VERSION ""

NS_ :

BS_:

BU_: ACCL BGW DBPC DCFL DCFR DCRL DCRR DSM ECPM FBCM FFL FLDC FRDC HLL HLR HUD IHUB LGL PBPC PSM RCLL RCLR RLDC RLSM RRDC RRSM TOOL RCCL RCCR SCAM DEMFL DEMFR DEMRL DEMRR DOSFL DOSFR DOSRL DOSRR

BO_ 1160 DCFR_DemEvent3: 8 DCFR
 SG_ demIRSensor2MIA_DCFR : 57|2@0+ (1,0) [0|0] ""  TOOL
 SG_ demIRSensor1MIA_DCFR : 59|2@0+ (1,0) [0|0] ""  TOOL
 SG_ demWinSwErr_DCFR : 61|2@0+ (1,0) [0|0] ""  TOOL
 SG_ demWinSwMIA_DCFR : 63|2@0+ (1,0) [0|0] ""  TOOL
 SG_ demLINNetworkFail_DCFR : 49|2@0+ (1,0) [0|0] ""  TOOL
 SG_ demBodyCANAmbTempMsgErr_DCFR : 51|2@0+ (1,0) [0|0] ""  TOOL
 SG_ demBodyCANAmbTempMsgMiss_DCFR : 53|2@0+ (1,0) [0|0] ""  TOOL
 SG_ demBodyCANCrashMsgErr_DCFR : 55|2@0+ (1,0) [0|0] ""  TOOL
 SG_ demBodyCANCrashMsgMiss_DCFR : 41|2@0+ (1,0) [0|0] ""  TOOL
 SG_ demBodyCANChildLkMsgErr_DCFR : 43|2@0+ (1,0) [0|0] ""  TOOL
 SG_ demBodyCANChildLkMsgMiss_DCFR : 45|2@0+ (1,0) [0|0] ""  TOOL
 SG_ demBodyCANLockMessageError_DCFR : 47|2@0+ (1,0) [0|0] ""  TOOL
 SG_ demBodyCANLkUnlkMsgMiss_DCFR : 33|2@0+ (1,0) [0|0] ""  TOOL
 SG_ demBodyCANOpClMsgErr_DCFR : 35|2@0+ (1,0) [0|0] ""  TOOL
 SG_ demBodyCANOpClMsgMiss_DCFR : 37|2@0+ (1,0) [0|0] ""  TOOL
 SG_ demBodyCANIMUMessageError_DCFR : 39|2@0+ (1,0) [0|0] ""  TOOL
 SG_ demBodyCANIMUMsgMiss_DCFR : 25|2@0+ (1,0) [0|0] ""  TOOL
 SG_ demBodyCANVehSpdMsgErr_DCFR : 27|2@0+ (1,0) [0|0] ""  TOOL
 SG_ demBodyCANVehSpdMsgMiss_DCFR : 29|2@0+ (1,0) [0|0] ""  TOOL
 SG_ demBodyCANNetworkFailure_DCFR : 31|2@0+ (1,0) [0|0] ""  TOOL
 SG_ demMirrorGlassPosSnsShCir_DCFR : 17|2@0+ (1,0) [0|0] ""  TOOL
 SG_ demMirrorGlassPosSnsOpenCir_DCFR : 19|2@0+ (1,0) [0|0] ""  TOOL
 SG_ demMirrorGlassPosSnsSnEr_DCFR : 21|2@0+ (1,0) [0|0] ""  TOOL
 SG_ demMirrorGlassPosSnsSnLoss_DCFR : 23|2@0+ (1,0) [0|0] ""  TOOL
 SG_ demMirrorGlassPosNotReached_DCFR : 9|2@0+ (1,0) [0|0] ""  TOOL
 SG_ demMirrorGlassMvtUcmd_DCFR : 11|2@0+ (1,0) [0|0] ""  TOOL
 SG_ demMirrorGlassMvFail_DCFR : 13|2@0+ (1,0) [0|0] ""  TOOL
 SG_ demIntOpenSwSnEr_DCFR : 15|2@0+ (1,0) [0|0] ""  TOOL
 SG_ demIntOpenSwSnLoss_DCFR : 1|2@0+ (1,0) [0|0] ""  TOOL
 SG_ demIntRelSwSnEr_DCFR : 3|2@0+ (1,0) [0|0] ""  TOOL
 SG_ demInteriorReleaseSwSnLoss_DCFR : 5|2@0+ (1,0) [0|0] ""  TOOL
 SG_ demDoorUnlockSwSnError_DCFR : 7|2@0+ (1,0) [0|0] ""  TOOL

BO_ 655 DCFR_DemEvent2: 8 DCFR
 SG_ demDoorLockSwitchSignalLoss_DCFR : 57|2@0+ (1,0) [0|0] ""  TOOL
 SG_ demDoorExtCapSwSnEr_DCFR : 59|2@0+ (1,0) [0|0] ""  TOOL
 SG_ demDoorExtCapSwSnLoss_DCFR : 61|2@0+ (1,0) [0|0] ""  TOOL
 SG_ demDoorExtCapSwPower_DCFR : 63|2@0+ (1,0) [0|0] ""  TOOL
 SG_ demDoorExtCapSwNoPower_DCFR : 49|2@0+ (1,0) [0|0] ""  TOOL
 SG_ demDoorExtMechSwSnEr_DCFR : 51|2@0+ (1,0) [0|0] ""  TOOL
 SG_ demDoorExtMechSwSnLoss_DCFR : 53|2@0+ (1,0) [0|0] ""  TOOL
 SG_ demDoorExtMechSwPower_DCFR : 55|2@0+ (1,0) [0|0] ""  TOOL
 SG_ demDoorExtMechSwPowerLoss_DCFR : 41|2@0+ (1,0) [0|0] ""  TOOL
 SG_ demWindowHallSignalError_DCFR : 43|2@0+ (1,0) [0|0] ""  TOOL
 SG_ demWindowHallSnsPowerLoss_DCFR : 45|2@0+ (1,0) [0|0] ""  TOOL
 SG_ demWindowHallSignalLoss_DCFR : 47|2@0+ (1,0) [0|0] ""  TOOL
 SG_ demWindowVelocityTimeout_DCFR : 33|2@0+ (1,0) [0|0] ""  TOOL
 SG_ demCinchCloseSignalError_DCFR : 35|2@0+ (1,0) [0|0] ""  TOOL
 SG_ demReverseCinchTimeout_DCFR : 37|2@0+ (1,0) [0|0] ""  TOOL
 SG_ demCinchOpenSignalError_DCFR : 39|2@0+ (1,0) [0|0] ""  TOOL
 SG_ demDoorCinchTimeout_DCFR : 25|2@0+ (1,0) [0|0] ""  TOOL
 SG_ demDoorLatchOpenAlwaysOn_DCFR : 27|2@0+ (1,0) [0|0] ""  TOOL
 SG_ demDoorLatchOpenPowerLoss_DCFR : 29|2@0+ (1,0) [0|0] ""  TOOL
 SG_ demDoorLatchOpenSignalError_DCFR : 31|2@0+ (1,0) [0|0] ""  TOOL
 SG_ demDoorLatchOpenSignalLoss_DCFR : 17|2@0+ (1,0) [0|0] ""  TOOL
 SG_ demDoorLatchPawlSignalError_DCFR : 19|2@0+ (1,0) [0|0] ""  TOOL
 SG_ demDoorLatchPawlSignalLoss_DCFR : 21|2@0+ (1,0) [0|0] ""  TOOL
 SG_ demDoorLatchSensorSnError_DCFR : 23|2@0+ (1,0) [0|0] ""  TOOL
 SG_ demDoorLatchAjarSigLoss_DCFR : 9|2@0+ (1,0) [0|0] ""  TOOL
 SG_ demDoorBrakeHallSnLoss_DCFR : 11|2@0+ (1,0) [0|0] ""  TOOL
 SG_ demDoorHallSensorSnErr_DCFR : 13|2@0+ (1,0) [0|0] ""  TOOL
 SG_ doorHallSensorSlow_DCFR : 15|2@0+ (1,0) [0|0] ""  TOOL
 SG_ demDoorHallSensorFast_DCFR : 1|2@0+ (1,0) [0|0] ""  TOOL
 SG_ demDoorHallSensorSignalLoss_DCFR : 3|2@0+ (1,0) [0|0] ""  TOOL
 SG_ demMirrorMovetUncmd_DCFR : 5|2@0+ (1,0) [0|0] ""  TOOL
 SG_ demMirrorMovementFailure_DCFR : 7|2@0+ (1,0) [0|0] ""  TOOL

BO_ 654 DCFR_DemEvent1: 8 DCFR
 SG_ demDEMNotification_DCFR : 31|2@0+ (1,0) [0|0] ""  TOOL
 SG_ demDEMAssert_DCFR : 1|2@0+ (1,0) [0|0] ""  TOOL
 SG_ demWindowDownFailure_DCFR : 57|2@0+ (1,0) [0|0] ""  TOOL
 SG_ demWindowDownUncommanded_DCFR : 59|2@0+ (1,0) [0|0] ""  TOOL
 SG_ demWindowUpUncommanded_DCFR : 61|2@0+ (1,0) [0|0] ""  TOOL
 SG_ demWindowUpFailure_DCFR : 63|2@0+ (1,0) [0|0] ""  TOOL
 SG_ demDoorCinchUncommanded_DCFR : 49|2@0+ (1,0) [0|0] ""  TOOL
 SG_ demDoorCinchReleaseFailure_DCFR : 51|2@0+ (1,0) [0|0] ""  TOOL
 SG_ demDoorMovementFault_DCFR : 53|2@0+ (1,0) [0|0] ""  TOOL
 SG_ demDoorCloseUncommanded_DCFR : 55|2@0+ (1,0) [0|0] ""  TOOL
 SG_ demDoorCloseFailure_DCFR : 41|2@0+ (1,0) [0|0] ""  TOOL
 SG_ demLatchTimeout_DCFR : 43|2@0+ (1,0) [0|0] ""  TOOL
 SG_ demDoorDirectionFault_DCFR : 45|2@0+ (1,0) [0|0] ""  TOOL
 SG_ demDoorOpenUncommanded_DCFR : 47|2@0+ (1,0) [0|0] ""  TOOL
 SG_ demDoorOpenFailure_DCFR : 33|2@0+ (1,0) [0|0] ""  TOOL
 SG_ demMirrorMotorSignalLoss_DCFR : 35|2@0+ (1,0) [0|0] ""  TOOL
 SG_ demMirrorMotorOvercurrent_DCFR : 37|2@0+ (1,0) [0|0] ""  TOOL
 SG_ demWindowMotorSignalLoss_DCFR : 39|2@0+ (1,0) [0|0] ""  TOOL
 SG_ demWindowCurrentFailure_DCFR : 25|2@0+ (1,0) [0|0] ""  TOOL
 SG_ demWindowMotorUndercurrent_DCFR : 27|2@0+ (1,0) [0|0] ""  TOOL
 SG_ demWindowMotorOvercurrent_DCFR : 29|2@0+ (1,0) [0|0] ""  TOOL
 SG_ demCinchMotorPowerLoss_DCFR : 17|2@0+ (1,0) [0|0] ""  TOOL
 SG_ demCinchMotorOvercurrent_DCFR : 19|2@0+ (1,0) [0|0] ""  TOOL
 SG_ demLatchUncommandedOpen_DCFR : 21|2@0+ (1,0) [0|0] ""  TOOL
 SG_ demDoorLatchStateError_DCFR : 23|2@0+ (1,0) [0|0] ""  TOOL
 SG_ demDoorLatchPowerLoss_DCFR : 9|2@0+ (1,0) [0|0] ""  TOOL
 SG_ demLatchMotorOvercurrent_DCFR : 11|2@0+ (1,0) [0|0] ""  TOOL
 SG_ demDoorBrakeMotorSignalLoss_DCFR : 13|2@0+ (1,0) [0|0] ""  TOOL
 SG_ demDoorBrakeOvercurrent_DCFR : 15|2@0+ (1,0) [0|0] ""  TOOL
 SG_ demDoorCurrentSignalLoss_DCFR : 3|2@0+ (1,0) [0|0] ""  TOOL
 SG_ demDoorMotorCurrentFailure_DCFR : 5|2@0+ (1,0) [0|0] ""  TOOL
 SG_ demDoorMotorOvercurrent_DCFR : 7|2@0+ (1,0) [0|0] ""  TOOL

BO_ 896 TOOL_OptionSelection: 1 TOOL
 SG_ changeBaudRate_TOOL : 7|3@0+ (1,0) [0|6] ""  ACCL,BGW,DBPC,DCFL,DCFR,DCRL,DCRR,DSM,ECPM,FBCM,FFL,FLDC,FRDC,HLL,HLR,HUD,IHUB,LGL,PBPC,PSM,RCCL,RCCR,RCLL,RCLR,RLDC,RLSM,RRDC,RRSM

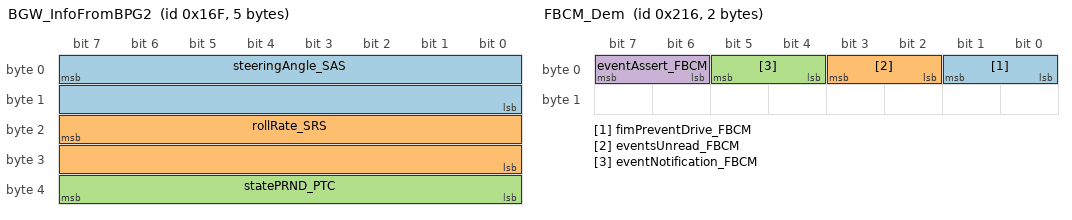
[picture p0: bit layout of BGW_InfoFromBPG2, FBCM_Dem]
BO_ 367 BGW_InfoFromBPG2: 5 BGW
 SG_ steeringAngle_SAS : 7|16@0- (0.1,0) [-780|779.9] "deg"  FBCM
 SG_ rollRate_SRS : 23|16@0+ (0.005,-163.85) [-163.85|163.82] "Grad/s"  DCFL,DCFR,DCRL,DCRR
 SG_ statePRND_PTC : 39|8@0+ (1,0) [0|3] ""  DBPC,DCRL,DCRR,DCFR,DCFL

BO_ 534 FBCM_Dem: 2 FBCM
 SG_ fimPreventDrive_FBCM : 1|2@0+ (1,0) [0|2] ""  TOOL
 SG_ eventsUnread_FBCM : 3|2@0+ (1,0) [0|2] ""  BGW,TOOL
 SG_ eventNotification_FBCM : 5|2@0+ (1,0) [0|2] ""  TOOL
 SG_ eventAssert_FBCM : 7|2@0+ (1,0) [0|2] ""  TOOL

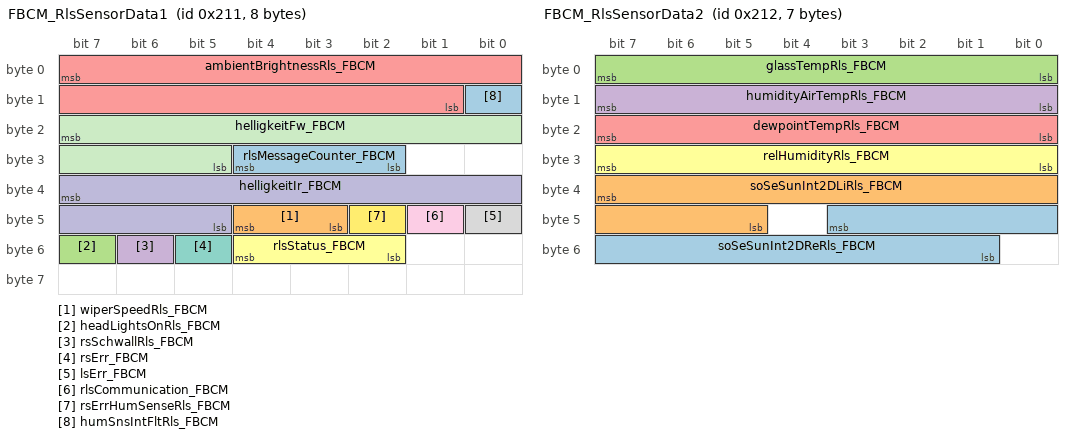
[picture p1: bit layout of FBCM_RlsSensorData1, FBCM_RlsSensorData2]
BO_ 529 FBCM_RlsSensorData1: 8 FBCM
 SG_ rlsMessageCounter_FBCM : 28|3@0+ (1,0) [0|7] ""  BGW
 SG_ wiperSpeedRls_FBCM : 44|2@0+ (1,0) [0|3] ""  BGW
 SG_ headLightsOnRls_FBCM : 55|1@0+ (1,0) [0|1] ""  BGW
 SG_ rsSchwallRls_FBCM : 54|1@0+ (1,0) [0|1] ""  BGW
 SG_ ambientBrightnessRls_FBCM : 7|15@0+ (1,0) [0|2047] ""  BGW
 SG_ rlsStatus_FBCM : 52|3@0+ (1,0) [0|7] ""  BGW
 SG_ rsErr_FBCM : 53|1@0+ (1,0) [0|1] ""  BGW
 SG_ lsErr_FBCM : 40|1@0+ (1,0) [0|1] ""  BGW
 SG_ rlsCommunication_FBCM : 41|1@0+ (1,0) [0|1] ""  BGW
 SG_ helligkeitIr_FBCM : 39|11@0+ (1,0) [0|2047] ""  BGW
 SG_ helligkeitFw_FBCM : 23|11@0+ (1,0) [0|2047] ""  BGW
 SG_ rsErrHumSenseRls_FBCM : 42|1@0+ (1,0) [0|1] ""  BGW
 SG_ humSnsIntFltRls_FBCM : 8|1@0+ (1,0) [0|1] ""  BGW

BO_ 530 FBCM_RlsSensorData2: 7 FBCM
 SG_ soSeSunInt2DReRls_FBCM : 43|11@0+ (1,0) [0|255] ""  BGW
 SG_ soSeSunInt2DLiRls_FBCM : 39|11@0+ (1,0) [0|255] ""  BGW
 SG_ glassTempRls_FBCM : 7|8@0+ (1,0) [0|255] ""  BGW
 SG_ humidityAirTempRls_FBCM : 15|8@0+ (1,0) [0|255] ""  BGW
 SG_ dewpointTempRls_FBCM : 23|8@0+ (1,0) [0|255] ""  BGW
 SG_ relHumidityRls_FBCM : 31|8@0+ (1,0) [0|255] ""  BGW

BO_ 716 DCRR_IMU: 4 DCRR
 SG_ imuRollAngle_DCRR : 23|14@0- (0.022,0) [-180|180] ""  BGW
 SG_ imuPitchAngle_DCRR : 7|14@0- (0.022,0) [-180|180] ""  BGW

BO_ 684 DCRL_IMU: 4 DCRL
 SG_ imuRollAngle_DCRL : 23|14@0- (0.022,0) [-180|180] ""  BGW
 SG_ imuPitchAngle_DCRL : 7|14@0- (0.022,0) [-180|180] ""  BGW

BO_ 652 DCFR_IMU: 4 DCFR
 SG_ imuRollAngle_DCFR : 23|14@0- (0.022,0) [-180|180] ""  BGW
 SG_ imuPitchAngle_DCFR : 7|14@0- (0.022,0) [-180|180] ""  BGW

BO_ 612 DCFL_IMU: 4 DCFL
 SG_ imuRollAngle_DCFL : 23|14@0- (0.022,0) [-180|180] ""  BGW
 SG_ imuPitchAngle_DCFL : 7|14@0- (0.022,0) [-180|180] ""  BGW

BO_ 14 BGW_VehicleIdNumber: 8 BGW
 SG_ vehicleIdNumberLo_BGW m0 : 7|56@0+ (1,0) [0|7.20575940379278E+016] ""  TOOL
 SG_ vehicleIdNumberHi_BGW m2 : 7|24@0+ (1,0) [0|16777214] ""  TOOL
 SG_ vehicleIdNumberIndex_BGW M : 63|2@0+ (1,0) [0|3] ""  TOOL
 SG_ vehicleIdNumberMid_BGW m1 : 7|56@0+ (1,0) [0|7.20575940379278E+016] ""  TOOL

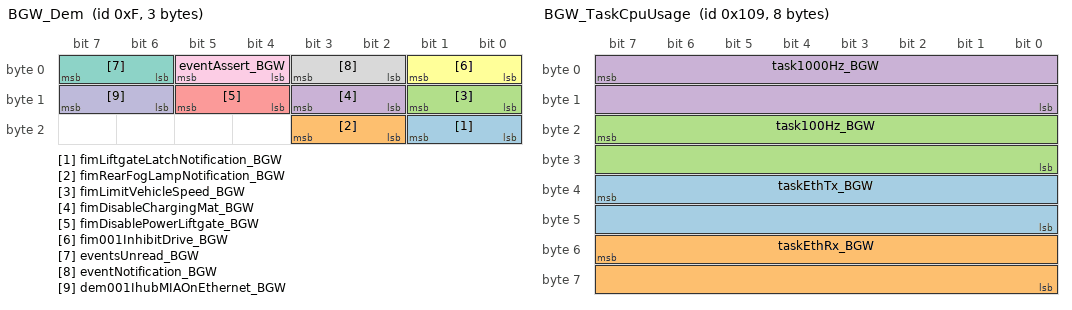
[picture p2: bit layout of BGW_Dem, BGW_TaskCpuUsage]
BO_ 15 BGW_Dem: 3 BGW
 SG_ fimLiftgateLatchNotification_BGW : 17|2@0+ (1,0) [0|2] ""  TOOL
 SG_ fimRearFogLampNotification_BGW : 19|2@0+ (1,0) [0|2] ""  TOOL
 SG_ fimLimitVehicleSpeed_BGW : 9|2@0+ (1,0) [0|2] ""  TOOL
 SG_ fimDisableChargingMat_BGW : 11|2@0+ (1,0) [0|2] ""  TOOL
 SG_ fimDisablePowerLiftgate_BGW : 13|2@0+ (1,0) [0|2] ""  TOOL
 SG_ fim001InhibitDrive_BGW : 1|2@0+ (1,0) [0|2] ""  TOOL
 SG_ eventsUnread_BGW : 7|2@0+ (1,0) [0|2] ""  TOOL
 SG_ eventNotification_BGW : 3|2@0+ (1,0) [0|2] ""  TOOL
 SG_ eventAssert_BGW : 5|2@0+ (1,0) [0|2] ""  TOOL
 SG_ dem001IhubMIAOnEthernet_BGW : 15|2@0+ (1,0) [0|2] ""  TOOL

BO_ 265 BGW_TaskCpuUsage: 8 BGW
 SG_ taskEthTx_BGW : 39|16@0+ (0.01,0) [0|100] "%"  TOOL
 SG_ taskEthRx_BGW : 55|16@0+ (0.01,0) [0|100] "%"  TOOL
 SG_ task100Hz_BGW : 23|16@0+ (0.01,0) [0|100] "%"  TOOL
 SG_ task1000Hz_BGW : 7|16@0+ (0.01,0) [0|100] "%"  TOOL

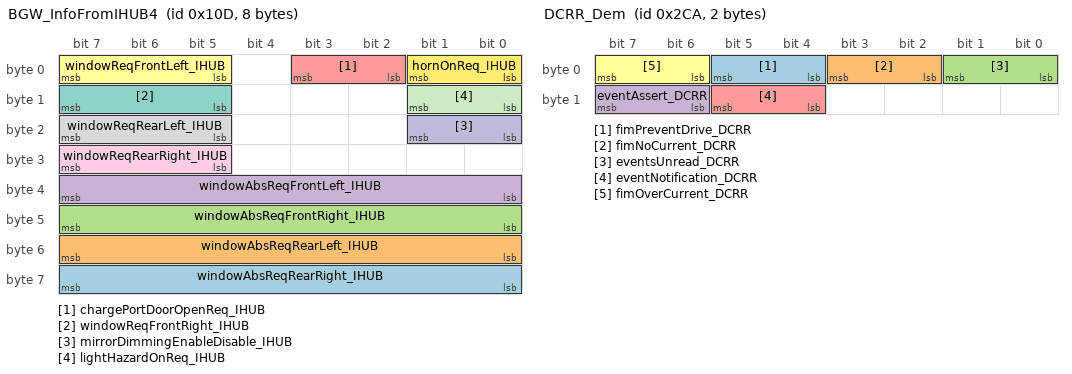
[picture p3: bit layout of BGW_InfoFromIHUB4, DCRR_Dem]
BO_ 269 BGW_InfoFromIHUB4: 8 BGW
 SG_ windowAbsReqRearRight_IHUB : 63|8@0+ (1,0) [0|100] ""  DCRR
 SG_ windowAbsReqRearLeft_IHUB : 55|8@0+ (1,0) [0|100] ""  DCRL
 SG_ windowAbsReqFrontRight_IHUB : 47|8@0+ (1,0) [0|100] ""  DCFR
 SG_ windowAbsReqFrontLeft_IHUB : 39|8@0+ (1,0) [0|100] ""  DCFL
 SG_ chargePortDoorOpenReq_IHUB : 3|2@0+ (1,0) [0|2] ""  FBCM
 SG_ windowReqFrontLeft_IHUB : 7|3@0+ (1,0) [0|4] ""  DCFL
 SG_ windowReqFrontRight_IHUB : 15|3@0+ (1,0) [0|4] ""  DCFR
 SG_ windowReqRearLeft_IHUB : 23|3@0+ (1,0) [0|4] ""  DCRL
 SG_ windowReqRearRight_IHUB : 31|3@0+ (1,0) [0|4] ""  DCRR
 SG_ mirrorDimmingEnableDisable_IHUB : 17|2@0+ (1,0) [0|2] ""  DCFL,DCFR
 SG_ lightHazardOnReq_IHUB : 9|2@0+ (1,0) [0|2] ""  FBCM
 SG_ hornOnReq_IHUB : 1|2@0+ (1,0) [0|2] ""  FBCM

BO_ 714 DCRR_Dem: 2 DCRR
 SG_ fimPreventDrive_DCRR : 5|2@0+ (1,0) [0|2] ""  TOOL
 SG_ fimNoCurrent_DCRR : 3|2@0+ (1,0) [0|2] ""  TOOL
 SG_ eventsUnread_DCRR : 1|2@0+ (1,0) [0|2] ""  BGW,TOOL
 SG_ eventAssert_DCRR : 15|2@0+ (1,0) [0|2] ""  TOOL
 SG_ eventNotification_DCRR : 13|2@0+ (1,0) [0|2] ""  TOOL
 SG_ fimOverCurrent_DCRR : 7|2@0+ (1,0) [0|2] ""  TOOL

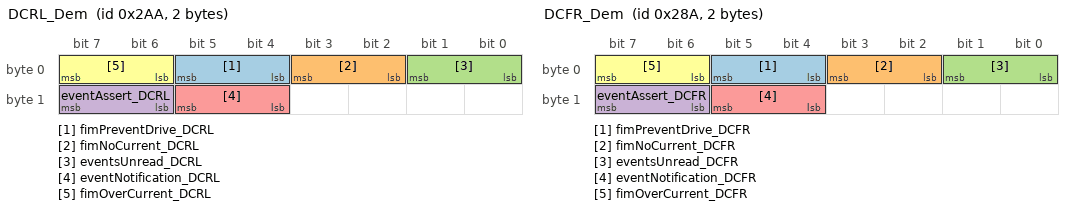
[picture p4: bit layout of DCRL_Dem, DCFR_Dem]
BO_ 682 DCRL_Dem: 2 DCRL
 SG_ fimPreventDrive_DCRL : 5|2@0+ (1,0) [0|2] ""  TOOL
 SG_ fimNoCurrent_DCRL : 3|2@0+ (1,0) [0|2] ""  TOOL
 SG_ eventsUnread_DCRL : 1|2@0+ (1,0) [0|2] ""  BGW,TOOL
 SG_ eventAssert_DCRL : 15|2@0+ (1,0) [0|2] ""  TOOL
 SG_ eventNotification_DCRL : 13|2@0+ (1,0) [0|2] ""  TOOL
 SG_ fimOverCurrent_DCRL : 7|2@0+ (1,0) [0|2] ""  TOOL

BO_ 650 DCFR_Dem: 2 DCFR
 SG_ fimPreventDrive_DCFR : 5|2@0+ (1,0) [0|2] ""  TOOL
 SG_ fimNoCurrent_DCFR : 3|2@0+ (1,0) [0|2] ""  TOOL
 SG_ eventsUnread_DCFR : 1|2@0+ (1,0) [0|2] ""  BGW,TOOL
 SG_ eventAssert_DCFR : 15|2@0+ (1,0) [0|2] ""  TOOL
 SG_ eventNotification_DCFR : 13|2@0+ (1,0) [0|2] ""  TOOL
 SG_ fimOverCurrent_DCFR : 7|2@0+ (1,0) [0|2] ""  TOOL

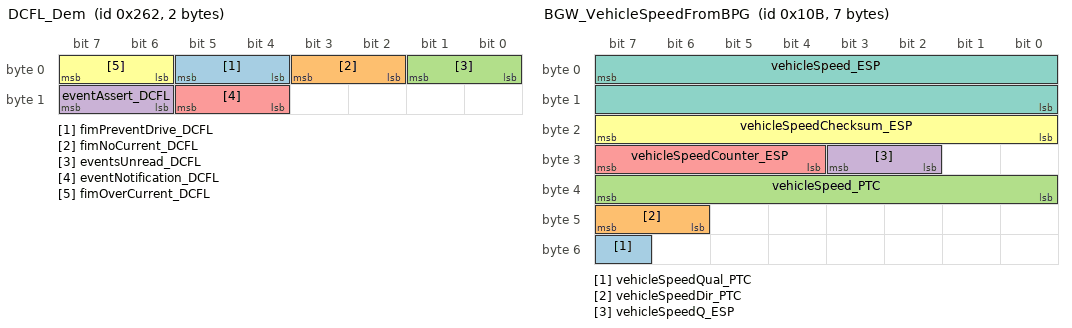
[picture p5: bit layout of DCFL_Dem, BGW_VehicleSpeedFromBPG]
BO_ 610 DCFL_Dem: 2 DCFL
 SG_ fimPreventDrive_DCFL : 5|2@0+ (1,0) [0|2] ""  TOOL
 SG_ fimNoCurrent_DCFL : 3|2@0+ (1,0) [0|2] ""  TOOL
 SG_ eventsUnread_DCFL : 1|2@0+ (1,0) [0|2] ""  BGW,TOOL
 SG_ eventAssert_DCFL : 15|2@0+ (1,0) [0|2] ""  TOOL
 SG_ eventNotification_DCFL : 13|2@0+ (1,0) [0|2] ""  TOOL
 SG_ fimOverCurrent_DCFL : 7|2@0+ (1,0) [0|2] ""  TOOL

BO_ 267 BGW_VehicleSpeedFromBPG: 7 BGW
 SG_ vehicleSpeedQual_PTC : 55|1@0+ (1,0) [0|1] ""  DCFL,DCFR,DCRL,DCRR
 SG_ vehicleSpeedDir_PTC : 47|2@0+ (1,0) [0|1] ""  DCFL,DCFR,DCRL,DCRR
 SG_ vehicleSpeed_PTC : 39|8@0+ (1,0) [0|254] ""  DCFL,DCFR,DCRL,DCRR
 SG_ vehicleSpeedQ_ESP : 27|2@0+ (1,0) [0|3] ""  DCFL,DCFR,DCRL,DCRR
 SG_ vehicleSpeedCounter_ESP : 31|4@0+ (1,0) [0|15] ""  DCFL,DCFR,DCRL,DCRR
 SG_ vehicleSpeedChecksum_ESP : 23|8@0+ (1,0) [0|255] ""  DCFL,DCFR,DCRL,DCRR
 SG_ vehicleSpeed_ESP : 7|16@0+ (0.01,0) [0|655.34] "km/h"  ECPM,FBCM,DCFL,DCFR,DCRL,DCRR

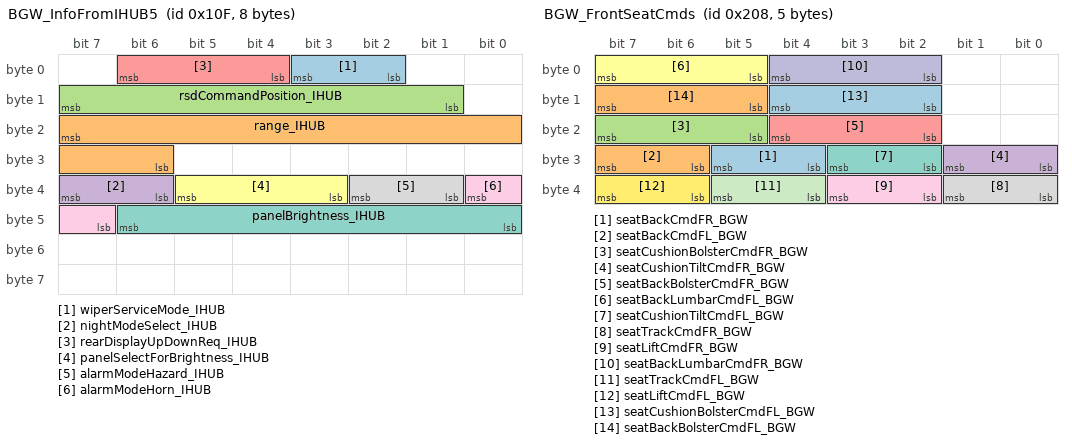
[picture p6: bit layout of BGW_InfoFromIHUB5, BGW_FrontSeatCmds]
BO_ 271 BGW_InfoFromIHUB5: 8 BGW
 SG_ wiperServiceMode_IHUB : 3|2@0+ (1,0) [0|0] ""  FBCM
 SG_ range_IHUB : 23|10@0+ (1,0) [0|800] "miles"  DBPC
 SG_ rsdCommandPosition_IHUB : 15|7@0+ (1,0) [0|105] ""  FBCM
 SG_ nightModeSelect_IHUB : 39|2@0+ (1,0) [0|1] ""  DBPC,ECPM
 SG_ rearDisplayUpDownReq_IHUB : 6|3@0+ (1,0) [0|7] ""  FBCM
 SG_ panelSelectForBrightness_IHUB : 37|3@0+ (1,0) [0|6] ""  DBPC
 SG_ panelBrightness_IHUB : 46|7@0+ (1,0) [0|100] ""  ECPM,DBPC
 SG_ alarmModeHazard_IHUB : 34|2@0+ (1,0) [0|2] ""  FBCM
 SG_ alarmModeHorn_IHUB : 32|2@0+ (1,0) [0|2] ""  FBCM

BO_ 520 BGW_FrontSeatCmds: 5 BGW
 SG_ seatBackCmdFR_BGW : 29|2@0+ (1,0) [0|0] ""  PSM
 SG_ seatBackCmdFL_BGW : 31|2@0+ (1,0) [0|0] ""  DSM
 SG_ seatCushionBolsterCmdFR_BGW : 23|3@0+ (1,0) [0|0] ""  PSM
 SG_ seatCushionTiltCmdFR_BGW : 25|2@0+ (1,0) [0|0] ""  PSM
 SG_ seatBackBolsterCmdFR_BGW : 20|3@0+ (1,0) [0|0] ""  PSM
 SG_ seatBackLumbarCmdFL_BGW : 7|3@0+ (1,0) [0|0] ""  DSM
 SG_ seatCushionTiltCmdFL_BGW : 27|2@0+ (1,0) [0|0] ""  DSM
 SG_ seatTrackCmdFR_BGW : 33|2@0+ (1,0) [0|2] ""  PSM
 SG_ seatLiftCmdFR_BGW : 35|2@0+ (1,0) [0|2] ""  PSM
 SG_ seatBackLumbarCmdFR_BGW : 4|3@0+ (1,0) [0|2] ""  PSM
 SG_ seatTrackCmdFL_BGW : 37|2@0+ (1,0) [0|2] ""  DSM
 SG_ seatLiftCmdFL_BGW : 39|2@0+ (1,0) [0|2] ""  DSM
 SG_ seatCushionBolsterCmdFL_BGW : 12|3@0+ (1,0) [0|4] ""  DSM
 SG_ seatBackBolsterCmdFL_BGW : 15|3@0+ (1,0) [0|4] ""  DSM

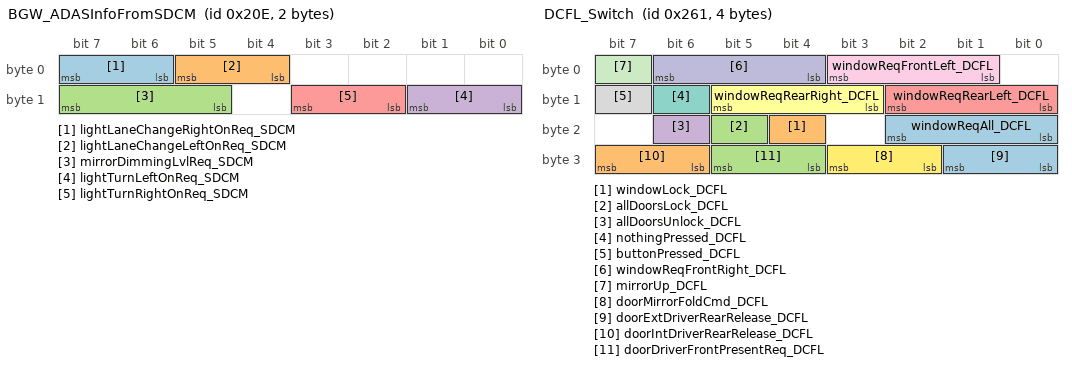
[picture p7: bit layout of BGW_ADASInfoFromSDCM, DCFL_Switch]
BO_ 526 BGW_ADASInfoFromSDCM: 2 BGW
 SG_ lightLaneChangeRightOnReq_SDCM : 7|2@0+ (1,0) [0|2] ""  FBCM
 SG_ lightLaneChangeLeftOnReq_SDCM : 5|2@0+ (1,0) [0|2] ""  FBCM
 SG_ mirrorDimmingLvlReq_SDCM : 15|3@0+ (1,0) [0|6] ""  DCFL,DCFR
 SG_ lightTurnLeftOnReq_SDCM : 9|2@0+ (1,0) [0|6] ""  FBCM
 SG_ lightTurnRightOnReq_SDCM : 11|2@0+ (1,0) [0|6] ""  FBCM

BO_ 608 DCFL_Status: 8 DCFL
 SG_ doorLockReq_DCFL : 55|2@0+ (1,0) [0|2] ""  BGW
 SG_ lockUnlockReq_FLLUS : 41|2@0+ (1,0) [0|2] ""  BGW
 SG_ doorSafeMode_DCFL : 53|2@0+ (1,0) [0|0] ""  FBCM,BGW
 SG_ doorLatchPawlOpen_DCFL : 48|2@0+ (1,0) [0|0] ""  TOOL
 SG_ doorLatchFault_DCFL : 23|2@0+ (1,0) [0|2] ""  BGW
 SG_ childLockButtonState_DCFL : 21|2@0+ (1,0) [0|2] ""  BGW,DCFL,DCFR,DCRL,DCRR
 SG_ doorIsUnlatched_DCFL : 31|2@0+ (1,0) [0|2] ""  HUD,FBCM,BGW,DCFR,DCRR,DCRL,IHUB
 SG_ doorExtSwitch_DCFL : 9|2@0+ (1,0) [0|2] ""  BGW
 SG_ doorMirrorState_DCFL : 7|3@0+ (1,0) [0|6] ""  ECPM,BGW
 SG_ doorState_DCFL : 13|4@0+ (1,0) [0|9] ""  ECPM,FBCM,BGW,DBPC
 SG_ mirrorHeaterState_DCFL : 15|2@0+ (1,0) [0|2] ""  ECPM,BGW
 SG_ sideRepeaterState_DCFL : 2|2@0+ (1,0) [0|2] ""  BGW
 SG_ doorDTCPresent_DCFL : 4|2@0+ (1,0) [0|2] ""  BGW
 SG_ windowStatusFl_DCFL : 19|3@0+ (1,0) [0|6] ""  BGW
 SG_ mirrorFoldFeedbackLeft_DCFL : 29|2@0+ (1,0) [0|2] ""  BGW
 SG_ mirrorDefrostGlassStatusLh_DCFL : 27|2@0+ (1,0) [0|2] ""  BGW
 SG_ mirrorStatusMovUpDownLeft_DCFL : 39|2@0+ (1,0) [0|2] ""  BGW
 SG_ mirrorStatusMovInOutLeft_DCFL : 37|2@0+ (1,0) [0|2] ""  BGW
 SG_ mirrorDefrostCamStatusLeft_DCFL : 35|2@0+ (1,0) [0|2] ""  BGW
 SG_ mirrorFoldAutoStatusLeft_DCFL : 25|2@0+ (1,0) [0|2] ""  BGW
 SG_ mirrorDimEnabDisableStatus_DCFL : 33|2@0+ (1,0) [0|2] ""  BGW
 SG_ errorAMPFL_DCFL : 16|1@0+ (1,0) [0|1] ""  BGW
 SG_ errorALDFL_DCFL : 0|1@0+ (1,0) [0|1] ""  BGW
 SG_ doorAngle_DCFL : 47|6@0- (2,40) [-24|100] "degrees"  BGW
 SG_ doorAngleMax_DCFL : 62|7@0+ (1,0) [0|126] "degrees"  BGW
 SG_ wakeUpCause_DCFL : 51|3@0+ (1,0) [0|7] ""  TOOL

BO_ 609 DCFL_Switch: 4 DCFL
 SG_ windowReqAll_DCFL : 18|3@0+ (1,0) [0|6] ""  DCRR,DCRL,DCFR,DCFL,TOOL
 SG_ windowLock_DCFL : 20|1@0+ (1,0) [0|1] ""  DCRR,DCRL,DCFR,DCFL,TOOL
 SG_ allDoorsLock_DCFL : 21|1@0+ (1,0) [0|1] ""  DCRR,DCRL,DCFR,DCFL,TOOL
 SG_ allDoorsUnlock_DCFL : 22|1@0+ (1,0) [0|1] ""  DCRR,DCRL,DCFR,DCFL,TOOL
 SG_ windowReqRearLeft_DCFL : 10|3@0+ (1,0) [0|6] ""  DCRR,DCFR,DCFL,DCRL
 SG_ windowReqRearRight_DCFL : 13|3@0+ (1,0) [0|6] ""  DCRL,DCFR,DCFL,DCRR
 SG_ nothingPressed_DCFL : 14|1@0+ (1,0) [0|1] ""  DCRR,DCRL,DCFR,DCFL,TOOL
 SG_ buttonPressed_DCFL : 15|1@0+ (1,0) [0|1] ""  DCRR,DCRL,DCFR,DCFL,TOOL
 SG_ windowReqFrontLeft_DCFL : 3|3@0+ (1,0) [0|6] ""  DCRR,DCRL,DCFR,DCFL,BGW
 SG_ windowReqFrontRight_DCFL : 6|3@0+ (1,0) [0|6] ""  DCRR,DCRL,DCFR,DCFL,BGW
 SG_ mirrorUp_DCFL : 7|1@0+ (1,0) [0|1] ""  DCRR,DCRL,DCFR,DCFL,TOOL
 SG_ doorMirrorFoldCmd_DCFL : 27|2@0+ (1,0) [0|2] ""  DCRR,DCRL,DCFL,BGW,DCFR
 SG_ doorExtDriverRearRelease_DCFL : 25|2@0+ (1,0) [0|2] ""  DCRR,DCRL,DCFR,DCFL,BGW,FBCM
 SG_ doorIntDriverRearRelease_DCFL : 31|2@0+ (1,0) [0|2] ""  DCRR,DCRL,DCFR,DCFL,BGW,FBCM
 SG_ doorDriverFrontPresentReq_DCFL : 29|2@0+ (1,0) [0|2] ""  DCRR,DCRL,DCFR,DCFL,BGW,FBCM

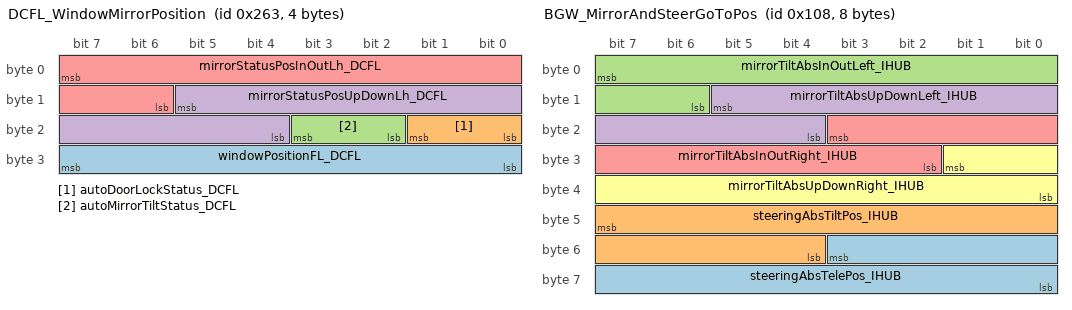
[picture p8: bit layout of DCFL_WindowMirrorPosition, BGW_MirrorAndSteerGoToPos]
BO_ 611 DCFL_WindowMirrorPosition: 4 DCFL
 SG_ windowPositionFL_DCFL : 31|8@0+ (1,0) [0|100] ""  BGW
 SG_ autoDoorLockStatus_DCFL : 17|2@0+ (1,0) [0|0] ""  BGW
 SG_ autoMirrorTiltStatus_DCFL : 19|2@0+ (1,0) [0|0] ""  BGW
 SG_ mirrorStatusPosUpDownLh_DCFL : 13|10@0+ (0.1,-38) [-38|38] "degrees"  BGW
 SG_ mirrorStatusPosInOutLh_DCFL : 7|10@0+ (0.1,-38) [-38|38] "degrees"  BGW

BO_ 264 BGW_MirrorAndSteerGoToPos: 8 BGW
 SG_ steeringAbsTelePos_IHUB : 51|12@0+ (1,0) [0|4095] "HallCounts"  FBCM
 SG_ steeringAbsTiltPos_IHUB : 47|12@0+ (1,0) [0|4095] "HallCounts"  FBCM
 SG_ mirrorTiltAbsInOutLeft_IHUB : 7|10@0+ (0.1,-38) [-38|38] "degrees"  DCFR,DCFL
 SG_ mirrorTiltAbsUpDownLeft_IHUB : 13|10@0+ (0.1,-38) [-38|38] "degrees"  DCFR,DCFL
 SG_ mirrorTiltAbsInOutRight_IHUB : 19|10@0+ (0.1,-38) [-38|38] "degrees"  DCFL,DCFR
 SG_ mirrorTiltAbsUpDownRight_IHUB : 25|10@0+ (0.1,-38) [-38|38] "degrees"  DCFR,DCFL

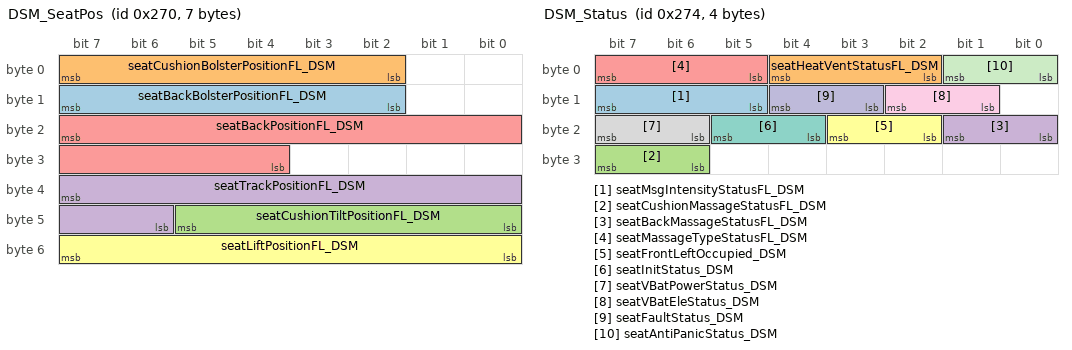
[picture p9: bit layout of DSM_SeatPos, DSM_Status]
BO_ 624 DSM_SeatPos: 7 DSM
 SG_ seatBackBolsterPositionFL_DSM : 15|6@0+ (0.1,0.4) [0.4|2.4] "V"  BGW
 SG_ seatCushionBolsterPositionFL_DSM : 7|6@0+ (0.1,0.4) [0.4|2.4] "V"  BGW
 SG_ seatCushionTiltPositionFL_DSM : 45|6@0+ (0.1,0) [0|6] "degrees"  BGW
 SG_ seatTrackPositionFL_DSM : 39|10@0- (1,0) [-75|185] "mm"  BGW
 SG_ seatBackPositionFL_DSM : 23|12@0- (0.1,0) [-22|43] "degrees"  BGW
 SG_ seatLiftPositionFL_DSM : 55|8@0- (1,0) [-20|54] "mm"  BGW

BO_ 628 DSM_Status: 4 DSM
 SG_ seatMsgIntensityStatusFL_DSM : 15|3@0+ (1,0) [0|0] ""  BGW
 SG_ seatHeatVentStatusFL_DSM : 4|3@0+ (1,0) [0|0] ""  BGW
 SG_ seatCushionMassageStatusFL_DSM : 31|2@0+ (1,0) [0|0] ""  BGW
 SG_ seatBackMassageStatusFL_DSM : 17|2@0+ (1,0) [0|0] ""  BGW
 SG_ seatMassageTypeStatusFL_DSM : 7|3@0+ (1,0) [0|0] ""  BGW
 SG_ seatFrontLeftOccupied_DSM : 19|2@0+ (1,0) [0|1] ""  HUD,FBCM,DCFL,BGW,IHUB
 SG_ seatInitStatus_DSM : 21|2@0+ (1,0) [0|2] ""  BGW
 SG_ seatVBatPowerStatus_DSM : 23|2@0+ (1,0) [0|1] ""  BGW
 SG_ seatVBatEleStatus_DSM : 10|2@0+ (1,0) [0|1] ""  BGW
 SG_ seatFaultStatus_DSM : 12|2@0+ (1,0) [0|2] ""  BGW
 SG_ seatAntiPanicStatus_DSM : 1|2@0+ (1,0) [0|2] ""  BGW

BO_ 648 DCFR_Status: 8 DCFR
 SG_ doorLockReq_DCFR : 55|2@0+ (1,0) [0|2] ""  BGW
 SG_ lockUnlockReq_FRLUS : 41|2@0+ (1,0) [0|2] ""  BGW
 SG_ doorSafeMode_DCFR : 53|2@0+ (1,0) [0|0] ""  FBCM,BGW
 SG_ doorLatchPawlOpen_DCFR : 48|2@0+ (1,0) [0|3] ""  TOOL
 SG_ doorLatchFault_DCFR : 23|2@0+ (1,0) [0|2] ""  BGW
 SG_ childLockButtonState_DCFR : 21|2@0+ (1,0) [0|2] ""  DCFL,DCFR,DCRL,DCRR,BGW
 SG_ doorIsUnlatched_DCFR : 31|2@0+ (1,0) [0|2] ""  HUD,FBCM,BGW,DCFL,DCRR,DCRL,IHUB
 SG_ doorExtSwitch_DCFR : 9|2@0+ (1,0) [0|2] ""  BGW
 SG_ doorMirrorState_DCFR : 7|3@0+ (1,0) [0|6] ""  ECPM,BGW
 SG_ doorState_DCFR : 13|4@0+ (1,0) [0|9] ""  ECPM,FBCM,BGW,DBPC
 SG_ mirrorHeaterState_DCFR : 15|2@0+ (1,0) [0|2] ""  ECPM,BGW
 SG_ sideRepeaterState_DCFR : 2|2@0+ (1,0) [0|2] ""  BGW
 SG_ doorDTCPresent_DCFR : 4|2@0+ (1,0) [0|2] ""  BGW
 SG_ windowStatusFr_DCFR : 19|3@0+ (1,0) [0|6] ""  BGW
 SG_ mirrorFoldFeedbackRight_DCFR : 29|2@0+ (1,0) [0|2] ""  BGW
 SG_ mirrorDefrostGlassStatusRh_DCFR : 27|2@0+ (1,0) [0|2] ""  BGW
 SG_ mirrorStatusMovUpDownRight_DCFR : 39|2@0+ (1,0) [0|2] ""  BGW
 SG_ mirrorStatusMovInOutRight_DCFR : 37|2@0+ (1,0) [0|2] ""  BGW
 SG_ mirrorDefrostCamStatusRight_DCFR : 35|2@0+ (1,0) [0|2] ""  BGW
 SG_ mirrorFoldAutoStatusRight_DCFR : 25|2@0+ (1,0) [0|2] ""  BGW
 SG_ mirrorDimEnabDisableStatus_DCFR : 33|2@0+ (1,0) [0|2] ""  BGW
 SG_ errorAMPFR_DCFR : 16|1@0+ (1,0) [0|1] ""  BGW
 SG_ errorALDFR_DCFR : 0|1@0+ (1,0) [0|1] ""  BGW
 SG_ doorAngle_DCFR : 47|6@0- (2,40) [-24|100] "degrees"  BGW
 SG_ doorAngleMax_DCFR : 62|7@0+ (1,0) [0|126] "degrees"  BGW
 SG_ wakeUpCause_DCFR : 51|3@0+ (1,0) [0|7] ""  TOOL

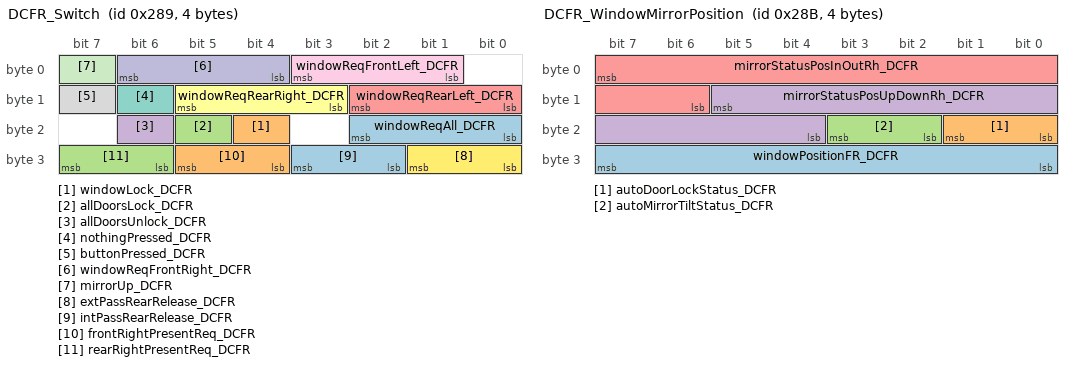
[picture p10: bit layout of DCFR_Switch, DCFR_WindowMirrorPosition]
BO_ 649 DCFR_Switch: 4 DCFR
 SG_ windowReqAll_DCFR : 18|3@0+ (1,0) [0|6] ""  DCRR,DCRL,DCFR,DCFL,TOOL
 SG_ windowLock_DCFR : 20|1@0+ (1,0) [0|1] ""  DCRR,DCRL,DCFR,DCFL,TOOL
 SG_ allDoorsLock_DCFR : 21|1@0+ (1,0) [0|1] ""  DCRR,DCRL,DCFR,DCFL,TOOL
 SG_ allDoorsUnlock_DCFR : 22|1@0+ (1,0) [0|1] ""  DCRR,DCRL,DCFR,DCFL,TOOL
 SG_ windowReqRearLeft_DCFR : 10|3@0+ (1,0) [0|6] ""  DCRR,DCFR,DCFL,DCRL
 SG_ windowReqRearRight_DCFR : 13|3@0+ (1,0) [0|6] ""  DCRL,DCFR,DCFL,DCRR
 SG_ nothingPressed_DCFR : 14|1@0+ (1,0) [0|1] ""  DCRR,DCRL,DCFR,DCFL,TOOL
 SG_ buttonPressed_DCFR : 15|1@0+ (1,0) [0|1] ""  DCRR,DCRL,DCFR,DCFL,TOOL
 SG_ windowReqFrontLeft_DCFR : 3|3@0+ (1,0) [0|6] ""  DCRR,DCRL,DCFR,DCFL,BGW
 SG_ windowReqFrontRight_DCFR : 6|3@0+ (1,0) [0|6] ""  DCRR,DCRL,DCFR,DCFL,BGW,TOOL
 SG_ mirrorUp_DCFR : 7|1@0+ (1,0) [0|1] ""  DCRR,DCRL,DCFR,DCFL,TOOL
 SG_ extPassRearRelease_DCFR : 25|2@0+ (1,0) [0|2] ""  DCRR,DCRL,DCFR,DCFL,FBCM
 SG_ intPassRearRelease_DCFR : 27|2@0+ (1,0) [0|2] ""  DCRR,DCRL,DCFR,DCFL,FBCM
 SG_ frontRightPresentReq_DCFR : 29|2@0+ (1,0) [0|2] ""  DCRR,DCRL,DCFR,DCFL,FBCM
 SG_ rearRightPresentReq_DCFR : 31|2@0+ (1,0) [0|2] ""  DCRR,DCRL,DCFR,DCFL,FBCM

BO_ 651 DCFR_WindowMirrorPosition: 4 DCFR
 SG_ windowPositionFR_DCFR : 31|8@0+ (1,0) [0|100] ""  BGW
 SG_ autoDoorLockStatus_DCFR : 17|2@0+ (1,0) [0|0] ""  BGW
 SG_ autoMirrorTiltStatus_DCFR : 19|2@0+ (1,0) [0|0] ""  BGW
 SG_ mirrorStatusPosUpDownRh_DCFR : 13|10@0+ (0.1,-38) [-38|38] "degrees"  BGW
 SG_ mirrorStatusPosInOutRh_DCFR : 7|10@0+ (0.1,-38) [-38|38] "degrees"  BGW

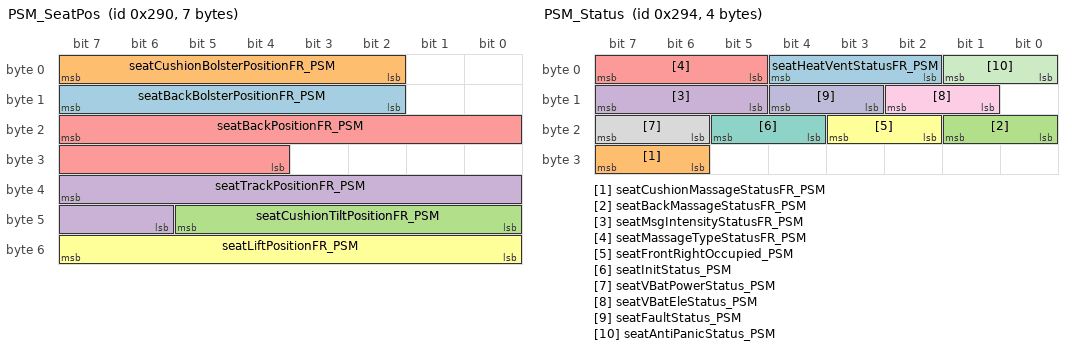
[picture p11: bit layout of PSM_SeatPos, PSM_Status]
BO_ 656 PSM_SeatPos: 7 PSM
 SG_ seatBackBolsterPositionFR_PSM : 15|6@0+ (0.1,0.4) [0.4|2.4] "V"  BGW
 SG_ seatCushionBolsterPositionFR_PSM : 7|6@0+ (0.1,0.4) [0.4|2.4] "V"  BGW
 SG_ seatCushionTiltPositionFR_PSM : 45|6@0+ (0.1,0) [0|6] "degrees"  BGW
 SG_ seatTrackPositionFR_PSM : 39|10@0- (1,0) [-75|185] "mm"  BGW
 SG_ seatBackPositionFR_PSM : 23|12@0- (0.1,0) [-20|54] "degrees"  BGW
 SG_ seatLiftPositionFR_PSM : 55|8@0- (1,0) [-22|43] "mm"  BGW

BO_ 660 PSM_Status: 4 PSM
 SG_ seatHeatVentStatusFR_PSM : 4|3@0+ (1,0) [0|0] ""  BGW
 SG_ seatCushionMassageStatusFR_PSM : 31|2@0+ (1,0) [0|0] ""  BGW
 SG_ seatBackMassageStatusFR_PSM : 17|2@0+ (1,0) [0|0] ""  BGW
 SG_ seatMsgIntensityStatusFR_PSM : 15|3@0+ (1,0) [0|0] ""  BGW
 SG_ seatMassageTypeStatusFR_PSM : 7|3@0+ (1,0) [0|0] ""  BGW
 SG_ seatFrontRightOccupied_PSM : 19|2@0+ (1,0) [0|1] ""  HUD,BGW,IHUB
 SG_ seatInitStatus_PSM : 21|2@0+ (1,0) [0|2] ""  BGW
 SG_ seatVBatPowerStatus_PSM : 23|2@0+ (1,0) [0|1] ""  BGW
 SG_ seatVBatEleStatus_PSM : 10|2@0+ (1,0) [0|1] ""  BGW
 SG_ seatFaultStatus_PSM : 12|2@0+ (1,0) [0|2] ""  BGW
 SG_ seatAntiPanicStatus_PSM : 1|2@0+ (1,0) [0|2] ""  BGW

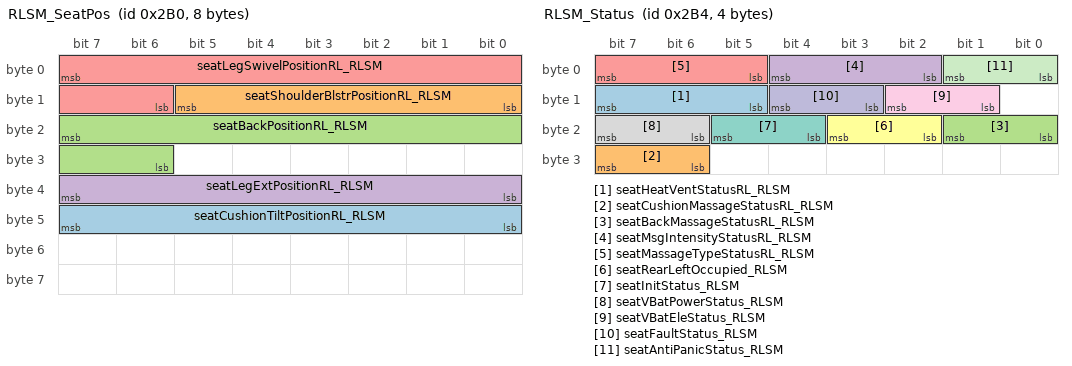
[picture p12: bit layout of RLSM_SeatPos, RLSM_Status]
BO_ 688 RLSM_SeatPos: 8 RLSM
 SG_ seatCushionTiltPositionRL_RLSM : 47|8@0+ (1,0) [0|20] "degrees"  BGW
 SG_ seatShoulderBlstrPositionRL_RLSM : 13|6@0+ (0.1,0.4) [0.4|2.4] "V"  BGW
 SG_ seatBackPositionRL_RLSM : 23|10@0- (0.1,0) [-8|32] "degrees"  BGW
 SG_ seatLegExtPositionRL_RLSM : 39|8@0+ (1,0) [0|130] "mm"  BGW
 SG_ seatLegSwivelPositionRL_RLSM : 7|10@0+ (0.1,0) [0|72.5] "degrees"  BGW

BO_ 692 RLSM_Status: 4 RLSM
 SG_ seatHeatVentStatusRL_RLSM : 15|3@0+ (1,0) [0|0] ""  BGW
 SG_ seatCushionMassageStatusRL_RLSM : 31|2@0+ (1,0) [0|0] ""  BGW
 SG_ seatBackMassageStatusRL_RLSM : 17|2@0+ (1,0) [0|0] ""  BGW
 SG_ seatMsgIntensityStatusRL_RLSM : 4|3@0+ (1,0) [0|0] ""  BGW
 SG_ seatMassageTypeStatusRL_RLSM : 7|3@0+ (1,0) [0|0] ""  BGW
 SG_ seatRearLeftOccupied_RLSM : 19|2@0+ (1,0) [0|1] ""  IHUB,HUD,BGW
 SG_ seatInitStatus_RLSM : 21|2@0+ (1,0) [0|2] ""  BGW
 SG_ seatVBatPowerStatus_RLSM : 23|2@0+ (1,0) [0|1] ""  BGW
 SG_ seatVBatEleStatus_RLSM : 10|2@0+ (1,0) [0|1] ""  BGW
 SG_ seatFaultStatus_RLSM : 12|2@0+ (1,0) [0|2] ""  BGW
 SG_ seatAntiPanicStatus_RLSM : 1|2@0+ (1,0) [0|2] ""  BGW

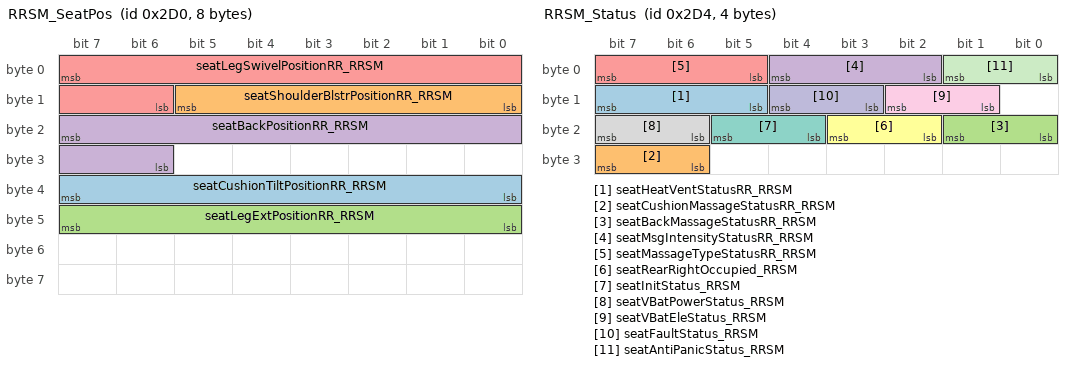
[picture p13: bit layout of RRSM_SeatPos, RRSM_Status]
BO_ 720 RRSM_SeatPos: 8 RRSM
 SG_ seatCushionTiltPositionRR_RRSM : 39|8@0+ (1,0) [0|20] "degrees"  BGW
 SG_ seatShoulderBlstrPositionRR_RRSM : 13|6@0+ (0.1,0.4) [0.4|2.4] "V"  BGW
 SG_ seatLegExtPositionRR_RRSM : 47|8@0+ (1,0) [0|130] "mm"  BGW
 SG_ seatBackPositionRR_RRSM : 23|10@0- (0.1,0) [-8|32] "degrees"  BGW
 SG_ seatLegSwivelPositionRR_RRSM : 7|10@0+ (0.1,0) [0|72.5] "degrees"  BGW

BO_ 724 RRSM_Status: 4 RRSM
 SG_ seatHeatVentStatusRR_RRSM : 15|3@0+ (1,0) [0|0] ""  BGW
 SG_ seatCushionMassageStatusRR_RRSM : 31|2@0+ (1,0) [0|0] ""  BGW
 SG_ seatBackMassageStatusRR_RRSM : 17|2@0+ (1,0) [0|0] ""  BGW
 SG_ seatMsgIntensityStatusRR_RRSM : 4|3@0+ (1,0) [0|0] ""  BGW
 SG_ seatMassageTypeStatusRR_RRSM : 7|3@0+ (1,0) [0|0] ""  BGW
 SG_ seatRearRightOccupied_RRSM : 19|2@0+ (1,0) [0|1] ""  IHUB,HUD,BGW
 SG_ seatInitStatus_RRSM : 21|2@0+ (1,0) [0|2] ""  BGW
 SG_ seatVBatPowerStatus_RRSM : 23|2@0+ (1,0) [0|1] ""  BGW
 SG_ seatVBatEleStatus_RRSM : 10|2@0+ (1,0) [0|1] ""  BGW
 SG_ seatFaultStatus_RRSM : 12|2@0+ (1,0) [0|2] ""  BGW
 SG_ seatAntiPanicStatus_RRSM : 1|2@0+ (1,0) [0|2] ""  BGW

BO_ 779 BGW_AestheticLightingCmd: 3 BGW
 SG_ sequenceId_BGW : 15|8@0+ (1,0) [0|254] ""  RRDC,RLDC,FRDC,FLDC,FFL,HLL,HLR,ACCL,LGL,RCLR,RCLL

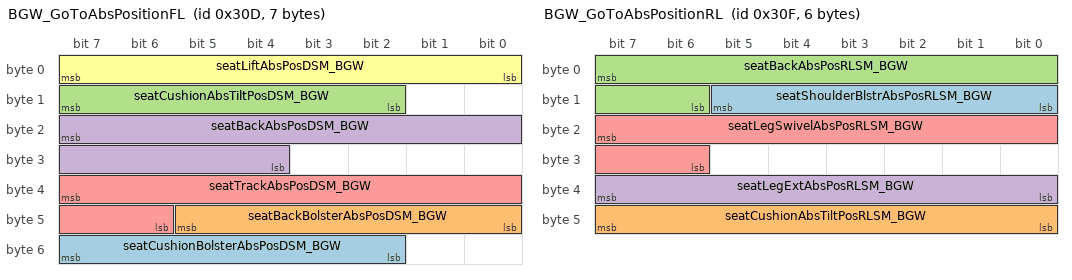
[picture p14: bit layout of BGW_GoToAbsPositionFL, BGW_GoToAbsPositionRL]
BO_ 781 BGW_GoToAbsPositionFL: 7 BGW
 SG_ seatCushionBolsterAbsPosDSM_BGW : 55|6@0+ (0.1,0.4) [0.4|2.4] "V"  DSM
 SG_ seatBackBolsterAbsPosDSM_BGW : 45|6@0+ (0.1,0.4) [0.4|2.4] "V"  DSM
 SG_ seatCushionAbsTiltPosDSM_BGW : 15|6@0+ (0.1,0) [0|6] "degrees"  DSM
 SG_ seatBackAbsPosDSM_BGW : 23|12@0- (0.1,0) [-20|54] "degrees"  DSM
 SG_ seatTrackAbsPosDSM_BGW : 39|10@0- (1,0) [-75|185] "mm"  DSM
 SG_ seatLiftAbsPosDSM_BGW : 7|8@0- (1,0) [-22|43] "mm"  DSM

BO_ 783 BGW_GoToAbsPositionRL: 6 BGW
 SG_ seatShoulderBlstrAbsPosRLSM_BGW : 13|6@0+ (0.1,0.4) [0.4|2.4] "V"  RLSM
 SG_ seatCushionAbsTiltPosRLSM_BGW : 47|8@0+ (0.1,0) [0|20] "degrees"  RLSM
 SG_ seatBackAbsPosRLSM_BGW : 7|10@0- (0.1,0) [-32|8] "degrees"  RLSM
 SG_ seatLegExtAbsPosRLSM_BGW : 39|8@0+ (1,0) [0|130] "mm"  RLSM
 SG_ seatLegSwivelAbsPosRLSM_BGW : 23|10@0+ (0.1,0) [0|72.5] "degrees"  RLSM

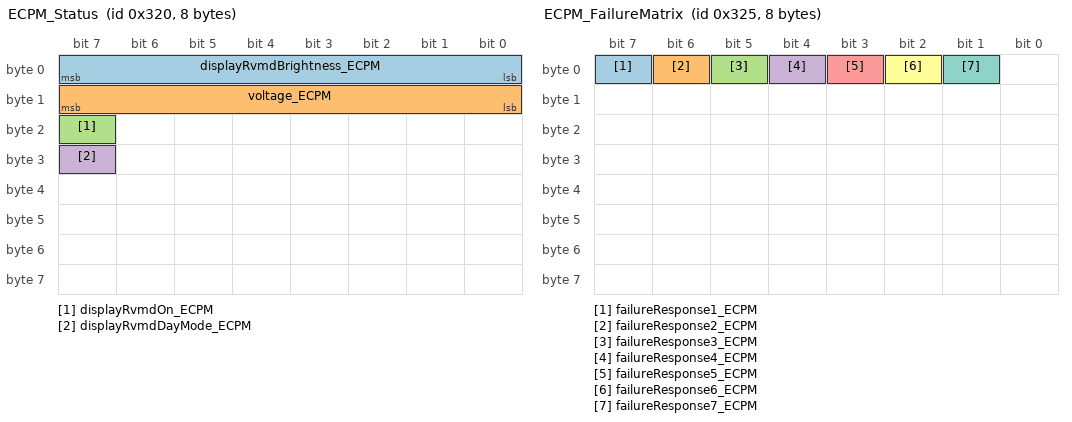
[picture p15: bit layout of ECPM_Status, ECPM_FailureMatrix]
BO_ 800 ECPM_Status: 8 ECPM
 SG_ displayRvmdBrightness_ECPM : 7|8@0+ (1,0) [0|100] ""  TOOL
 SG_ voltage_ECPM : 15|8@0+ (0.1,0) [0|25.4] ""  TOOL
 SG_ displayRvmdOn_ECPM : 23|1@0+ (1,0) [0|1] ""  TOOL
 SG_ displayRvmdDayMode_ECPM : 31|1@0+ (1,0) [0|1] ""  TOOL

BO_ 801 ECPM_DtcMatrix: 8 ECPM

BO_ 805 ECPM_FailureMatrix: 8 ECPM
 SG_ failureResponse1_ECPM : 7|1@0+ (1,0) [0|1] ""  TOOL
 SG_ failureResponse2_ECPM : 6|1@0+ (1,0) [0|1] ""  TOOL
 SG_ failureResponse3_ECPM : 5|1@0+ (1,0) [0|1] ""  TOOL
 SG_ failureResponse4_ECPM : 4|1@0+ (1,0) [0|1] ""  TOOL
 SG_ failureResponse5_ECPM : 3|1@0+ (1,0) [0|1] ""  TOOL
 SG_ failureResponse6_ECPM : 2|1@0+ (1,0) [0|1] ""  TOOL
 SG_ failureResponse7_ECPM : 1|1@0+ (1,0) [0|1] ""  TOOL

BO_ 807 ECPM_Debug: 8 ECPM

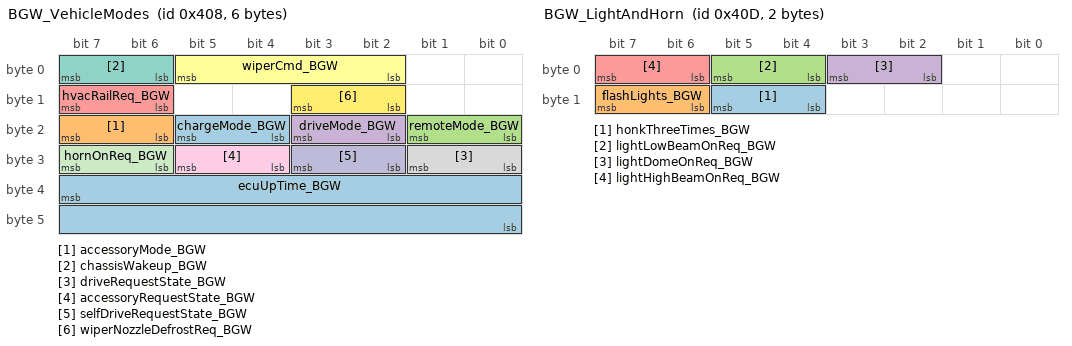
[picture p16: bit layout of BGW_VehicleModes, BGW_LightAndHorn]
BO_ 1032 BGW_VehicleModes: 6 BGW
 SG_ chargeMode_BGW : 21|2@0+ (1,0) [0|2] ""  DCFL,DCFR,DCRL,DCRR,FBCM
 SG_ accessoryMode_BGW : 23|2@0+ (1,0) [0|2] ""  DCFL,DCFR,DCRL,DCRR,FBCM
 SG_ remoteMode_BGW : 17|2@0+ (1,0) [0|2] ""  DCFL,DCFR,DCRL,DCRR,FBCM
 SG_ driveMode_BGW : 19|2@0+ (1,0) [0|2] ""  IHUB,DCFL,DCFR,DCRL,DCRR,FBCM
 SG_ hvacRailReq_BGW : 15|2@0+ (1,0) [0|2] ""  FBCM
 SG_ wiperCmd_BGW : 5|4@0+ (1,0) [0|14] ""  FBCM
 SG_ chassisWakeup_BGW : 7|2@0+ (1,0) [0|2] ""  FBCM
 SG_ driveRequestState_BGW : 25|2@0+ (1,0) [0|2] ""  DCFL,DCFR,DCRL,DCRR,FBCM
 SG_ accessoryRequestState_BGW : 29|2@0+ (1,0) [0|2] ""  FBCM
 SG_ selfDriveRequestState_BGW : 27|2@0+ (1,0) [0|2] ""  FBCM
 SG_ hornOnReq_BGW : 31|2@0+ (1,0) [0|2] ""  FBCM
 SG_ wiperNozzleDefrostReq_BGW : 11|2@0+ (1,0) [0|2] ""  ECPM,FBCM
 SG_ ecuUpTime_BGW : 39|16@0+ (1,0) [0|65534] "Seconds"  TOOL

BO_ 1033 BGW_InfoFromIHUB: 7 BGW
 SG_ mirrorDefrostCameraOnReq_IHUB : 47|2@0+ (1,0) [0|2] ""  DCFL,DCFR
 SG_ mirrorDimReq_IHUB : 51|2@0+ (1,0) [0|2] ""  DCFL,DCFR
 SG_ mirrorFoldInOutReq_IHUB : 45|2@0+ (1,0) [0|2] ""  DCFL,DCFR
 SG_ defrostMirrorGlassReq_IHUB : 19|2@0+ (1,0) [0|2] ""  DCFL,DCFR
 SG_ exteriorLightReq_IHUB : 11|3@0+ (1,0) [0|7] ""  FBCM
 SG_ frunkLockReq_IHUB : 55|2@0+ (1,0) [0|2] ""  FBCM
 SG_ liftgateLockReq_IHUB : 53|2@0+ (1,0) [0|2] ""  FBCM
 SG_ doorRRLockReq_IHUB : 25|2@0+ (1,0) [0|2] ""  FBCM
 SG_ doorRLLockReq_IHUB : 27|2@0+ (1,0) [0|2] ""  FBCM
 SG_ doorFRLockReq_IHUB : 29|2@0+ (1,0) [0|2] ""  FBCM
 SG_ doorFLLockReq_IHUB : 31|2@0+ (1,0) [0|2] ""  FBCM
 SG_ doorRearRightOperation_IHUB : 15|4@0+ (1,0) [0|14] ""  DCFL,DCFR,DCRR,DCRL,FBCM
 SG_ doorRearLeftOperation_IHUB : 3|4@0+ (1,0) [0|14] ""  DCFL,DCFR,DCRR,DCRL,FBCM
 SG_ doorFrontRightOperation_IHUB : 7|4@0+ (1,0) [0|14] ""  DCFL,DCFR,DCRR,DCRL,FBCM
 SG_ doorFrontLeftOperation_IHUB : 43|4@0+ (1,0) [0|14] ""  DCFL,DCFR,DCRR,DCRL,FBCM
 SG_ lightLowBeamOnReq_IHUB : 17|2@0+ (1,0) [0|2] ""  FBCM
 SG_ frontHoodOpen_IHUB : 39|3@0+ (1,0) [0|2] ""  FBCM
 SG_ fogSwitchRear_IHUB : 21|2@0+ (1,0) [0|2] ""  FBCM
 SG_ fogSwitchFront_IHUB : 23|2@0+ (1,0) [0|2] ""  FBCM
 SG_ steeringHeatEnabled_IHUB : 49|2@0+ (1,0) [0|2] ""  FBCM

BO_ 1035 BGW_Status: 8 BGW
 SG_ autoHighBeamStatus_BGW : 46|2@0+ (1,0) [0|3] ""  HUD,IHUB
 SG_ liftgateAngle_BGW : 7|8@0+ (0.5,0) [0|73.5] ""  HUD,IHUB,DBPC,TOOL
 SG_ liftgateStatus_BGW : 15|4@0+ (1,0) [0|0] ""  HUD,IHUB,DBPC,TOOL
 SG_ doorErrorRR_BGW : 57|2@0+ (1,0) [0|1] ""  DCFL,DCFR,DCRL,DCRR,FBCM
 SG_ doorErrorRL_BGW : 59|2@0+ (1,0) [0|1] ""  DCFL,DCFR,DCRL,DCRR,FBCM
 SG_ doorErrorFR_BGW : 9|2@0+ (1,0) [0|1] ""  DCFL,DCFR,DCRL,DCRR,FBCM
 SG_ doorErrorFL_BGW : 11|2@0+ (1,0) [0|1] ""  DCFL,DCFR,DCRL,DCRR,FBCM
 SG_ latchTarget_BGW : 51|2@0+ (1,0) [0|2] ""  DCFL,DCFR,DCRL,DCRR,FBCM
 SG_ doorState_BGW : 53|2@0+ (1,0) [0|3] ""  DCFL,DCFR,DCRL,DCRR,FBCM
 SG_ childLockStatus_BGW : 33|2@0+ (1,0) [0|2] ""  DCFL,DCFR,DCRL,DCRR,IHUB
 SG_ wakeUpCause_BGW : 44|5@0+ (1,0) [0|8] ""  TOOL
 SG_ lightFogRearStatus_BGW : 20|2@0+ (1,0) [0|2] ""  HUD,IHUB
 SG_ state_BGW : 23|3@0+ (1,0) [0|6] ""  TOOL
 SG_ doorRLLockStatus_BGW : 27|2@0+ (1,0) [0|2] ""  DBPC,FBCM,DCFL,DCFR,DCRL,DCRR
 SG_ liftgateLockStatus_BGW : 17|2@0+ (1,0) [0|2] ""  DBPC,FBCM,DCFL,DCFR,DCRL,DCRR
 SG_ doorRRLockStatus_BGW : 25|2@0+ (1,0) [0|2] ""  DBPC,FBCM,DCFL,DCFR,DCRL,DCRR
 SG_ doorFRLockStatus_BGW : 29|2@0+ (1,0) [0|2] ""  DBPC,FBCM,DCFL,DCFR,DCRL,DCRR
 SG_ doorFLLockStatus_BGW : 31|2@0+ (1,0) [0|2] ""  DBPC,FBCM,DCFL,DCFR,DCRL,DCRR
 SG_ doorSwitchCpillarLeft_BGW : 39|3@0+ (1,0) [0|6] ""  DCFL,DCRL
 SG_ doorSwitchCpillarRight_BGW : 36|3@0+ (1,0) [0|6] ""  DCFL,DCFR,DCRR
 SG_ driveLikelyCountdown_BGW : 49|4@0+ (1,0) [0|14] ""  TOOL
 SG_ bodyBusStateNM_BGW : 54|1@0+ (1,0) [0|2] ""  TOOL
 SG_ tboxBusStateNM_BGW : 47|1@0+ (1,0) [0|2] ""  TOOL
 SG_ ethernetStateNM_BGW : 55|1@0+ (1,0) [0|2] ""  TOOL
 SG_ appSleepState_BGW : 18|1@0+ (1,0) [0|2] ""  TOOL

BO_ 1037 BGW_LightAndHorn: 2 BGW
 SG_ honkThreeTimes_BGW : 13|2@0+ (1,0) [0|0] ""  FBCM
 SG_ flashLights_BGW : 15|2@0+ (1,0) [0|0] ""  FBCM
 SG_ lightLowBeamOnReq_BGW : 5|2@0+ (1,0) [0|2] ""  FBCM,HLL,HLR
 SG_ lightDomeOnReq_BGW : 3|2@0+ (1,0) [0|2] ""  FBCM
 SG_ lightHighBeamOnReq_BGW : 7|2@0+ (1,0) [0|2] ""  FBCM,HLL,HLR

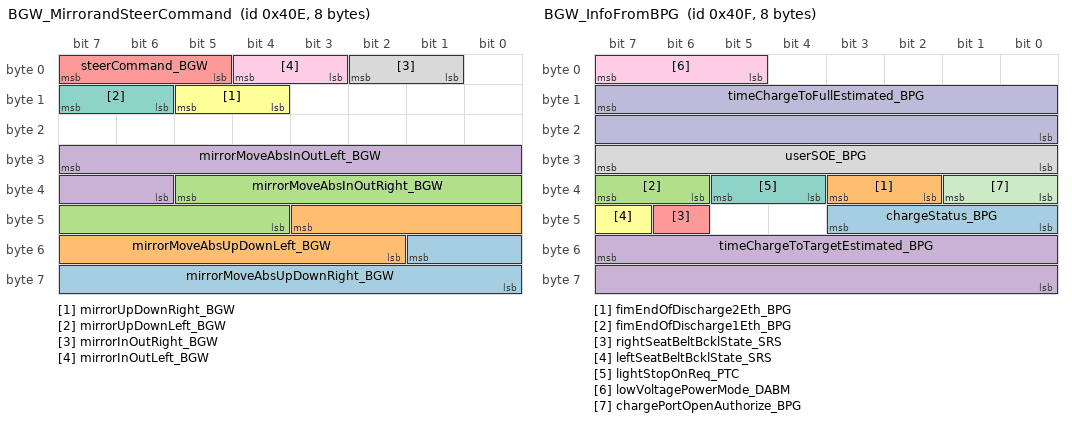
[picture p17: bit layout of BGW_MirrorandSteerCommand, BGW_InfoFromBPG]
BO_ 1038 BGW_MirrorandSteerCommand: 8 BGW
 SG_ mirrorMoveAbsUpDownRight_BGW : 49|10@0+ (0.1,-38) [-38|38] "degrees"  DCFR,DCFL
 SG_ mirrorMoveAbsUpDownLeft_BGW : 43|10@0+ (0.1,-38) [-38|38] "degrees"  DCFR,DCFL
 SG_ mirrorMoveAbsInOutRight_BGW : 37|10@0+ (0.1,-38) [-38|38] "degrees"  DCFR,DCFL
 SG_ mirrorMoveAbsInOutLeft_BGW : 31|10@0+ (0.1,-38) [-38|38] "degrees"  DCFR,DCFL
 SG_ steerCommand_BGW : 7|3@0+ (1,0) [0|0] ""  FBCM
 SG_ mirrorUpDownRight_BGW : 13|2@0+ (1,0) [0|0] ""  DCFL,DCFR
 SG_ mirrorUpDownLeft_BGW : 15|2@0+ (1,0) [0|0] ""  DCFL
 SG_ mirrorInOutRight_BGW : 2|2@0+ (1,0) [0|0] ""  DCFL,DCFR
 SG_ mirrorInOutLeft_BGW : 4|2@0+ (1,0) [0|0] ""  DCFL

BO_ 1039 BGW_InfoFromBPG: 8 BGW
 SG_ chargeStatus_BPG : 43|4@0+ (1,0) [0|0] ""  DBPC
 SG_ fimEndOfDischarge2Eth_BPG : 35|2@0+ (1,0) [0|0] ""  DBPC
 SG_ fimEndOfDischarge1Eth_BPG : 39|2@0+ (1,0) [0|0] ""  DBPC
 SG_ timeChargeToTargetEstimated_BPG : 55|16@0+ (1,0) [0|65534] "minutes"  DBPC
 SG_ rightSeatBeltBcklState_SRS : 46|1@0+ (1,0) [0|0] ""  HUD
 SG_ leftSeatBeltBcklState_SRS : 47|1@0+ (1,0) [0|0] ""  HUD
 SG_ lightStopOnReq_PTC : 37|2@0+ (1,0) [0|2] ""  FBCM,ECPM,DCRL,DCRR,DCFR,DCFL,RCLR,RCLL,LGL
 SG_ userSOE_BPG : 31|8@0+ (0.5,0) [0|100] "%"  DBPC
 SG_ lowVoltagePowerMode_DABM : 7|3@0+ (1,0) [0|3] ""  TOOL,SCAM,RRSM,RRDC,RLSM,RLDC,RCLR,RCLL,RCCR,RCCL,PSM,PBPC,LGL,HUD,HLR,HLL,FRDC,FLDC,FFL,ECPM,DSM,DCRR,DCRL,DCFR,DCFL,DBPC,ACCL,FBCM
 SG_ timeChargeToFullEstimated_BPG : 15|16@0+ (1,0) [0|65534] "minutes"  DBPC
 SG_ chargePortOpenAuthorize_BPG : 33|2@0+ (1,0) [0|2] ""  FBCM

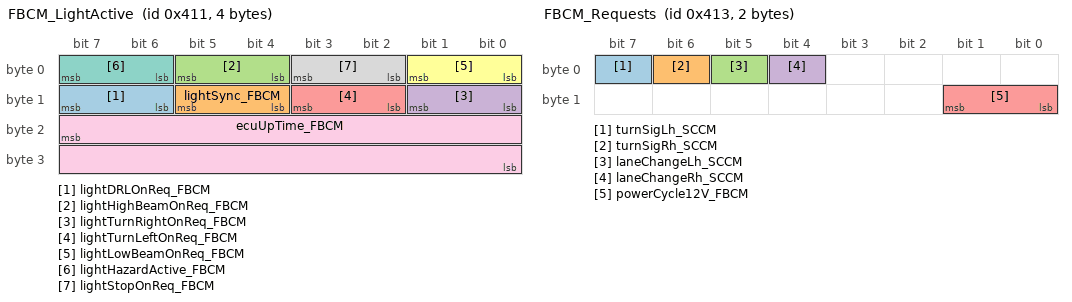
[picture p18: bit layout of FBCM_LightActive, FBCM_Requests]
BO_ 1041 FBCM_LightActive: 4 FBCM
 SG_ lightDRLOnReq_FBCM : 15|2@0+ (1,0) [0|2] ""  BGW,IHUB,HUD,HLR,HLL
 SG_ lightSync_FBCM : 13|2@0+ (1,0) [0|2] ""  DCFL,DCFR,RCLR,RCLL,HLL,HLR,BGW,IHUB,HUD
 SG_ lightHighBeamOnReq_FBCM : 5|2@0+ (1,0) [0|2] ""  IHUB,RCLR,LGL,RCLL,ACCL,HUD,BGW,HLL,HLR
 SG_ lightTurnRightOnReq_FBCM : 9|2@0+ (1,0) [0|2] ""  IHUB,DCFR,RCLR,RCLL,HUD,BGW,HLL,HLR
 SG_ lightTurnLeftOnReq_FBCM : 11|2@0+ (1,0) [0|2] ""  IHUB,DCFL,RCLL,RCLR,HUD,BGW,HLL,HLR
 SG_ lightLowBeamOnReq_FBCM : 1|2@0+ (1,0) [0|2] ""  IHUB,HUD,BGW,HLL,HLR
 SG_ lightHazardActive_FBCM : 7|2@0+ (1,0) [0|2] ""  DCFR,DCFL,HUD,BGW,HLL,HLR,IHUB
 SG_ lightStopOnReq_FBCM : 3|2@0+ (1,0) [0|2] ""  RCLL,RCLR
 SG_ ecuUpTime_FBCM : 23|16@0+ (1,0) [0|65534] "Seconds"  BGW,TOOL

BO_ 1043 FBCM_Requests: 2 FBCM
 SG_ turnSigLh_SCCM : 7|1@0+ (1,0) [0|1] ""  BGW
 SG_ turnSigRh_SCCM : 6|1@0+ (1,0) [0|1] ""  BGW
 SG_ laneChangeLh_SCCM : 5|1@0+ (1,0) [0|1] ""  BGW
 SG_ laneChangeRh_SCCM : 4|1@0+ (1,0) [0|1] ""  BGW
 SG_ powerCycle12V_FBCM : 9|2@0+ (1,0) [0|2] ""  BGW

BO_ 1044 FBCM_DemEvent1: 8 FBCM
 SG_ demALCPTLINSignalError_FBCM : 7|2@0+ (1,0) [0|2] ""  TOOL
 SG_ demALCPTLINSignalLoss_FBCM : 5|2@0+ (1,0) [0|2] ""  TOOL
 SG_ demAccessoryRelayFailure_FBCM : 3|2@0+ (1,0) [0|2] ""  TOOL
 SG_ demAccessoryRelayError_FBCM : 1|2@0+ (1,0) [0|2] ""  TOOL
 SG_ demAmbientLightSleepError_FBCM : 15|2@0+ (1,0) [0|2] ""  TOOL
 SG_ demAmbientLightPowerLoss_FBCM : 13|2@0+ (1,0) [0|2] ""  TOOL
 SG_ demBodyCANNetworkLoss_FBCM : 11|2@0+ (1,0) [0|2] ""  TOOL
 SG_ demBrakeFluidIndicatorError_FBCM : 9|2@0+ (1,0) [0|2] ""  TOOL
 SG_ demBrakeLightInputFault_FBCM : 23|2@0+ (1,0) [0|2] ""  TOOL
 SG_ demCIDHallSensorSignalLoss_FBCM : 21|2@0+ (1,0) [0|2] ""  TOOL
 SG_ demCIDHallSensorFast_FBCM : 19|2@0+ (1,0) [0|2] ""  TOOL
 SG_ demCIDHallSensorSlowSignal_FBCM : 17|2@0+ (1,0) [0|2] ""  TOOL
 SG_ demCIDMotorOvercurrent_FBCM : 31|2@0+ (1,0) [0|2] ""  TOOL
 SG_ demCIDMotorUndercurrent_FBCM : 29|2@0+ (1,0) [0|2] ""  TOOL
 SG_ demCIDMotorError_FBCM : 27|2@0+ (1,0) [0|2] ""  TOOL
 SG_ demCIDMotorSignalLoss_FBCM : 25|2@0+ (1,0) [0|2] ""  TOOL
 SG_ demCIDDownMovementFailure_FBCM : 39|2@0+ (1,0) [0|2] ""  TOOL
 SG_ demCIDUpMovementFailure_FBCM : 37|2@0+ (1,0) [0|2] ""  TOOL
 SG_ demCIDDownMovementError_FBCM : 35|2@0+ (1,0) [0|2] ""  TOOL
 SG_ demCIDUpMovementError_FBCM : 33|2@0+ (1,0) [0|2] ""  TOOL
 SG_ demCPDCloseError_FBCM : 47|2@0+ (1,0) [0|2] ""  TOOL
 SG_ demCDPCloseFailure_FBCM : 45|2@0+ (1,0) [0|2] ""  TOOL
 SG_ demCPDOpenFailure_FBCM : 43|2@0+ (1,0) [0|2] ""  TOOL
 SG_ demCPDOpenError_FBCM : 41|2@0+ (1,0) [0|2] ""  TOOL
 SG_ demDomeRLINSignalError_FBCM : 55|2@0+ (1,0) [0|2] ""  TOOL
 SG_ demDomeRLINSignalLoss_FBCM : 53|2@0+ (1,0) [0|2] ""  TOOL
 SG_ demLIN1NetworkDown_FBCM : 51|2@0+ (1,0) [0|2] ""  TOOL
 SG_ demFLIPLLINSignalError_FBCM : 49|2@0+ (1,0) [0|2] ""  TOOL
 SG_ demFLIPLLINSignalLoss_FBCM : 63|2@0+ (1,0) [0|2] ""  TOOL
 SG_ demFLIPRLLINSignalError_FBCM : 61|2@0+ (1,0) [0|2] ""  TOOL
 SG_ demFLIPRLINSignalLoss_FBCM : 59|2@0+ (1,0) [0|2] ""  TOOL
 SG_ demChassisWUPRelayFailure_FBCM : 57|2@0+ (1,0) [0|2] ""  TOOL

BO_ 1042 FBCM_DemEvent2: 8 FBCM
 SG_ demDomeFLINError_FBCM : 7|2@0+ (1,0) [0|2] ""  TOOL
 SG_ demFFogLampFault_FBCM : 5|2@0+ (1,0) [0|2] ""  TOOL
 SG_ demFSideMarkersFailure_FBCM : 3|2@0+ (1,0) [0|2] ""  TOOL
 SG_ demFWiperDeicerRelayFailure_FBCM : 1|2@0+ (1,0) [0|2] ""  TOOL
 SG_ demFWiperDeicerRelayError_FBCM : 15|2@0+ (1,0) [0|2] ""  TOOL
 SG_ demHLLDRLError_FBCM : 13|2@0+ (1,0) [0|2] ""  TOOL
 SG_ demHLLDRLMIA_FBCM : 11|2@0+ (1,0) [0|2] ""  TOOL
 SG_ demHLLHazardError_FBCM : 9|2@0+ (1,0) [0|2] ""  TOOL
 SG_ demHLLHazardMIA_FBCM : 23|2@0+ (1,0) [0|2] ""  TOOL
 SG_ demHLLHighBeamError_FBCM : 21|2@0+ (1,0) [0|2] ""  TOOL
 SG_ demHLLHighBeamMIA_FBCM : 19|2@0+ (1,0) [0|2] ""  TOOL
 SG_ demHLLParkError_FBCM : 17|2@0+ (1,0) [0|2] ""  TOOL
 SG_ demHLLParkMIA_FBCM : 31|2@0+ (1,0) [0|2] ""  TOOL
 SG_ demHLLTurnSignalError_FBCM : 29|2@0+ (1,0) [0|2] ""  TOOL
 SG_ demHLLTurnSignalMIA_FBCM : 27|2@0+ (1,0) [0|2] ""  TOOL
 SG_ demHLLLowBeamError_FBCM : 25|2@0+ (1,0) [0|2] ""  TOOL
 SG_ demHLLowBeamMIA_FBCM : 39|2@0+ (1,0) [0|2] ""  TOOL
 SG_ demHLRDRLError_FBCM : 37|2@0+ (1,0) [0|2] ""  TOOL
 SG_ demHLRDRLMIA_FBCM : 35|2@0+ (1,0) [0|2] ""  TOOL
 SG_ demHLRHazardError_FBCM : 33|2@0+ (1,0) [0|2] ""  TOOL
 SG_ demHLRHazardMIA_FBCM : 47|2@0+ (1,0) [0|2] ""  TOOL
 SG_ demHLRHighBeamError_FBCM : 45|2@0+ (1,0) [0|2] ""  TOOL
 SG_ demHLRHighBeamMIA_FBCM : 43|2@0+ (1,0) [0|2] ""  TOOL
 SG_ demHLRParkError_FBCM : 41|2@0+ (1,0) [0|2] ""  TOOL
 SG_ demHLRParkMIA_FBCM : 55|2@0+ (1,0) [0|2] ""  TOOL
 SG_ demHLRTurnSignalError_FBCM : 53|2@0+ (1,0) [0|2] ""  TOOL
 SG_ demHLRTurnSignalMIA_FBCM : 51|2@0+ (1,0) [0|2] ""  TOOL
 SG_ demHLRLowBeamError_FBCM : 49|2@0+ (1,0) [0|2] ""  TOOL
 SG_ demHLRLowBeamMIA_FBCM : 63|2@0+ (1,0) [0|2] ""  TOOL
 SG_ demHazardSwitchLightFault_FBCM : 61|2@0+ (1,0) [0|2] ""  TOOL
 SG_ demHazardSwitchInputFault_FBCM : 59|2@0+ (1,0) [0|2] ""  TOOL
 SG_ demHLWasherPumpError_FBCM : 57|2@0+ (1,0) [0|2] ""  TOOL

BO_ 535 FBCM_DemEvent3: 8 FBCM
 SG_ demHLWasherPumpFailure_FBCM : 7|2@0+ (1,0) [0|2] ""  TOOL
 SG_ demHomelinkPowerLoss_FBCM : 5|2@0+ (1,0) [0|2] ""  TOOL
 SG_ demHomelinkPowerError_FBCM : 3|2@0+ (1,0) [0|2] ""  TOOL
 SG_ demHoodLatchError_FBCM : 1|2@0+ (1,0) [0|2] ""  TOOL
 SG_ demHoodLatchReleaseError_FBCM : 15|2@0+ (1,0) [0|2] ""  TOOL
 SG_ demHornInputFailure_FBCM : 13|2@0+ (1,0) [0|2] ""  TOOL
 SG_ demHornLowError_FBCM : 11|2@0+ (1,0) [0|2] ""  TOOL
 SG_ demHornFailure_FBCM : 9|2@0+ (1,0) [0|2] ""  TOOL
 SG_ demLWMMLINSignalLoss_FBCM : 23|2@0+ (1,0) [0|2] ""  TOOL
 SG_ demRLSLINError_FBCM : 21|2@0+ (1,0) [0|2] ""  TOOL
 SG_ demSCCMLINSignalLoss_FBCM : 19|2@0+ (1,0) [0|2] ""  TOOL
 SG_ demBrakeFluidIndFailure_FBCM : 17|2@0+ (1,0) [0|2] ""  TOOL
 SG_ demMLIPLLINSignalError_FBCM : 31|2@0+ (1,0) [0|2] ""  TOOL
 SG_ demMLIPLLINSignalLoss_FBCM : 29|2@0+ (1,0) [0|2] ""  TOOL
 SG_ demMLIPRLINSignalError_FBCM : 27|2@0+ (1,0) [0|2] ""  TOOL
 SG_ demMLIPRLINSignalLoss_FBCM : 25|2@0+ (1,0) [0|2] ""  TOOL
 SG_ demDomeFPowerLoss_FBCM : 39|2@0+ (1,0) [0|2] ""  TOOL
 SG_ demRLSPowerLoss_FBCM : 37|2@0+ (1,0) [0|2] ""  TOOL
 SG_ demRCLLParkError_FBCM : 35|2@0+ (1,0) [0|2] ""  TOOL
 SG_ demRCLLParkMIA_FBCM : 33|2@0+ (1,0) [0|2] ""  TOOL
 SG_ demRCLLHazardError_FBCM : 47|2@0+ (1,0) [0|2] ""  TOOL
 SG_ demRCLLHazardMIA_FBCM : 45|2@0+ (1,0) [0|2] ""  TOOL
 SG_ demRCLLStopError_FBCM : 43|2@0+ (1,0) [0|2] ""  TOOL
 SG_ demRCLLStopMIA_FBCM : 41|2@0+ (1,0) [0|2] ""  TOOL
 SG_ demRCLLTailError_FBCM : 55|2@0+ (1,0) [0|2] ""  TOOL
 SG_ demRCLLTailMIA_FBCM : 53|2@0+ (1,0) [0|2] ""  TOOL
 SG_ demRCLLTurnSignalError_FBCM : 51|2@0+ (1,0) [0|2] ""  TOOL
 SG_ demRCLLTurnSignalMIA_FBCM : 49|2@0+ (1,0) [0|2] ""  TOOL
 SG_ demRCLRParkError_FBCM : 63|2@0+ (1,0) [0|2] ""  TOOL
 SG_ demRCLRParkMIA_FBCM : 61|2@0+ (1,0) [0|2] ""  TOOL
 SG_ demRCLRHazardError_FBCM : 59|2@0+ (1,0) [0|2] ""  TOOL
 SG_ demRCLRHazardMIA_FBCM : 57|2@0+ (1,0) [0|2] ""  TOOL

BO_ 533 FBCM_DemEvent4: 8 FBCM
 SG_ demRLSLINLoss_FBCM : 57|2@0+ (1,0) [0|2] ""  TOOL
 SG_ demHLWasherPumpOVC_FBCM : 59|2@0+ (1,0) [0|2] ""  TOOL
 SG_ demRCLRStopError_FBCM : 7|2@0+ (1,0) [0|2] ""  TOOL
 SG_ demRCLRStopMIA_FBCM : 5|2@0+ (1,0) [0|2] ""  TOOL
 SG_ demRCLRTailError_FBCM : 3|2@0+ (1,0) [0|2] ""  TOOL
 SG_ demRCLRTailMIA_FBCM : 1|2@0+ (1,0) [0|2] ""  TOOL
 SG_ demRCLRTurnSignalError_FBCM : 15|2@0+ (1,0) [0|2] ""  TOOL
 SG_ demRCLRTurnSignalMIA_FBCM : 13|2@0+ (1,0) [0|2] ""  TOOL
 SG_ demRSCMLLINSignalError_FBCM : 11|2@0+ (1,0) [0|2] ""  TOOL
 SG_ demRSCMLINSignalLoss_FBCM : 9|2@0+ (1,0) [0|2] ""  TOOL
 SG_ demRSDDownMovementFailure_FBCM : 23|2@0+ (1,0) [0|2] ""  TOOL
 SG_ demRSDUpLatchFailure_FBCM : 21|2@0+ (1,0) [0|2] ""  TOOL
 SG_ demRSDLatchReleaseFailure_FBCM : 19|2@0+ (1,0) [0|2] ""  TOOL
 SG_ demRSDHallSensorSignalLoss_FBCM : 17|2@0+ (1,0) [0|2] ""  TOOL
 SG_ demRSDHallSensorSigTooFast_FBCM : 31|2@0+ (1,0) [0|2] ""  TOOL
 SG_ demRSDMotorOvercurrent_FBCM : 29|2@0+ (1,0) [0|2] ""  TOOL
 SG_ demRSDMotorUndercurrent_FBCM : 27|2@0+ (1,0) [0|2] ""  TOOL
 SG_ demRSDMotorCurrentError_FBCM : 25|2@0+ (1,0) [0|2] ""  TOOL
 SG_ demRSDMotorSignalLoss_FBCM : 39|2@0+ (1,0) [0|2] ""  TOOL
 SG_ demRSDDownMovementError_FBCM : 37|2@0+ (1,0) [0|2] ""  TOOL
 SG_ demRSDUpMovementError_FBCM : 35|2@0+ (1,0) [0|2] ""  TOOL
 SG_ demRLSPowerError_FBCM : 33|2@0+ (1,0) [0|2] ""  TOOL
 SG_ demRSDFullBrakeFailure_FBCM : 47|2@0+ (1,0) [0|2] ""  TOOL
 SG_ demRSDFullBrakeError_FBCM : 45|2@0+ (1,0) [0|2] ""  TOOL
 SG_ demRSDHalfBrakeError_FBCM : 43|2@0+ (1,0) [0|2] ""  TOOL
 SG_ demRSDUpMovementFailure_FBCM : 41|2@0+ (1,0) [0|2] ""  TOOL
 SG_ demFSideMarkerError_FBCM : 55|2@0+ (1,0) [0|2] ""  TOOL
 SG_ demWasherFluidIndSigError_FBCM : 53|2@0+ (1,0) [0|2] ""  TOOL
 SG_ demWasherPumpError_FBCM : 51|2@0+ (1,0) [0|2] ""  TOOL
 SG_ demWasherPumpFailure_FBCM : 49|2@0+ (1,0) [0|2] ""  TOOL
 SG_ demWasherFluidIndSignalLoss_FBCM : 63|2@0+ (1,0) [0|2] ""  TOOL
 SG_ demChassisWUPRelayError_FBCM : 61|2@0+ (1,0) [0|2] ""  TOOL

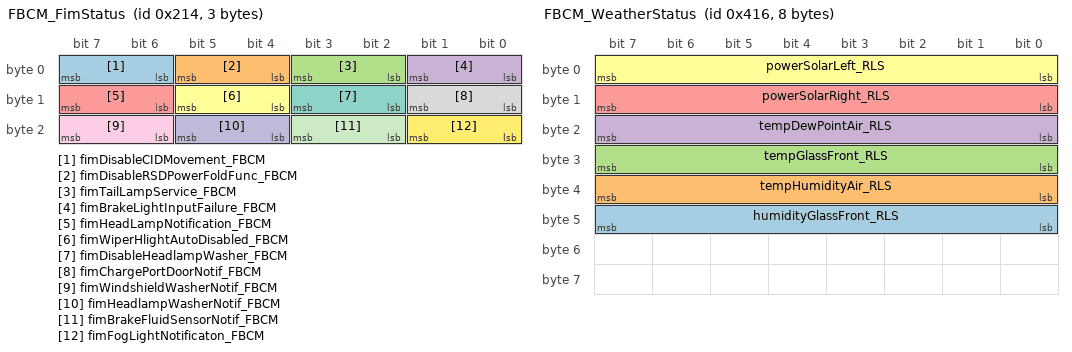
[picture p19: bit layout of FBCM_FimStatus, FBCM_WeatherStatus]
BO_ 532 FBCM_FimStatus: 3 FBCM
 SG_ fimDisableCIDMovement_FBCM : 7|2@0+ (1,0) [0|2] ""  TOOL
 SG_ fimDisableRSDPowerFoldFunc_FBCM : 5|2@0+ (1,0) [0|2] ""  TOOL
 SG_ fimTailLampService_FBCM : 3|2@0+ (1,0) [0|2] ""  TOOL
 SG_ fimBrakeLightInputFailure_FBCM : 1|2@0+ (1,0) [0|2] ""  TOOL
 SG_ fimHeadLampNotification_FBCM : 15|2@0+ (1,0) [0|2] ""  TOOL
 SG_ fimWiperHlightAutoDisabled_FBCM : 13|2@0+ (1,0) [0|2] ""  BGW,TOOL
 SG_ fimDisableHeadlampWasher_FBCM : 11|2@0+ (1,0) [0|2] ""  TOOL
 SG_ fimChargePortDoorNotif_FBCM : 9|2@0+ (1,0) [0|2] ""  TOOL
 SG_ fimWindshieldWasherNotif_FBCM : 23|2@0+ (1,0) [0|2] ""  BGW,TOOL
 SG_ fimHeadlampWasherNotif_FBCM : 21|2@0+ (1,0) [0|2] ""  BGW,TOOL
 SG_ fimBrakeFluidSensorNotif_FBCM : 19|2@0+ (1,0) [0|2] ""  BGW,TOOL
 SG_ fimFogLightNotificaton_FBCM : 17|2@0+ (1,0) [0|2] ""  TOOL

BO_ 1045 FBCM_Status: 8 FBCM
 SG_ swchStateHighBeam_FBCM : 43|2@0+ (1,0) [0|2] ""  BGW
 SG_ swchStateWshrMst_SCCM : 47|2@0+ (1,0) [0|2] ""  BGW
 SG_ alarmModeHornStatus_FBCM : 61|2@0+ (1,0) [0|0] ""  BGW
 SG_ alarmModeHazardStatus_FBCM : 63|2@0+ (1,0) [0|0] ""  BGW
 SG_ delcerFrontStatus_FBCM : 39|2@0+ (1,0) [0|2] ""  BGW
 SG_ chargePortDoorStatus_FBCM : 7|3@0+ (1,0) [0|6] ""  DBPC,IHUB,BGW
 SG_ lightHazardStatus_FBCM : 9|2@0+ (1,0) [0|2] ""  HUD,IHUB,BGW
 SG_ lightFogFrontStatus_FBCM : 11|2@0+ (1,0) [0|2] ""  IHUB,HUD,BGW
 SG_ lightDomeStatus_FBCM : 53|2@0+ (1,0) [0|2] ""  BGW
 SG_ brakeFluidLevel_FBCM : 55|2@0+ (1,0) [0|2] ""  HUD,BGW,IHUB
 SG_ lightFogFrontRightStatus_FBCM : 17|2@0+ (1,0) [0|2] ""  ECPM,HUD,ACCL,HLL,HLR,LGL,RCLL,RCLR,BGW
 SG_ lightFogFrontLeftStatus_FBCM : 25|2@0+ (1,0) [0|2] ""  ECPM,HUD,ACCL,HLL,HLR,LGL,RCLL,RCLR,BGW
 SG_ srsStatus_FBCM : 23|2@0+ (1,0) [0|2] ""  BGW
 SG_ wiperStatus_LWMM : 15|4@0+ (1,0) [0|14] ""  HUD,BGW
 SG_ washerFluidLevel_FBCM : 27|2@0+ (1,0) [0|2] ""  HUD,BGW,IHUB
 SG_ hornStatus_FBCM : 29|2@0+ (1,0) [0|2] ""  BGW
 SG_ stateVehicle_FBCM : 4|3@0+ (1,0) [0|6] ""  HUD,ECPM,RCLR,RCLL,LGL,HLR,HLL,ACCL,BGW
 SG_ scStatus_FBCM : 45|2@0+ (1,0) [0|2] ""  BGW
 SG_ frontTrunkStatus_FBCM : 31|2@0+ (1,0) [0|2] ""  BGW
 SG_ lockRejected_FBCM : 19|2@0+ (1,0) [0|2] ""  BGW
 SG_ dtcPresent_FBCM : 1|2@0+ (1,0) [0|2] ""  BGW
 SG_ lightFSMStatus_FBCM : 41|2@0+ (1,0) [0|2] ""  BGW,IHUB
 SG_ wakeUpCause_FBCM : 34|3@0+ (1,0) [0|7] ""  TOOL,BGW
 SG_ steeringHeatStatus_FBCM : 21|2@0+ (1,0) [0|2] ""  BGW,IHUB

BO_ 1046 FBCM_WeatherStatus: 8 FBCM
 SG_ humidityGlassFront_RLS : 47|8@0+ (0.5,0) [0|100] "% RH"  BGW
 SG_ tempHumidityAir_RLS : 39|8@0+ (0.5,-40) [-40|87] "deg C"  BGW
 SG_ tempGlassFront_RLS : 31|8@0+ (0.5,-40) [-40|87] "deg C"  BGW
 SG_ tempDewPointAir_RLS : 23|8@0+ (0.5,-40) [-40|87] "deg C"  BGW
 SG_ powerSolarRight_RLS : 15|8@0+ (5,0) [0|1200] " W/m2"  BGW
 SG_ powerSolarLeft_RLS : 7|8@0+ (5,0) [0|1200] "W/m2"  BGW

CM_ BO_ 896 "Tool Option Selection";
CM_ SG_ 896 changeBaudRate_TOOL "Signal to select the CAN baud rate";
CM_ SG_ 367 steeringAngle_SAS "Steering wheel angle";
CM_ SG_ 367 rollRate_SRS "Roll Rate. Positive value when vehicle is in a left hand turn. Units of Grad/sec, 1 Grad = 1/400th of a full circle. See IMU bus spec. for details";
CM_ BO_ 529 "made 10 second cyclic for bus loading issue. will fix later.";
CM_ BO_ 530 "Made cyclic time 10s for bus loading issue. Will fix later.";
CM_ BO_ 14 "Values are ascii letters from the number zero to capital Z. Lowercase letters are not supported for VIN.";
CM_ SG_ 14 vehicleIdNumberLo_BGW "This signal represents the ASCII characters which make up the Vehicle Identification Number.";
CM_ SG_ 14 vehicleIdNumberHi_BGW "This signal represents the ASCII characters which make up the Vehicle Identification Number.";
CM_ SG_ 14 vehicleIdNumberMid_BGW "This signal represents the ASCII characters which make up the Vehicle Identification Number.";
CM_ BO_ 265 "Debug message used to capture task CPU usage. Temporary.";
CM_ SG_ 265 taskEthTx_BGW "Temporary signal for debugging.";
CM_ SG_ 265 taskEthRx_BGW "Temporary signal for debugging.";
CM_ SG_ 265 task100Hz_BGW "Temporary signal for debugging.";
CM_ SG_ 265 task1000Hz_BGW "Temporary signal for debugging.";
CM_ SG_ 269 mirrorDimmingEnableDisable_IHUB "Enables/Disables mirror dimming function. Level of dimming is determined by SDCM.";
CM_ SG_ 267 vehicleSpeedQ_ESP "VehicleSpeed Qualifier";
CM_ SG_ 267 vehicleSpeed_ESP "ESP calculated vehicle speed. Average of front wheels on rear wheel drive vehicles. Average of all four wheels on dual motor vehicles.";
CM_ SG_ 271 range_IHUB "Current range calculated by IHUB.";
CM_ SG_ 271 rsdCommandPosition_IHUB "IHUB commans to FBCM for specifying RSD target position";
CM_ SG_ 271 nightModeSelect_IHUB "UNSURE of function";
CM_ SG_ 271 rearDisplayUpDownReq_IHUB "IHUB commands FBCM to raise/lower the Rear Seat Display";
CM_ SG_ 271 panelSelectForBrightness_IHUB "Used in combination with panelBrightness_IHUB to dim screens";
CM_ SG_ 271 panelBrightness_IHUB "Used in combination with panelSelectForBrightness_IHUB to dim screens";
CM_ SG_ 271 alarmModeHazard_IHUB "Flash hazard lights 3 times to indicate alarm mode.";
CM_ SG_ 271 alarmModeHorn_IHUB "Honk 3 times to indicate alarm mode.";
CM_ SG_ 520 seatCushionBolsterCmdFR_BGW "Command driver seat cushion to increment or decrement";
CM_ SG_ 520 seatTrackCmdFR_BGW "Command passenger seat slide to increment or decrement";
CM_ SG_ 520 seatLiftCmdFR_BGW "Command passenger seat lift to increment or decrement";
CM_ SG_ 520 seatBackLumbarCmdFR_BGW "Command passenger backrest to increment or decrement";
CM_ SG_ 520 seatTrackCmdFL_BGW "Command driver seat slide to increment or decrement";
CM_ SG_ 520 seatLiftCmdFL_BGW "Command driver seat lift to increment or decrement";
CM_ SG_ 520 seatBackBolsterCmdFL_BGW "Command driver backrest to increment or decrement";
CM_ SG_ 526 lightLaneChangeRightOnReq_SDCM "Right lane change request from SDCM.";
CM_ SG_ 526 lightLaneChangeLeftOnReq_SDCM "Left lane change request from SDCM";
CM_ SG_ 526 mirrorDimmingLvlReq_SDCM "Configures level of mirror dimming.";
CM_ SG_ 608 doorLockReq_DCFL "Front left door lock request";
CM_ SG_ 608 lockUnlockReq_FLLUS "Lock-Unlock Switch request";
CM_ SG_ 608 doorLatchFault_DCFL "Front left door latch fault";
CM_ SG_ 608 doorIsUnlatched_DCFL "Front left door latched or unlatched";
CM_ SG_ 608 doorMirrorState_DCFL "Left mirror retracted or presented status";
CM_ SG_ 608 doorState_DCFL "Front left door open, opening, closed, closing status";
CM_ SG_ 608 mirrorHeaterState_DCFL "Left door mirror heater status";
CM_ SG_ 608 sideRepeaterState_DCFL "Left side repeater status";
CM_ SG_ 608 doorDTCPresent_DCFL "Front left door DTC present status";
CM_ SG_ 608 mirrorStatusMovUpDownLeft_DCFL "Front left mirror up/down movement status";
CM_ SG_ 608 mirrorStatusMovInOutLeft_DCFL "Front left mirror inwords/outwords movement status";
CM_ SG_ 608 mirrorDefrostCamStatusLeft_DCFL "Front left mirror camera defrost status";
CM_ SG_ 608 mirrorFoldAutoStatusLeft_DCFL "Front left mirror auto-fold status";
CM_ SG_ 608 mirrorDimEnabDisableStatus_DCFL "Front left mirror dimming status";
CM_ SG_ 608 doorAngle_DCFL "Front left door angle to the nearest 6 degrees";
CM_ SG_ 608 doorAngleMax_DCFL "Max door angle defined for Front left door";
CM_ SG_ 609 windowReqAll_DCFL "All window request status";
CM_ SG_ 609 windowReqRearLeft_DCFL "Rear-Left window request status";
CM_ SG_ 609 windowReqRearRight_DCFL "Rear-Right window request status";
CM_ SG_ 609 windowReqFrontLeft_DCFL "Front-Left window request status";
CM_ SG_ 609 windowReqFrontRight_DCFL "Front-Right window request status";
CM_ SG_ 609 doorExtDriverRearRelease_DCFL "Body controller received command to open rear driver side door from the exterior release.";
CM_ SG_ 609 doorIntDriverRearRelease_DCFL "Body controller received command to open rear driver side door from the interior release.";
CM_ SG_ 624 seatBackBolsterPositionFL_DSM "Status of back bolster.";
CM_ SG_ 624 seatCushionBolsterPositionFL_DSM "Status of cushion bolster.";
CM_ SG_ 624 seatCushionTiltPositionFL_DSM "Tilt position of driver cushion in degrees.";
CM_ SG_ 624 seatTrackPositionFL_DSM "Driver seat module reports absolute slide position in hall counts";
CM_ SG_ 624 seatBackPositionFL_DSM "Driver seat module reports absolute backrest position in hall counts";
CM_ SG_ 624 seatLiftPositionFL_DSM "Driver seat module reports absolute lift position in hall counts";
CM_ SG_ 628 seatFrontLeftOccupied_DSM "DSM reports whether driver seat is occupied";
CM_ SG_ 648 doorLockReq_DCFR "Front right door lock request";
CM_ SG_ 648 lockUnlockReq_FRLUS "Lock-Unlock Switch request";
CM_ SG_ 648 mirrorHeaterState_DCFR "Right door mirror heater status";
CM_ SG_ 648 sideRepeaterState_DCFR "Right side repeater status";
CM_ SG_ 648 mirrorStatusMovUpDownRight_DCFR "Front right mirror up/down movement status";
CM_ SG_ 648 mirrorStatusMovInOutRight_DCFR "Front right mirror inwards/outwards movement status";
CM_ SG_ 648 mirrorDefrostCamStatusRight_DCFR "Front right mirror camera defrost status";
CM_ SG_ 648 mirrorFoldAutoStatusRight_DCFR "Front right mirror auto-fold status";
CM_ SG_ 648 mirrorDimEnabDisableStatus_DCFR "Front right mirror dimming status";
CM_ SG_ 648 doorAngle_DCFR "Front right door angle to the nearest 6 degrees";
CM_ SG_ 648 doorAngleMax_DCFR "Max door angle defined for Front right door";
CM_ SG_ 649 windowReqAll_DCFR "All window request status";
CM_ SG_ 649 windowReqRearLeft_DCFR "Rear-Left window request status";
CM_ SG_ 649 windowReqRearRight_DCFR "Rear-Right window request status";
CM_ SG_ 649 windowReqFrontLeft_DCFR "Front-Left window request status";
CM_ SG_ 649 windowReqFrontRight_DCFR "Front-Right window request status";
CM_ SG_ 649 extPassRearRelease_DCFR "Body controller received command to open rear passenger side door from the exterior release.";
CM_ SG_ 649 intPassRearRelease_DCFR "Body controller received command to open rear passenger side door from the interior release.";
CM_ SG_ 656 seatTrackPositionFR_PSM "Passenger seat module reports absolute slide position in hall counts";
CM_ SG_ 656 seatBackPositionFR_PSM "Passenger seat module reports absolute backrest position in hall counts";
CM_ SG_ 656 seatLiftPositionFR_PSM "Passenger seat module reports absolute lift position in hall counts";
CM_ SG_ 660 seatFrontRightOccupied_PSM "Passenger seat module reports whether passenger seat is occupied";
CM_ SG_ 688 seatBackPositionRL_RLSM "Rear left seat module reports absolute backrest position in hall counts";
CM_ SG_ 688 seatLegExtPositionRL_RLSM "Rear left seat module reports absolute leg extension position in hall counts";
CM_ SG_ 688 seatLegSwivelPositionRL_RLSM "Rear left seat module reports absolute leg support position in hall counts";
CM_ SG_ 692 seatRearLeftOccupied_RLSM "Rear left seat module reports whether seat is occupied";
CM_ SG_ 724 seatRearRightOccupied_RRSM "Rear right seat module reports whether seat is occupied";
CM_ SG_ 779 sequenceId_BGW "Set exterior lighting sequence";
CM_ SG_ 781 seatBackAbsPosDSM_BGW "Set the driver seat back tilt position in degrees.";
CM_ SG_ 781 seatTrackAbsPosDSM_BGW "Set driver seat slide position in millimeters.";
CM_ SG_ 781 seatLiftAbsPosDSM_BGW "Set driver seat lift position in millimeters.";
CM_ SG_ 783 seatBackAbsPosRLSM_BGW "Set rear left seat back tilt position in degrees.";
CM_ SG_ 783 seatLegExtAbsPosRLSM_BGW "Set rear left seat leg extension position in millimeters.";
CM_ SG_ 783 seatLegSwivelAbsPosRLSM_BGW "Set rear left seat leg swivel position in degrees.";
CM_ SG_ 1032 driveMode_BGW "Defines vehicle level drive mode/status.";
CM_ SG_ 1032 hvacRailReq_BGW "Gateway is requesting enable of the HVAC 12V rail";
CM_ SG_ 1032 wiperCmd_BGW "Wiper Command from BGW";
CM_ SG_ 1032 chassisWakeup_BGW "Request enable of chassis relay control";
CM_ SG_ 1032 driveRequestState_BGW "This request signal is sent by the BGW to the FBCM and RBCM. If TRUE, make state transition from Accessory to Drive. If FALSE, make state transition from Drive to Accessory.";
CM_ SG_ 1032 accessoryRequestState_BGW "This request signal is sent by the BGW to the FBCM and RBCM. If TRUE, make state transition from Standby to Accessory. If FALSE, make state transition from Accessory to Standby.";
CM_ SG_ 1032 selfDriveRequestState_BGW "This request signal is sent by the BGW to the FBCM and RBCM. If TRUE, make state transition from Accessory to Self Drive. If FALSE, make state transition from Self Drive to Accessory.";
CM_ SG_ 1032 hornOnReq_BGW "Request horns to be actuated by FBCM";
CM_ SG_ 1032 wiperNozzleDefrostReq_BGW "Request FBCM and ECPM to turn on defrost controls";
CM_ SG_ 1033 exteriorLightReq_IHUB "Request exterior lights.";
CM_ SG_ 1033 frunkLockReq_IHUB "REVIEW locking strategy. IHUB requests FBCM to lock front trunk";
CM_ SG_ 1033 liftgateLockReq_IHUB "REVIEW locking strategy. IHUB requests FBCM to lock liftgate";
CM_ SG_ 1033 doorRRLockReq_IHUB "REVIEW locking strategy. IHUB requests FBCM to lock rear right door";
CM_ SG_ 1033 doorRLLockReq_IHUB "REVIEW locking strategy. IHUB requests FBCM to lock rear left door";
CM_ SG_ 1033 doorFRLockReq_IHUB "REVIEW locking strategy. IHUB requests FBCM to lock front right door";
CM_ SG_ 1033 doorFLLockReq_IHUB "REVIEW locking strategy. IHUB requests FBCM to lock front left door";
CM_ SG_ 1033 doorRearRightOperation_IHUB "Request door to open, close, pop";
CM_ SG_ 1033 doorRearLeftOperation_IHUB "Request door to open, close, pop";
CM_ SG_ 1033 doorFrontRightOperation_IHUB "Request door to open, close, pop";
CM_ SG_ 1033 doorFrontLeftOperation_IHUB "Request door to open, close, pop";
CM_ SG_ 1033 lightLowBeamOnReq_IHUB "Request low beams on/off";
CM_ SG_ 1033 frontHoodOpen_IHUB "Request FBCM to pop hood (front trunk)";
CM_ SG_ 1033 fogSwitchRear_IHUB "Request rear fog lights on/off";
CM_ SG_ 1033 fogSwitchFront_IHUB "Request front fog lights on/off";
CM_ SG_ 1033 steeringHeatEnabled_IHUB "Request steering heat on/off";
CM_ SG_ 1035 childLockStatus_BGW "Master child lock value for window and door";
CM_ SG_ 1035 wakeUpCause_BGW "Debug signal for BGW to know the wake-up cause.";
CM_ SG_ 1035 lightFogRearStatus_BGW "Status of the rear fog light";
CM_ SG_ 1035 doorRLLockStatus_BGW "Rear-Left door lock status";
CM_ SG_ 1035 liftgateLockStatus_BGW "Liftgate lock status";
CM_ SG_ 1035 doorRRLockStatus_BGW "Rear-Right door lock status";
CM_ SG_ 1035 doorFRLockStatus_BGW "Front-Right door lock status";
CM_ SG_ 1035 doorFLLockStatus_BGW "Front-Left door lock status";
CM_ SG_ 1035 doorSwitchCpillarLeft_BGW "Rear left door open/close request from C-Pillar Door Switch";
CM_ SG_ 1035 doorSwitchCpillarRight_BGW "Rear right door open/close from C-Pillar Door Switch";
CM_ SG_ 1037 lightLowBeamOnReq_BGW "REMOVE for Beta only";
CM_ SG_ 1037 lightDomeOnReq_BGW "Gateway is requesting enable of the dome light";
CM_ SG_ 1037 lightHighBeamOnReq_BGW "RENAME, GATEWAYED from ADAS";
CM_ SG_ 1039 rightSeatBeltBcklState_SRS "When bit is set to '1', seat belt buckle is latched.";
CM_ SG_ 1039 leftSeatBeltBcklState_SRS "When bit is set to '1', seat belt buckle is latched.";
CM_ SG_ 1039 lightStopOnReq_PTC "Brake Light Request";
CM_ SG_ 1039 userSOE_BPG "HV battery state of charge for B-Pillar display";
CM_ SG_ 1039 lowVoltagePowerMode_DABM "Power management strategy";
CM_ SG_ 1039 timeChargeToFullEstimated_BPG "Time to full charge for B-Pillar display";
CM_ SG_ 1039 chargePortOpenAuthorize_BPG "Signal is set to False if contacts are welded, otherwise True";
CM_ SG_ 1041 lightDRLOnReq_FBCM "Daytime running lights on request.";
CM_ SG_ 1041 lightSync_FBCM "To sync the front and rear turn and hazard lights";
CM_ SG_ 1041 lightHighBeamOnReq_FBCM "RENAME lightHighBeamOnReq_FBCM. High Beam headlight on request";
CM_ SG_ 1041 lightTurnRightOnReq_FBCM "RENAME lightTurnRightOnReq_FBCM. Turn right on request from FBCM";
CM_ SG_ 1041 lightTurnLeftOnReq_FBCM "RENAME lightTurnLeftOnReq_FBCM. Turn Left on request from FBCM";
CM_ SG_ 1041 lightLowBeamOnReq_FBCM "RENAME lightLowBeamOnReq_FBCM. Low Beam headlight on request from FBCM";
CM_ SG_ 1041 lightHazardActive_FBCM "Front Hazard light status. Do not remove as its needed for compatibility with hazard lights";
CM_ SG_ 1041 lightStopOnReq_FBCM "Signal to turn on the brake lights from FBCM";
CM_ SG_ 1045 swchStateHighBeam_FBCM "stalk switch status from FBCM lin1 SCCM";
CM_ SG_ 1045 scStatus_FBCM "Placeholder 2 bit status";
CM_ SG_ 1045 frontTrunkStatus_FBCM "Front trunk open status";
CM_ SG_ 1045 lockRejected_FBCM "The lock request was rejected";
CM_ SG_ 1045 steeringHeatStatus_FBCM "Return steering heat on/off status";
BA_DEF_ BO_  "CloudLogRate" INT 0 65000;
BA_DEF_ SG_  "ExpirationValue" STRING ;
BA_DEF_ BO_  "MsgTxIsRx" INT 0 1;
BA_DEF_ BO_  "DebugMessage" INT 0 1;
BA_DEF_ BO_  "DebugMessageTransmitAlways" INT 0 1;
BA_DEF_ BO_  "DiagRequest" ENUM  "No","Yes";
BA_DEF_ BO_  "GatewayHandlerEnum" ENUM  "noHandler","uds","alertLog","messageLogOnReception","udsClient";
BA_DEF_ BO_  "GatewayMessageSendType" ENUM  "UseGenMsgSendType","onWrite","noAutoCode";
BA_DEF_ BO_  "GenMsgCycleTime" INT 0 65000;
BA_DEF_ BO_  "GenMsgGatewayNotification" STRING ;
BA_DEF_ BO_  "GenMsgILSupport" ENUM  "No","Yes";
BA_DEF_ BO_  "GenMsgMinAcceptLength" INT 0 0;
BA_DEF_ BO_  "GenMsgSendType" ENUM  "Cyclic","IfActive","NoMsgSendType","OnEvent";
BA_DEF_ BO_  "GenMsgTimeoutTime" INT 0 10000;
BA_DEF_ BO_  "Type" ENUM  "-","P","E","PE","vector_leerstring";
BA_DEF_ BO_  "cycleMilliSecs100" INT 0 100;
BA_DEF_ BO_  "receiveMsgFromEthernet" INT 0 1;
BA_DEF_ BO_  "sendMsgToEthernet" INT 0 1;
BA_DEF_ BO_  "targetGw" ENUM  "BPG","BGW","IHUB","SDCM","BGW,IHUB","BGW,BPG","BPG,IHUB","SDCM,IHUB","SDCM,BGW","SDCM,BPG","ALL","SDCM,ADC","IHUB,ADC","IHUB,BGW,ADC","ADC","ADC,BGW","SDCM,ADC,IHUB";
BA_DEF_ BO_  "targetMsgECUs" ENUM  "BPG","BGW","IVI","SDCM","ALL","vector_leerstring";
BA_DEF_ BO_  "transmitMsgRateEthernetMs" ENUM  "100","1000","0","10000","250","500","10","20","40","200","50";
BA_DEF_ SG_  "GatewayedSignal" INT 0 1;
BA_DEF_ SG_  "GenSigEnvVarType" ENUM  "int","float","undef";
BA_DEF_ SG_  "GenSigInactiveValue" INT 0 0;
BA_DEF_ SG_  "GenSigSNA" STRING ;
BA_DEF_ SG_  "GenSigSendType" ENUM  "Cyclic","OnWrite","OnWriteWithRepetition","OnChange","OnChangeWithRepetition","IfActive","IfActiveWithRepetition","NoSigSendType";
BA_DEF_ SG_  "GenSigStartValue" INT 0 0;
BA_DEF_ SG_  "OriginatingECU" STRING ;
BA_DEF_ SG_  "SNARequired" ENUM  "Required","NotRequired";
BA_DEF_DEF_  "CloudLogRate" 1000;
BA_DEF_DEF_  "ExpirationValue" "";
BA_DEF_DEF_  "MsgTxIsRx" 0;
BA_DEF_DEF_  "DebugMessage" 0;
BA_DEF_DEF_  "DebugMessageTransmitAlways" 0;
BA_DEF_DEF_  "DiagRequest" "No";
BA_DEF_DEF_  "GatewayHandlerEnum" "noHandler";
BA_DEF_DEF_  "GatewayMessageSendType" "UseGenMsgSendType";
BA_DEF_DEF_  "GenMsgCycleTime" 0;
BA_DEF_DEF_  "GenMsgGatewayNotification" "";
BA_DEF_DEF_  "GenMsgILSupport" "Yes";
BA_DEF_DEF_  "GenMsgMinAcceptLength" 8;
BA_DEF_DEF_  "GenMsgSendType" "NoMsgSendType";
BA_DEF_DEF_  "GenMsgTimeoutTime" 0;
BA_DEF_DEF_  "Type" "";
BA_DEF_DEF_  "cycleMilliSecs100" 100;
BA_DEF_DEF_  "receiveMsgFromEthernet" 0;
BA_DEF_DEF_  "sendMsgToEthernet" 0;
BA_DEF_DEF_  "targetGw" "ALL";
BA_DEF_DEF_  "targetMsgECUs" "";
BA_DEF_DEF_  "transmitMsgRateEthernetMs" "1000";
BA_DEF_DEF_  "GatewayedSignal" 0;
BA_DEF_DEF_  "GenSigEnvVarType" "undef";
BA_DEF_DEF_  "GenSigInactiveValue" 0;
BA_DEF_DEF_  "GenSigSNA" "";
BA_DEF_DEF_  "GenSigSendType" "NoSigSendType";
BA_DEF_DEF_  "GenSigStartValue" 0;
BA_DEF_DEF_  "OriginatingECU" "";
BA_DEF_DEF_  "SNARequired" "Required";
BA_ "receiveMsgFromEthernet" BO_ 367 1;
BA_ "GenMsgSendType" BO_ 367 0;
BA_ "GenMsgCycleTime" BO_ 367 100;
BA_ "transmitMsgRateEthernetMs" BO_ 534 2;
BA_ "targetGw" BO_ 534 2;
BA_ "sendMsgToEthernet" BO_ 534 1;
BA_ "transmitMsgRateEthernetMs" BO_ 529 4;
BA_ "targetGw" BO_ 529 7;
BA_ "GenMsgSendType" BO_ 529 0;
BA_ "GenMsgCycleTime" BO_ 529 250;
BA_ "sendMsgToEthernet" BO_ 529 1;
BA_ "transmitMsgRateEthernetMs" BO_ 530 4;
BA_ "targetGw" BO_ 530 7;
BA_ "GenMsgSendType" BO_ 530 0;
BA_ "GenMsgCycleTime" BO_ 530 250;
BA_ "sendMsgToEthernet" BO_ 530 1;
BA_ "GenMsgCycleTime" BO_ 716 10000;
BA_ "GenMsgSendType" BO_ 716 0;
BA_ "GenMsgCycleTime" BO_ 684 10000;
BA_ "GenMsgSendType" BO_ 684 0;
BA_ "GenMsgCycleTime" BO_ 652 10000;
BA_ "GenMsgSendType" BO_ 652 0;
BA_ "GenMsgCycleTime" BO_ 612 10000;
BA_ "GenMsgSendType" BO_ 612 0;
BA_ "GenMsgCycleTime" BO_ 14 1000;
BA_ "GenMsgSendType" BO_ 14 0;
BA_ "GenMsgCycleTime" BO_ 15 1000;
BA_ "GenMsgSendType" BO_ 15 0;
BA_ "GenMsgCycleTime" BO_ 265 10000;
BA_ "GenMsgSendType" BO_ 265 0;
BA_ "GenMsgCycleTime" BO_ 269 100;
BA_ "GenMsgSendType" BO_ 269 0;
BA_ "receiveMsgFromEthernet" BO_ 269 1;
BA_ "transmitMsgRateEthernetMs" BO_ 269 0;
BA_ "transmitMsgRateEthernetMs" BO_ 714 2;
BA_ "targetGw" BO_ 714 2;
BA_ "sendMsgToEthernet" BO_ 714 1;
BA_ "transmitMsgRateEthernetMs" BO_ 682 2;
BA_ "targetGw" BO_ 682 2;
BA_ "sendMsgToEthernet" BO_ 682 1;
BA_ "transmitMsgRateEthernetMs" BO_ 650 2;
BA_ "targetGw" BO_ 650 2;
BA_ "sendMsgToEthernet" BO_ 650 1;
BA_ "transmitMsgRateEthernetMs" BO_ 610 2;
BA_ "targetGw" BO_ 610 2;
BA_ "sendMsgToEthernet" BO_ 610 1;
BA_ "GenMsgCycleTime" BO_ 267 100;
BA_ "GenMsgSendType" BO_ 267 0;
BA_ "receiveMsgFromEthernet" BO_ 267 1;
BA_ "targetGw" BO_ 271 1;
BA_ "GenMsgCycleTime" BO_ 271 100;
BA_ "GenMsgSendType" BO_ 271 0;
BA_ "receiveMsgFromEthernet" BO_ 271 1;
BA_ "transmitMsgRateEthernetMs" BO_ 271 5;
BA_ "GatewayMessageSendType" BO_ 520 1;
BA_ "targetMsgECUs" BO_ 520 5;
BA_ "transmitMsgRateEthernetMs" BO_ 520 2;
BA_ "GenMsgCycleTime" BO_ 526 250;
BA_ "GenMsgSendType" BO_ 526 0;
BA_ "transmitMsgRateEthernetMs" BO_ 608 4;
BA_ "targetGw" BO_ 608 2;
BA_ "MsgTxIsRx" BO_ 608 1;
BA_ "GenMsgCycleTime" BO_ 608 250;
BA_ "GenMsgSendType" BO_ 608 0;
BA_ "sendMsgToEthernet" BO_ 608 1;
BA_ "transmitMsgRateEthernetMs" BO_ 609 2;
BA_ "targetGw" BO_ 609 2;
BA_ "MsgTxIsRx" BO_ 609 1;
BA_ "sendMsgToEthernet" BO_ 609 1;
BA_ "transmitMsgRateEthernetMs" BO_ 611 5;
BA_ "targetGw" BO_ 611 2;
BA_ "GenMsgCycleTime" BO_ 611 500;
BA_ "GenMsgSendType" BO_ 611 0;
BA_ "sendMsgToEthernet" BO_ 611 1;
BA_ "GenMsgSendType" BO_ 264 3;
BA_ "transmitMsgRateEthernetMs" BO_ 264 2;
BA_ "receiveMsgFromEthernet" BO_ 264 1;
BA_ "transmitMsgRateEthernetMs" BO_ 624 0;
BA_ "sendMsgToEthernet" BO_ 624 1;
BA_ "GenMsgCycleTime" BO_ 624 100;
BA_ "GenMsgSendType" BO_ 624 0;
BA_ "Type" BO_ 624 1;
BA_ "targetGw" BO_ 624 2;
BA_ "targetMsgECUs" BO_ 624 5;
BA_ "targetGw" BO_ 628 2;
BA_ "transmitMsgRateEthernetMs" BO_ 628 0;
BA_ "GenMsgCycleTime" BO_ 628 100;
BA_ "GenMsgSendType" BO_ 628 0;
BA_ "GenMsgTimeoutTime" BO_ 628 2500;
BA_ "Type" BO_ 628 3;
BA_ "sendMsgToEthernet" BO_ 628 1;
BA_ "targetMsgECUs" BO_ 628 5;
BA_ "transmitMsgRateEthernetMs" BO_ 648 4;
BA_ "targetGw" BO_ 648 2;
BA_ "MsgTxIsRx" BO_ 648 1;
BA_ "GenMsgCycleTime" BO_ 648 250;
BA_ "GenMsgSendType" BO_ 648 0;
BA_ "sendMsgToEthernet" BO_ 648 1;
BA_ "transmitMsgRateEthernetMs" BO_ 649 2;
BA_ "targetGw" BO_ 649 2;
BA_ "MsgTxIsRx" BO_ 649 1;
BA_ "sendMsgToEthernet" BO_ 649 1;
BA_ "transmitMsgRateEthernetMs" BO_ 651 5;
BA_ "targetGw" BO_ 651 2;
BA_ "GenMsgCycleTime" BO_ 651 500;
BA_ "GenMsgSendType" BO_ 651 0;
BA_ "sendMsgToEthernet" BO_ 651 1;
BA_ "sendMsgToEthernet" BO_ 656 1;
BA_ "GenMsgCycleTime" BO_ 656 100;
BA_ "GenMsgSendType" BO_ 656 0;
BA_ "Type" BO_ 656 2;
BA_ "targetGw" BO_ 656 2;
BA_ "targetMsgECUs" BO_ 656 5;
BA_ "transmitMsgRateEthernetMs" BO_ 656 0;
BA_ "transmitMsgRateEthernetMs" BO_ 660 0;
BA_ "targetGw" BO_ 660 2;
BA_ "GenMsgCycleTime" BO_ 660 100;
BA_ "GenMsgSendType" BO_ 660 0;
BA_ "GenMsgTimeoutTime" BO_ 660 2500;
BA_ "Type" BO_ 660 3;
BA_ "sendMsgToEthernet" BO_ 660 1;
BA_ "targetMsgECUs" BO_ 660 5;
BA_ "targetGw" BO_ 688 2;
BA_ "sendMsgToEthernet" BO_ 688 1;
BA_ "GenMsgCycleTime" BO_ 688 100;
BA_ "GenMsgSendType" BO_ 688 0;
BA_ "Type" BO_ 688 2;
BA_ "transmitMsgRateEthernetMs" BO_ 688 0;
BA_ "transmitMsgRateEthernetMs" BO_ 692 0;
BA_ "targetGw" BO_ 692 2;
BA_ "GenMsgCycleTime" BO_ 692 100;
BA_ "GenMsgSendType" BO_ 692 0;
BA_ "GenMsgTimeoutTime" BO_ 692 2500;
BA_ "Type" BO_ 692 3;
BA_ "sendMsgToEthernet" BO_ 692 1;
BA_ "targetMsgECUs" BO_ 692 5;
BA_ "targetGw" BO_ 720 2;
BA_ "sendMsgToEthernet" BO_ 720 1;
BA_ "GenMsgCycleTime" BO_ 720 100;
BA_ "GenMsgSendType" BO_ 720 0;
BA_ "Type" BO_ 720 2;
BA_ "transmitMsgRateEthernetMs" BO_ 720 0;
BA_ "transmitMsgRateEthernetMs" BO_ 724 0;
BA_ "targetGw" BO_ 724 2;
BA_ "GenMsgCycleTime" BO_ 724 100;
BA_ "GenMsgSendType" BO_ 724 0;
BA_ "GenMsgTimeoutTime" BO_ 724 2500;
BA_ "Type" BO_ 724 3;
BA_ "sendMsgToEthernet" BO_ 724 1;
BA_ "targetMsgECUs" BO_ 724 5;
BA_ "transmitMsgRateEthernetMs" BO_ 779 2;
BA_ "targetMsgECUs" BO_ 781 5;
BA_ "transmitMsgRateEthernetMs" BO_ 781 2;
BA_ "targetMsgECUs" BO_ 783 5;
BA_ "transmitMsgRateEthernetMs" BO_ 783 2;
BA_ "GenMsgCycleTime" BO_ 800 100;
BA_ "GenMsgSendType" BO_ 800 0;
BA_ "DebugMessage" BO_ 801 1;
BA_ "GenMsgCycleTime" BO_ 801 100;
BA_ "GenMsgSendType" BO_ 801 0;
BA_ "DebugMessage" BO_ 805 1;
BA_ "GenMsgCycleTime" BO_ 805 100;
BA_ "GenMsgSendType" BO_ 805 0;
BA_ "DebugMessage" BO_ 807 1;
BA_ "GenMsgCycleTime" BO_ 807 100;
BA_ "GenMsgSendType" BO_ 807 0;
BA_ "GenMsgCycleTime" BO_ 1032 100;
BA_ "GenMsgSendType" BO_ 1032 0;
BA_ "GenMsgCycleTime" BO_ 1033 100;
BA_ "GenMsgSendType" BO_ 1033 0;
BA_ "receiveMsgFromEthernet" BO_ 1033 1;
BA_ "transmitMsgRateEthernetMs" BO_ 1033 0;
BA_ "targetGw" BO_ 1035 1;
BA_ "GenMsgCycleTime" BO_ 1035 100;
BA_ "GenMsgSendType" BO_ 1035 0;
BA_ "GenMsgSendType" BO_ 1038 3;
BA_ "transmitMsgRateEthernetMs" BO_ 1038 2;
BA_ "GenMsgCycleTime" BO_ 1039 100;
BA_ "GenMsgSendType" BO_ 1039 0;
BA_ "receiveMsgFromEthernet" BO_ 1039 1;
BA_ "transmitMsgRateEthernetMs" BO_ 1039 0;
BA_ "transmitMsgRateEthernetMs" BO_ 1041 0;
BA_ "targetGw" BO_ 1041 2;
BA_ "sendMsgToEthernet" BO_ 1041 1;
BA_ "GenMsgSendType" BO_ 1041 0;
BA_ "GenMsgCycleTime" BO_ 1041 100;
BA_ "transmitMsgRateEthernetMs" BO_ 1043 0;
BA_ "targetGw" BO_ 1043 6;
BA_ "GenMsgSendType" BO_ 1043 0;
BA_ "GenMsgCycleTime" BO_ 1043 100;
BA_ "sendMsgToEthernet" BO_ 1043 1;
BA_ "transmitMsgRateEthernetMs" BO_ 532 2;
BA_ "sendMsgToEthernet" BO_ 532 1;
BA_ "transmitMsgRateEthernetMs" BO_ 1045 0;
BA_ "targetGw" BO_ 1045 7;
BA_ "CloudLogRate" BO_ 1045 0;
BA_ "GenMsgCycleTime" BO_ 1045 100;
BA_ "GenMsgSendType" BO_ 1045 0;
BA_ "sendMsgToEthernet" BO_ 1045 1;
BA_ "targetGw" BO_ 1046 6;
BA_ "GenMsgCycleTime" BO_ 1046 1000;
BA_ "GenMsgSendType" BO_ 1046 0;
BA_ "sendMsgToEthernet" BO_ 1046 1;
BA_ "GenSigSendType" SG_ 1160 demIRSensor2MIA_DCFR 1;
BA_ "GenSigSendType" SG_ 1160 demIRSensor1MIA_DCFR 1;
BA_ "GenSigSendType" SG_ 1160 demWinSwErr_DCFR 1;
BA_ "GenSigSendType" SG_ 1160 demWinSwMIA_DCFR 1;
BA_ "GenSigSendType" SG_ 1160 demLINNetworkFail_DCFR 1;
BA_ "GenSigSendType" SG_ 1160 demBodyCANAmbTempMsgErr_DCFR 1;
BA_ "GenSigSendType" SG_ 1160 demBodyCANAmbTempMsgMiss_DCFR 1;
BA_ "GenSigSendType" SG_ 1160 demBodyCANCrashMsgErr_DCFR 1;
BA_ "GenSigSendType" SG_ 1160 demBodyCANCrashMsgMiss_DCFR 1;
BA_ "GenSigSendType" SG_ 1160 demBodyCANChildLkMsgErr_DCFR 1;
BA_ "GenSigSendType" SG_ 1160 demBodyCANChildLkMsgMiss_DCFR 1;
BA_ "GenSigSendType" SG_ 1160 demBodyCANLockMessageError_DCFR 1;
BA_ "GenSigSendType" SG_ 1160 demBodyCANLkUnlkMsgMiss_DCFR 1;
BA_ "GenSigSendType" SG_ 1160 demBodyCANOpClMsgErr_DCFR 1;
BA_ "GenSigSendType" SG_ 1160 demBodyCANOpClMsgMiss_DCFR 1;
BA_ "GenSigSendType" SG_ 1160 demBodyCANIMUMessageError_DCFR 1;
BA_ "GenSigSendType" SG_ 1160 demBodyCANIMUMsgMiss_DCFR 1;
BA_ "GenSigSendType" SG_ 1160 demBodyCANVehSpdMsgErr_DCFR 1;
BA_ "GenSigSendType" SG_ 1160 demBodyCANVehSpdMsgMiss_DCFR 1;
BA_ "GenSigSendType" SG_ 1160 demBodyCANNetworkFailure_DCFR 1;
BA_ "GenSigSendType" SG_ 1160 demMirrorGlassPosSnsShCir_DCFR 1;
BA_ "GenSigSendType" SG_ 1160 demMirrorGlassPosSnsOpenCir_DCFR 1;
BA_ "GenSigSendType" SG_ 1160 demMirrorGlassPosSnsSnEr_DCFR 1;
BA_ "GenSigSendType" SG_ 1160 demMirrorGlassPosSnsSnLoss_DCFR 1;
BA_ "GenSigSendType" SG_ 1160 demMirrorGlassPosNotReached_DCFR 1;
BA_ "GenSigSendType" SG_ 1160 demMirrorGlassMvtUcmd_DCFR 1;
BA_ "GenSigSendType" SG_ 1160 demMirrorGlassMvFail_DCFR 1;
BA_ "GenSigSendType" SG_ 1160 demIntOpenSwSnEr_DCFR 1;
BA_ "GenSigSendType" SG_ 1160 demIntOpenSwSnLoss_DCFR 1;
BA_ "GenSigSendType" SG_ 1160 demIntRelSwSnEr_DCFR 1;
BA_ "GenSigSendType" SG_ 1160 demInteriorReleaseSwSnLoss_DCFR 1;
BA_ "GenSigSendType" SG_ 1160 demDoorUnlockSwSnError_DCFR 1;
BA_ "GenSigSendType" SG_ 655 demDoorLockSwitchSignalLoss_DCFR 1;
BA_ "GenSigSendType" SG_ 655 demDoorExtCapSwSnEr_DCFR 1;
BA_ "GenSigSendType" SG_ 655 demDoorExtCapSwSnLoss_DCFR 1;
BA_ "GenSigSendType" SG_ 655 demDoorExtCapSwPower_DCFR 1;
BA_ "GenSigSendType" SG_ 655 demDoorExtCapSwNoPower_DCFR 1;
BA_ "GenSigSendType" SG_ 655 demDoorExtMechSwSnEr_DCFR 1;
BA_ "GenSigSendType" SG_ 655 demDoorExtMechSwSnLoss_DCFR 1;
BA_ "GenSigSendType" SG_ 655 demDoorExtMechSwPower_DCFR 1;
BA_ "GenSigSendType" SG_ 655 demDoorExtMechSwPowerLoss_DCFR 1;
BA_ "GenSigSendType" SG_ 655 demWindowHallSignalError_DCFR 1;
BA_ "GenSigSendType" SG_ 655 demWindowHallSnsPowerLoss_DCFR 1;
BA_ "GenSigSendType" SG_ 655 demWindowHallSignalLoss_DCFR 1;
BA_ "GenSigSendType" SG_ 655 demWindowVelocityTimeout_DCFR 1;
BA_ "GenSigSendType" SG_ 655 demCinchCloseSignalError_DCFR 1;
BA_ "GenSigSendType" SG_ 655 demReverseCinchTimeout_DCFR 1;
BA_ "GenSigSendType" SG_ 655 demCinchOpenSignalError_DCFR 1;
BA_ "GenSigSendType" SG_ 655 demDoorCinchTimeout_DCFR 1;
BA_ "GenSigSendType" SG_ 655 demDoorLatchOpenAlwaysOn_DCFR 1;
BA_ "GenSigSendType" SG_ 655 demDoorLatchOpenPowerLoss_DCFR 1;
BA_ "GenSigSendType" SG_ 655 demDoorLatchOpenSignalError_DCFR 1;
BA_ "GenSigSendType" SG_ 655 demDoorLatchOpenSignalLoss_DCFR 1;
BA_ "GenSigSendType" SG_ 655 demDoorLatchPawlSignalError_DCFR 1;
BA_ "GenSigSendType" SG_ 655 demDoorLatchPawlSignalLoss_DCFR 1;
BA_ "GenSigSendType" SG_ 655 demDoorLatchSensorSnError_DCFR 1;
BA_ "GenSigSendType" SG_ 655 demDoorLatchAjarSigLoss_DCFR 1;
BA_ "GenSigSendType" SG_ 655 demDoorBrakeHallSnLoss_DCFR 1;
BA_ "GenSigSendType" SG_ 655 demDoorHallSensorSnErr_DCFR 1;
BA_ "GenSigSendType" SG_ 655 doorHallSensorSlow_DCFR 1;
BA_ "GenSigSendType" SG_ 655 demDoorHallSensorFast_DCFR 1;
BA_ "GenSigSendType" SG_ 655 demDoorHallSensorSignalLoss_DCFR 1;
BA_ "GenSigSendType" SG_ 655 demMirrorMovetUncmd_DCFR 1;
BA_ "GenSigSendType" SG_ 655 demMirrorMovementFailure_DCFR 1;
BA_ "GenSigSendType" SG_ 654 demDEMNotification_DCFR 1;
BA_ "GenSigSendType" SG_ 654 demDEMAssert_DCFR 1;
BA_ "GenSigSendType" SG_ 654 demWindowDownFailure_DCFR 1;
BA_ "GenSigSendType" SG_ 654 demWindowDownUncommanded_DCFR 1;
BA_ "GenSigSendType" SG_ 654 demWindowUpUncommanded_DCFR 1;
BA_ "GenSigSendType" SG_ 654 demWindowUpFailure_DCFR 1;
BA_ "GenSigSendType" SG_ 654 demDoorCinchUncommanded_DCFR 1;
BA_ "GenSigSendType" SG_ 654 demDoorCinchReleaseFailure_DCFR 1;
BA_ "GenSigSendType" SG_ 654 demDoorMovementFault_DCFR 1;
BA_ "GenSigSendType" SG_ 654 demDoorCloseUncommanded_DCFR 1;
BA_ "GenSigSendType" SG_ 654 demDoorCloseFailure_DCFR 1;
BA_ "GenSigSendType" SG_ 654 demLatchTimeout_DCFR 1;
BA_ "GenSigSendType" SG_ 654 demDoorDirectionFault_DCFR 1;
BA_ "GenSigSendType" SG_ 654 demDoorOpenUncommanded_DCFR 1;
BA_ "GenSigSendType" SG_ 654 demDoorOpenFailure_DCFR 1;
BA_ "GenSigSendType" SG_ 654 demMirrorMotorSignalLoss_DCFR 1;
BA_ "GenSigSendType" SG_ 654 demMirrorMotorOvercurrent_DCFR 1;
BA_ "GenSigSendType" SG_ 654 demWindowMotorSignalLoss_DCFR 1;
BA_ "GenSigSendType" SG_ 654 demWindowCurrentFailure_DCFR 1;
BA_ "GenSigSendType" SG_ 654 demWindowMotorUndercurrent_DCFR 1;
BA_ "GenSigSendType" SG_ 654 demWindowMotorOvercurrent_DCFR 1;
BA_ "GenSigSendType" SG_ 654 demCinchMotorPowerLoss_DCFR 1;
BA_ "GenSigSendType" SG_ 654 demCinchMotorOvercurrent_DCFR 1;
BA_ "GenSigSendType" SG_ 654 demLatchUncommandedOpen_DCFR 1;
BA_ "GenSigSendType" SG_ 654 demDoorLatchStateError_DCFR 1;
BA_ "GenSigSendType" SG_ 654 demDoorLatchPowerLoss_DCFR 1;
BA_ "GenSigSendType" SG_ 654 demLatchMotorOvercurrent_DCFR 1;
BA_ "GenSigSendType" SG_ 654 demDoorBrakeMotorSignalLoss_DCFR 1;
BA_ "GenSigSendType" SG_ 654 demDoorBrakeOvercurrent_DCFR 1;
BA_ "GenSigSendType" SG_ 654 demDoorCurrentSignalLoss_DCFR 1;
BA_ "GenSigSendType" SG_ 654 demDoorMotorCurrentFailure_DCFR 1;
BA_ "GenSigSendType" SG_ 654 demDoorMotorOvercurrent_DCFR 1;
BA_ "GenSigSendType" SG_ 896 changeBaudRate_TOOL 1;
BA_ "GatewayedSignal" SG_ 367 steeringAngle_SAS 1;
BA_ "OriginatingECU" SG_ 367 steeringAngle_SAS "SAS";
BA_ "GatewayedSignal" SG_ 367 rollRate_SRS 1;
BA_ "OriginatingECU" SG_ 367 rollRate_SRS "SRS";
BA_ "GatewayedSignal" SG_ 367 statePRND_PTC 1;
BA_ "OriginatingECU" SG_ 367 statePRND_PTC "PTC";
BA_ "GenSigSendType" SG_ 534 fimPreventDrive_FBCM 1;
BA_ "GatewayedSignal" SG_ 534 eventsUnread_FBCM 1;
BA_ "GenSigSendType" SG_ 534 eventsUnread_FBCM 1;
BA_ "OriginatingECU" SG_ 534 eventsUnread_FBCM "FBCM";
BA_ "GenSigSendType" SG_ 534 eventNotification_FBCM 1;
BA_ "GenSigSendType" SG_ 534 eventAssert_FBCM 1;
BA_ "OriginatingECU" SG_ 529 rlsMessageCounter_FBCM "FBCM";
BA_ "SNARequired" SG_ 529 rlsMessageCounter_FBCM 1;
BA_ "GatewayedSignal" SG_ 529 wiperSpeedRls_FBCM 1;
BA_ "OriginatingECU" SG_ 529 wiperSpeedRls_FBCM "FBCM";
BA_ "SNARequired" SG_ 529 wiperSpeedRls_FBCM 1;
BA_ "GatewayedSignal" SG_ 529 headLightsOnRls_FBCM 1;
BA_ "OriginatingECU" SG_ 529 headLightsOnRls_FBCM "FBCM";
BA_ "SNARequired" SG_ 529 headLightsOnRls_FBCM 1;
BA_ "GatewayedSignal" SG_ 529 rsSchwallRls_FBCM 1;
BA_ "OriginatingECU" SG_ 529 rsSchwallRls_FBCM "FBCM";
BA_ "SNARequired" SG_ 529 rsSchwallRls_FBCM 1;
BA_ "GatewayedSignal" SG_ 529 ambientBrightnessRls_FBCM 1;
BA_ "OriginatingECU" SG_ 529 ambientBrightnessRls_FBCM "FBCM";
BA_ "SNARequired" SG_ 529 ambientBrightnessRls_FBCM 1;
BA_ "GatewayedSignal" SG_ 529 rlsStatus_FBCM 1;
BA_ "OriginatingECU" SG_ 529 rlsStatus_FBCM "FBCM";
BA_ "SNARequired" SG_ 529 rlsStatus_FBCM 1;
BA_ "OriginatingECU" SG_ 529 rsErr_FBCM "FBCM";
BA_ "SNARequired" SG_ 529 rsErr_FBCM 1;
BA_ "GatewayedSignal" SG_ 529 lsErr_FBCM 1;
BA_ "OriginatingECU" SG_ 529 lsErr_FBCM "FBCM";
BA_ "SNARequired" SG_ 529 lsErr_FBCM 1;
BA_ "OriginatingECU" SG_ 529 rlsCommunication_FBCM "FBCM";
BA_ "SNARequired" SG_ 529 rlsCommunication_FBCM 1;
BA_ "GatewayedSignal" SG_ 529 helligkeitIr_FBCM 1;
BA_ "OriginatingECU" SG_ 529 helligkeitIr_FBCM "FBCM";
BA_ "SNARequired" SG_ 529 helligkeitIr_FBCM 1;
BA_ "GatewayedSignal" SG_ 529 helligkeitFw_FBCM 1;
BA_ "OriginatingECU" SG_ 529 helligkeitFw_FBCM "FBCM";
BA_ "SNARequired" SG_ 529 helligkeitFw_FBCM 1;
BA_ "GatewayedSignal" SG_ 529 rsErrHumSenseRls_FBCM 1;
BA_ "OriginatingECU" SG_ 529 rsErrHumSenseRls_FBCM "FBCM";
BA_ "SNARequired" SG_ 529 rsErrHumSenseRls_FBCM 1;
BA_ "GatewayedSignal" SG_ 529 humSnsIntFltRls_FBCM 1;
BA_ "OriginatingECU" SG_ 529 humSnsIntFltRls_FBCM "FBCM";
BA_ "SNARequired" SG_ 529 humSnsIntFltRls_FBCM 1;
BA_ "GatewayedSignal" SG_ 530 soSeSunInt2DReRls_FBCM 1;
BA_ "OriginatingECU" SG_ 530 soSeSunInt2DReRls_FBCM "FBCM";
BA_ "SNARequired" SG_ 530 soSeSunInt2DReRls_FBCM 1;
BA_ "GatewayedSignal" SG_ 530 soSeSunInt2DLiRls_FBCM 1;
BA_ "OriginatingECU" SG_ 530 soSeSunInt2DLiRls_FBCM "FBCM";
BA_ "SNARequired" SG_ 530 soSeSunInt2DLiRls_FBCM 1;
BA_ "GatewayedSignal" SG_ 530 glassTempRls_FBCM 1;
BA_ "OriginatingECU" SG_ 530 glassTempRls_FBCM "FBCM";
BA_ "SNARequired" SG_ 530 glassTempRls_FBCM 1;
BA_ "GatewayedSignal" SG_ 530 humidityAirTempRls_FBCM 1;
BA_ "OriginatingECU" SG_ 530 humidityAirTempRls_FBCM "FBCM";
BA_ "SNARequired" SG_ 530 humidityAirTempRls_FBCM 1;
BA_ "GatewayedSignal" SG_ 530 dewpointTempRls_FBCM 1;
BA_ "OriginatingECU" SG_ 530 dewpointTempRls_FBCM "FBCM";
BA_ "SNARequired" SG_ 530 dewpointTempRls_FBCM 1;
BA_ "GatewayedSignal" SG_ 530 relHumidityRls_FBCM 1;
BA_ "OriginatingECU" SG_ 530 relHumidityRls_FBCM "FBCM";
BA_ "SNARequired" SG_ 530 relHumidityRls_FBCM 1;
BA_ "GenSigStartValue" SG_ 14 vehicleIdNumberLo_BGW 48;
BA_ "SNARequired" SG_ 14 vehicleIdNumberLo_BGW 1;
BA_ "SNARequired" SG_ 14 vehicleIdNumberHi_BGW 1;
BA_ "GenSigStartValue" SG_ 14 vehicleIdNumberHi_BGW 48;
BA_ "SNARequired" SG_ 14 vehicleIdNumberIndex_BGW 1;
BA_ "GenSigStartValue" SG_ 14 vehicleIdNumberMid_BGW 48;
BA_ "SNARequired" SG_ 14 vehicleIdNumberMid_BGW 1;
BA_ "OriginatingECU" SG_ 15 eventsUnread_BGW "BGW";
BA_ "OriginatingECU" SG_ 15 eventNotification_BGW "BGW";
BA_ "OriginatingECU" SG_ 15 eventAssert_BGW "BGW";
BA_ "OriginatingECU" SG_ 15 dem001IhubMIAOnEthernet_BGW "BGW";
BA_ "OriginatingECU" SG_ 265 taskEthTx_BGW "BGW";
BA_ "OriginatingECU" SG_ 265 taskEthRx_BGW "BGW";
BA_ "OriginatingECU" SG_ 265 task1000Hz_BGW "BGW";
BA_ "OriginatingECU" SG_ 269 windowAbsReqRearRight_IHUB "IHUB";
BA_ "GatewayedSignal" SG_ 269 windowAbsReqRearRight_IHUB 1;
BA_ "ExpirationValue" SG_ 269 windowAbsReqRearRight_IHUB "255";
BA_ "OriginatingECU" SG_ 269 windowAbsReqRearLeft_IHUB "IHUB";
BA_ "GatewayedSignal" SG_ 269 windowAbsReqRearLeft_IHUB 1;
BA_ "ExpirationValue" SG_ 269 windowAbsReqRearLeft_IHUB "255";
BA_ "OriginatingECU" SG_ 269 windowAbsReqFrontRight_IHUB "IHUB";
BA_ "GatewayedSignal" SG_ 269 windowAbsReqFrontRight_IHUB 1;
BA_ "ExpirationValue" SG_ 269 windowAbsReqFrontRight_IHUB "255";
BA_ "OriginatingECU" SG_ 269 windowAbsReqFrontLeft_IHUB "IHUB";
BA_ "GatewayedSignal" SG_ 269 windowAbsReqFrontLeft_IHUB 1;
BA_ "ExpirationValue" SG_ 269 windowAbsReqFrontLeft_IHUB "255";
BA_ "GenSigStartValue" SG_ 269 chargePortDoorOpenReq_IHUB 2;
BA_ "OriginatingECU" SG_ 269 chargePortDoorOpenReq_IHUB "IHUB";
BA_ "GatewayedSignal" SG_ 269 chargePortDoorOpenReq_IHUB 1;
BA_ "ExpirationValue" SG_ 269 chargePortDoorOpenReq_IHUB "NoCommand";
BA_ "ExpirationValue" SG_ 269 windowReqFrontLeft_IHUB "NoCommand";
BA_ "OriginatingECU" SG_ 269 windowReqFrontLeft_IHUB "IHUB";
BA_ "GatewayedSignal" SG_ 269 windowReqFrontLeft_IHUB 1;
BA_ "ExpirationValue" SG_ 269 windowReqFrontRight_IHUB "NoCommand";
BA_ "OriginatingECU" SG_ 269 windowReqFrontRight_IHUB "IHUB";
BA_ "GatewayedSignal" SG_ 269 windowReqFrontRight_IHUB 1;
BA_ "ExpirationValue" SG_ 269 windowReqRearLeft_IHUB "NoCommand";
BA_ "OriginatingECU" SG_ 269 windowReqRearLeft_IHUB "IHUB";
BA_ "GatewayedSignal" SG_ 269 windowReqRearLeft_IHUB 1;
BA_ "ExpirationValue" SG_ 269 windowReqRearRight_IHUB "NoCommand";
BA_ "OriginatingECU" SG_ 269 windowReqRearRight_IHUB "IHUB";
BA_ "GatewayedSignal" SG_ 269 windowReqRearRight_IHUB 1;
BA_ "OriginatingECU" SG_ 269 mirrorDimmingEnableDisable_IHUB "IHUB";
BA_ "GatewayedSignal" SG_ 269 mirrorDimmingEnableDisable_IHUB 1;
BA_ "OriginatingECU" SG_ 269 lightHazardOnReq_IHUB "IHUB";
BA_ "GatewayedSignal" SG_ 269 lightHazardOnReq_IHUB 1;
BA_ "OriginatingECU" SG_ 269 hornOnReq_IHUB "IHUB";
BA_ "GatewayedSignal" SG_ 269 hornOnReq_IHUB 1;
BA_ "GenSigSendType" SG_ 714 fimPreventDrive_DCRR 1;
BA_ "GenSigSendType" SG_ 714 fimNoCurrent_DCRR 1;
BA_ "GenSigSendType" SG_ 714 eventsUnread_DCRR 1;
BA_ "GatewayedSignal" SG_ 714 eventsUnread_DCRR 1;
BA_ "OriginatingECU" SG_ 714 eventsUnread_DCRR "DCRR";
BA_ "GenSigSendType" SG_ 714 eventAssert_DCRR 1;
BA_ "GenSigSendType" SG_ 714 eventNotification_DCRR 1;
BA_ "GenSigSendType" SG_ 714 fimOverCurrent_DCRR 1;
BA_ "GenSigSendType" SG_ 682 fimPreventDrive_DCRL 1;
BA_ "GenSigSendType" SG_ 682 fimNoCurrent_DCRL 1;
BA_ "GenSigSendType" SG_ 682 eventsUnread_DCRL 1;
BA_ "GatewayedSignal" SG_ 682 eventsUnread_DCRL 1;
BA_ "OriginatingECU" SG_ 682 eventsUnread_DCRL "DCRL";
BA_ "GenSigSendType" SG_ 682 eventAssert_DCRL 1;
BA_ "GenSigSendType" SG_ 682 eventNotification_DCRL 1;
BA_ "GenSigSendType" SG_ 682 fimOverCurrent_DCRL 1;
BA_ "GenSigSendType" SG_ 650 fimPreventDrive_DCFR 1;
BA_ "GenSigSendType" SG_ 650 fimNoCurrent_DCFR 1;
BA_ "GenSigSendType" SG_ 650 eventsUnread_DCFR 1;
BA_ "GatewayedSignal" SG_ 650 eventsUnread_DCFR 1;
BA_ "OriginatingECU" SG_ 650 eventsUnread_DCFR "DCFR";
BA_ "GenSigSendType" SG_ 650 eventAssert_DCFR 1;
BA_ "GenSigSendType" SG_ 650 eventNotification_DCFR 1;
BA_ "GenSigSendType" SG_ 650 fimOverCurrent_DCFR 1;
BA_ "GenSigSendType" SG_ 610 fimPreventDrive_DCFL 1;
BA_ "GenSigSendType" SG_ 610 fimNoCurrent_DCFL 1;
BA_ "OriginatingECU" SG_ 610 eventsUnread_DCFL "DCFL";
BA_ "GatewayedSignal" SG_ 610 eventsUnread_DCFL 1;
BA_ "GenSigSendType" SG_ 610 eventsUnread_DCFL 1;
BA_ "GenSigSendType" SG_ 610 eventAssert_DCFL 1;
BA_ "GenSigSendType" SG_ 610 eventNotification_DCFL 1;
BA_ "GenSigSendType" SG_ 610 fimOverCurrent_DCFL 1;
BA_ "GatewayedSignal" SG_ 267 vehicleSpeedQual_PTC 1;
BA_ "OriginatingECU" SG_ 267 vehicleSpeedQual_PTC "PTC";
BA_ "GatewayedSignal" SG_ 267 vehicleSpeedDir_PTC 1;
BA_ "OriginatingECU" SG_ 267 vehicleSpeedDir_PTC "PTC";
BA_ "GatewayedSignal" SG_ 267 vehicleSpeed_PTC 1;
BA_ "OriginatingECU" SG_ 267 vehicleSpeed_PTC "PTC";
BA_ "SNARequired" SG_ 267 vehicleSpeedQ_ESP 1;
BA_ "OriginatingECU" SG_ 267 vehicleSpeedQ_ESP "ESP";
BA_ "GatewayedSignal" SG_ 267 vehicleSpeedQ_ESP 1;
BA_ "SNARequired" SG_ 267 vehicleSpeedCounter_ESP 1;
BA_ "OriginatingECU" SG_ 267 vehicleSpeedCounter_ESP "ESP";
BA_ "GatewayedSignal" SG_ 267 vehicleSpeedCounter_ESP 1;
BA_ "SNARequired" SG_ 267 vehicleSpeedChecksum_ESP 1;
BA_ "OriginatingECU" SG_ 267 vehicleSpeedChecksum_ESP "ESP";
BA_ "GatewayedSignal" SG_ 267 vehicleSpeedChecksum_ESP 1;
BA_ "GatewayedSignal" SG_ 267 vehicleSpeed_ESP 1;
BA_ "OriginatingECU" SG_ 267 vehicleSpeed_ESP "ESP";
BA_ "OriginatingECU" SG_ 271 wiperServiceMode_IHUB "IHUB";
BA_ "GatewayedSignal" SG_ 271 wiperServiceMode_IHUB 1;
BA_ "OriginatingECU" SG_ 271 range_IHUB "IHUB";
BA_ "GatewayedSignal" SG_ 271 range_IHUB 1;
BA_ "GatewayedSignal" SG_ 271 rsdCommandPosition_IHUB 1;
BA_ "OriginatingECU" SG_ 271 rsdCommandPosition_IHUB "IHUB";
BA_ "OriginatingECU" SG_ 271 nightModeSelect_IHUB "IHUB";
BA_ "ExpirationValue" SG_ 271 rearDisplayUpDownReq_IHUB "NoAction";
BA_ "GatewayedSignal" SG_ 271 rearDisplayUpDownReq_IHUB 1;
BA_ "OriginatingECU" SG_ 271 rearDisplayUpDownReq_IHUB "IHUB";
BA_ "OriginatingECU" SG_ 271 panelSelectForBrightness_IHUB "IHUB";
BA_ "GatewayedSignal" SG_ 271 panelSelectForBrightness_IHUB 1;
BA_ "OriginatingECU" SG_ 271 panelBrightness_IHUB "IHUB";
BA_ "GatewayedSignal" SG_ 271 panelBrightness_IHUB 1;
BA_ "ExpirationValue" SG_ 271 alarmModeHazard_IHUB "SNA";
BA_ "GatewayedSignal" SG_ 271 alarmModeHazard_IHUB 1;
BA_ "OriginatingECU" SG_ 271 alarmModeHazard_IHUB "IHUB";
BA_ "ExpirationValue" SG_ 271 alarmModeHorn_IHUB "SNA";
BA_ "GatewayedSignal" SG_ 271 alarmModeHorn_IHUB 1;
BA_ "OriginatingECU" SG_ 271 alarmModeHorn_IHUB "IHUB";
BA_ "GenSigSendType" SG_ 520 seatBackCmdFR_BGW 1;
BA_ "GenSigSendType" SG_ 520 seatBackCmdFL_BGW 1;
BA_ "GenSigSendType" SG_ 520 seatCushionBolsterCmdFR_BGW 1;
BA_ "GenSigSendType" SG_ 520 seatCushionTiltCmdFR_BGW 1;
BA_ "GenSigSendType" SG_ 520 seatBackBolsterCmdFR_BGW 1;
BA_ "GenSigSendType" SG_ 520 seatBackLumbarCmdFL_BGW 1;
BA_ "GenSigSendType" SG_ 520 seatCushionTiltCmdFL_BGW 1;
BA_ "GenSigSendType" SG_ 520 seatTrackCmdFR_BGW 1;
BA_ "GenSigSendType" SG_ 520 seatLiftCmdFR_BGW 1;
BA_ "GenSigSendType" SG_ 520 seatBackLumbarCmdFR_BGW 1;
BA_ "GenSigSendType" SG_ 520 seatTrackCmdFL_BGW 1;
BA_ "GenSigSendType" SG_ 520 seatLiftCmdFL_BGW 1;
BA_ "GenSigSendType" SG_ 520 seatCushionBolsterCmdFL_BGW 1;
BA_ "GenSigSendType" SG_ 520 seatBackBolsterCmdFL_BGW 1;
BA_ "OriginatingECU" SG_ 526 lightLaneChangeRightOnReq_SDCM "SDCM";
BA_ "OriginatingECU" SG_ 526 lightLaneChangeLeftOnReq_SDCM "SDCM";
BA_ "OriginatingECU" SG_ 526 mirrorDimmingLvlReq_SDCM "SDCM";
BA_ "OriginatingECU" SG_ 526 lightTurnLeftOnReq_SDCM "SDCM";
BA_ "OriginatingECU" SG_ 526 lightTurnRightOnReq_SDCM "SDCM";
BA_ "OriginatingECU" SG_ 608 lockUnlockReq_FLLUS "FLLUS";
BA_ "OriginatingECU" SG_ 608 doorLatchFault_DCFL "DCFL";
BA_ "GatewayedSignal" SG_ 608 doorLatchFault_DCFL 1;
BA_ "OriginatingECU" SG_ 608 childLockButtonState_DCFL "DCFL";
BA_ "GatewayedSignal" SG_ 608 childLockButtonState_DCFL 1;
BA_ "OriginatingECU" SG_ 608 doorIsUnlatched_DCFL "DCFL";
BA_ "GatewayedSignal" SG_ 608 doorIsUnlatched_DCFL 1;
BA_ "GatewayedSignal" SG_ 608 doorState_DCFL 1;
BA_ "OriginatingECU" SG_ 608 doorState_DCFL "DCFL";
BA_ "OriginatingECU" SG_ 608 windowStatusFl_DCFL "DCFL";
BA_ "GatewayedSignal" SG_ 608 windowStatusFl_DCFL 1;
BA_ "OriginatingECU" SG_ 608 mirrorFoldFeedbackLeft_DCFL "DCFL";
BA_ "GatewayedSignal" SG_ 608 mirrorFoldFeedbackLeft_DCFL 1;
BA_ "OriginatingECU" SG_ 608 mirrorDefrostGlassStatusLh_DCFL "DCFL";
BA_ "GatewayedSignal" SG_ 608 mirrorDefrostGlassStatusLh_DCFL 1;
BA_ "OriginatingECU" SG_ 608 mirrorStatusMovUpDownLeft_DCFL "DCFL";
BA_ "GatewayedSignal" SG_ 608 mirrorStatusMovUpDownLeft_DCFL 1;
BA_ "OriginatingECU" SG_ 608 mirrorStatusMovInOutLeft_DCFL "DCFL";
BA_ "GatewayedSignal" SG_ 608 mirrorStatusMovInOutLeft_DCFL 1;
BA_ "OriginatingECU" SG_ 608 mirrorDefrostCamStatusLeft_DCFL "DCFL";
BA_ "GatewayedSignal" SG_ 608 mirrorDefrostCamStatusLeft_DCFL 1;
BA_ "OriginatingECU" SG_ 608 mirrorFoldAutoStatusLeft_DCFL "DCFL";
BA_ "GatewayedSignal" SG_ 608 mirrorFoldAutoStatusLeft_DCFL 1;
BA_ "OriginatingECU" SG_ 608 mirrorDimEnabDisableStatus_DCFL "DCFL";
BA_ "GatewayedSignal" SG_ 608 mirrorDimEnabDisableStatus_DCFL 1;
BA_ "OriginatingECU" SG_ 608 errorAMPFL_DCFL "DCFL";
BA_ "GatewayedSignal" SG_ 608 errorAMPFL_DCFL 1;
BA_ "OriginatingECU" SG_ 608 errorALDFL_DCFL "DCFL";
BA_ "GatewayedSignal" SG_ 608 errorALDFL_DCFL 1;
BA_ "GenSigStartValue" SG_ 608 doorAngle_DCFL -20;
BA_ "OriginatingECU" SG_ 608 doorAngle_DCFL "DCFL";
BA_ "GatewayedSignal" SG_ 608 doorAngle_DCFL 1;
BA_ "OriginatingECU" SG_ 608 doorAngleMax_DCFL "DCFL";
BA_ "GatewayedSignal" SG_ 608 doorAngleMax_DCFL 1;
BA_ "OriginatingECU" SG_ 609 windowReqAll_DCFL "DCFL";
BA_ "GenSigSendType" SG_ 609 windowReqAll_DCFL 1;
BA_ "GenSigSendType" SG_ 609 windowLock_DCFL 1;
BA_ "SNARequired" SG_ 609 windowLock_DCFL 1;
BA_ "GenSigSendType" SG_ 609 allDoorsLock_DCFL 1;
BA_ "SNARequired" SG_ 609 allDoorsLock_DCFL 1;
BA_ "GenSigSendType" SG_ 609 allDoorsUnlock_DCFL 1;
BA_ "SNARequired" SG_ 609 allDoorsUnlock_DCFL 1;
BA_ "GenSigSendType" SG_ 609 windowReqRearLeft_DCFL 1;
BA_ "GenSigSendType" SG_ 609 windowReqRearRight_DCFL 1;
BA_ "GenSigSendType" SG_ 609 nothingPressed_DCFL 1;
BA_ "SNARequired" SG_ 609 nothingPressed_DCFL 1;
BA_ "GenSigSendType" SG_ 609 buttonPressed_DCFL 1;
BA_ "GenSigSendType" SG_ 609 windowReqFrontLeft_DCFL 1;
BA_ "GatewayedSignal" SG_ 609 windowReqFrontLeft_DCFL 1;
BA_ "OriginatingECU" SG_ 609 windowReqFrontLeft_DCFL "DCFL";
BA_ "GenSigSendType" SG_ 609 windowReqFrontRight_DCFL 1;
BA_ "SNARequired" SG_ 609 windowReqFrontRight_DCFL 1;
BA_ "GenSigSendType" SG_ 609 mirrorUp_DCFL 1;
BA_ "SNARequired" SG_ 609 mirrorUp_DCFL 1;
BA_ "GenSigSendType" SG_ 609 doorMirrorFoldCmd_DCFL 1;
BA_ "GenSigSendType" SG_ 609 doorExtDriverRearRelease_DCFL 1;
BA_ "GenSigSendType" SG_ 609 doorIntDriverRearRelease_DCFL 1;
BA_ "GenSigSendType" SG_ 609 doorDriverFrontPresentReq_DCFL 1;
BA_ "OriginatingECU" SG_ 611 windowPositionFL_DCFL "DCFL";
BA_ "GatewayedSignal" SG_ 611 windowPositionFL_DCFL 1;
BA_ "OriginatingECU" SG_ 611 autoDoorLockStatus_DCFL "DCFL";
BA_ "GatewayedSignal" SG_ 611 autoDoorLockStatus_DCFL 1;
BA_ "OriginatingECU" SG_ 611 autoMirrorTiltStatus_DCFL "DCFL";
BA_ "GatewayedSignal" SG_ 611 autoMirrorTiltStatus_DCFL 1;
BA_ "GatewayedSignal" SG_ 611 mirrorStatusPosUpDownLh_DCFL 1;
BA_ "OriginatingECU" SG_ 611 mirrorStatusPosUpDownLh_DCFL "DCFL";
BA_ "GatewayedSignal" SG_ 611 mirrorStatusPosInOutLh_DCFL 1;
BA_ "OriginatingECU" SG_ 611 mirrorStatusPosInOutLh_DCFL "DCFL";
BA_ "SNARequired" SG_ 264 steeringAbsTelePos_IHUB 1;
BA_ "OriginatingECU" SG_ 264 steeringAbsTelePos_IHUB "IHUB";
BA_ "GatewayedSignal" SG_ 264 steeringAbsTelePos_IHUB 1;
BA_ "SNARequired" SG_ 264 steeringAbsTiltPos_IHUB 1;
BA_ "OriginatingECU" SG_ 264 steeringAbsTiltPos_IHUB "IHUB";
BA_ "GatewayedSignal" SG_ 264 steeringAbsTiltPos_IHUB 1;
BA_ "GatewayedSignal" SG_ 264 mirrorTiltAbsInOutLeft_IHUB 1;
BA_ "OriginatingECU" SG_ 264 mirrorTiltAbsInOutLeft_IHUB "IHUB";
BA_ "GatewayedSignal" SG_ 264 mirrorTiltAbsUpDownLeft_IHUB 1;
BA_ "OriginatingECU" SG_ 264 mirrorTiltAbsUpDownLeft_IHUB "IHUB";
BA_ "GatewayedSignal" SG_ 264 mirrorTiltAbsInOutRight_IHUB 1;
BA_ "OriginatingECU" SG_ 264 mirrorTiltAbsInOutRight_IHUB "IHUB";
BA_ "GatewayedSignal" SG_ 264 mirrorTiltAbsUpDownRight_IHUB 1;
BA_ "OriginatingECU" SG_ 264 mirrorTiltAbsUpDownRight_IHUB "IHUB";
BA_ "GatewayedSignal" SG_ 624 seatBackBolsterPositionFL_DSM 1;
BA_ "OriginatingECU" SG_ 624 seatBackBolsterPositionFL_DSM "DSM";
BA_ "GatewayedSignal" SG_ 624 seatCushionBolsterPositionFL_DSM 1;
BA_ "OriginatingECU" SG_ 624 seatCushionBolsterPositionFL_DSM "DSM";
BA_ "GatewayedSignal" SG_ 624 seatCushionTiltPositionFL_DSM 1;
BA_ "OriginatingECU" SG_ 624 seatCushionTiltPositionFL_DSM "DSM";
BA_ "GatewayedSignal" SG_ 624 seatTrackPositionFL_DSM 1;
BA_ "OriginatingECU" SG_ 624 seatTrackPositionFL_DSM "DSM";
BA_ "GatewayedSignal" SG_ 624 seatBackPositionFL_DSM 1;
BA_ "OriginatingECU" SG_ 624 seatBackPositionFL_DSM "DSM";
BA_ "GatewayedSignal" SG_ 624 seatLiftPositionFL_DSM 1;
BA_ "OriginatingECU" SG_ 624 seatLiftPositionFL_DSM "DSM";
BA_ "GatewayedSignal" SG_ 628 seatMsgIntensityStatusFL_DSM 1;
BA_ "OriginatingECU" SG_ 628 seatMsgIntensityStatusFL_DSM "DSM";
BA_ "GatewayedSignal" SG_ 628 seatHeatVentStatusFL_DSM 1;
BA_ "OriginatingECU" SG_ 628 seatHeatVentStatusFL_DSM "DSM";
BA_ "GatewayedSignal" SG_ 628 seatCushionMassageStatusFL_DSM 1;
BA_ "OriginatingECU" SG_ 628 seatCushionMassageStatusFL_DSM "DSM";
BA_ "GatewayedSignal" SG_ 628 seatBackMassageStatusFL_DSM 1;
BA_ "OriginatingECU" SG_ 628 seatBackMassageStatusFL_DSM "DSM";
BA_ "GatewayedSignal" SG_ 628 seatMassageTypeStatusFL_DSM 1;
BA_ "OriginatingECU" SG_ 628 seatMassageTypeStatusFL_DSM "DSM";
BA_ "GatewayedSignal" SG_ 628 seatFrontLeftOccupied_DSM 1;
BA_ "OriginatingECU" SG_ 628 seatFrontLeftOccupied_DSM "DSM";
BA_ "GenSigSNA" SG_ 628 seatInitStatus_DSM "3";
BA_ "GenSigSNA" SG_ 628 seatVBatPowerStatus_DSM "3";
BA_ "GenSigSNA" SG_ 628 seatVBatEleStatus_DSM "3";
BA_ "GenSigSNA" SG_ 628 seatFaultStatus_DSM "3";
BA_ "GenSigSNA" SG_ 628 seatAntiPanicStatus_DSM "3";
BA_ "OriginatingECU" SG_ 648 lockUnlockReq_FRLUS "FRLUS";
BA_ "OriginatingECU" SG_ 648 doorLatchFault_DCFR "DCFR";
BA_ "GatewayedSignal" SG_ 648 doorLatchFault_DCFR 1;
BA_ "OriginatingECU" SG_ 648 childLockButtonState_DCFR "DCFR";
BA_ "GatewayedSignal" SG_ 648 childLockButtonState_DCFR 1;
BA_ "OriginatingECU" SG_ 648 doorIsUnlatched_DCFR "DCFR";
BA_ "GatewayedSignal" SG_ 648 doorIsUnlatched_DCFR 1;
BA_ "OriginatingECU" SG_ 648 doorExtSwitch_DCFR "DCFR";
BA_ "GatewayedSignal" SG_ 648 doorExtSwitch_DCFR 1;
BA_ "OriginatingECU" SG_ 648 doorMirrorState_DCFR "DCFR";
BA_ "GatewayedSignal" SG_ 648 doorMirrorState_DCFR 1;
BA_ "GatewayedSignal" SG_ 648 doorState_DCFR 1;
BA_ "OriginatingECU" SG_ 648 doorState_DCFR "DCFR";
BA_ "OriginatingECU" SG_ 648 mirrorHeaterState_DCFR "DCFR";
BA_ "GatewayedSignal" SG_ 648 mirrorHeaterState_DCFR 1;
BA_ "OriginatingECU" SG_ 648 sideRepeaterState_DCFR "DCFR";
BA_ "GatewayedSignal" SG_ 648 sideRepeaterState_DCFR 1;
BA_ "OriginatingECU" SG_ 648 doorDTCPresent_DCFR "DCFR";
BA_ "GatewayedSignal" SG_ 648 doorDTCPresent_DCFR 1;
BA_ "OriginatingECU" SG_ 648 windowStatusFr_DCFR "DCFR";
BA_ "GatewayedSignal" SG_ 648 windowStatusFr_DCFR 1;
BA_ "OriginatingECU" SG_ 648 mirrorFoldFeedbackRight_DCFR "DCFR";
BA_ "GatewayedSignal" SG_ 648 mirrorFoldFeedbackRight_DCFR 1;
BA_ "OriginatingECU" SG_ 648 mirrorDefrostGlassStatusRh_DCFR "DCFR";
BA_ "GatewayedSignal" SG_ 648 mirrorDefrostGlassStatusRh_DCFR 1;
BA_ "OriginatingECU" SG_ 648 mirrorStatusMovUpDownRight_DCFR "DCFR";
BA_ "GatewayedSignal" SG_ 648 mirrorStatusMovUpDownRight_DCFR 1;
BA_ "OriginatingECU" SG_ 648 mirrorStatusMovInOutRight_DCFR "DCFR";
BA_ "GatewayedSignal" SG_ 648 mirrorStatusMovInOutRight_DCFR 1;
BA_ "OriginatingECU" SG_ 648 mirrorDefrostCamStatusRight_DCFR "DCFR";
BA_ "GatewayedSignal" SG_ 648 mirrorDefrostCamStatusRight_DCFR 1;
BA_ "OriginatingECU" SG_ 648 mirrorFoldAutoStatusRight_DCFR "DCFR";
BA_ "GatewayedSignal" SG_ 648 mirrorFoldAutoStatusRight_DCFR 1;
BA_ "OriginatingECU" SG_ 648 mirrorDimEnabDisableStatus_DCFR "DCFR";
BA_ "GatewayedSignal" SG_ 648 mirrorDimEnabDisableStatus_DCFR 1;
BA_ "OriginatingECU" SG_ 648 errorAMPFR_DCFR "DCFR";
BA_ "GatewayedSignal" SG_ 648 errorAMPFR_DCFR 1;
BA_ "OriginatingECU" SG_ 648 errorALDFR_DCFR "DCFR";
BA_ "GatewayedSignal" SG_ 648 errorALDFR_DCFR 1;
BA_ "GenSigStartValue" SG_ 648 doorAngle_DCFR -20;
BA_ "OriginatingECU" SG_ 648 doorAngle_DCFR "DCFR";
BA_ "GatewayedSignal" SG_ 648 doorAngle_DCFR 1;
BA_ "OriginatingECU" SG_ 648 doorAngleMax_DCFR "DCFR";
BA_ "GatewayedSignal" SG_ 648 doorAngleMax_DCFR 1;
BA_ "OriginatingECU" SG_ 649 windowReqAll_DCFR "DCFR";
BA_ "GenSigSendType" SG_ 649 windowReqAll_DCFR 1;
BA_ "SNARequired" SG_ 649 windowLock_DCFR 1;
BA_ "GenSigSendType" SG_ 649 windowLock_DCFR 1;
BA_ "SNARequired" SG_ 649 allDoorsLock_DCFR 1;
BA_ "GenSigSendType" SG_ 649 allDoorsLock_DCFR 1;
BA_ "SNARequired" SG_ 649 allDoorsUnlock_DCFR 1;
BA_ "GenSigSendType" SG_ 649 allDoorsUnlock_DCFR 1;
BA_ "GenSigSendType" SG_ 649 windowReqRearLeft_DCFR 1;
BA_ "GenSigSendType" SG_ 649 windowReqRearRight_DCFR 1;
BA_ "SNARequired" SG_ 649 nothingPressed_DCFR 1;
BA_ "GenSigSendType" SG_ 649 nothingPressed_DCFR 1;
BA_ "SNARequired" SG_ 649 buttonPressed_DCFR 1;
BA_ "GenSigSendType" SG_ 649 buttonPressed_DCFR 1;
BA_ "GenSigSendType" SG_ 649 windowReqFrontLeft_DCFR 1;
BA_ "OriginatingECU" SG_ 649 windowReqFrontLeft_DCFR "DCFR";
BA_ "GenSigSendType" SG_ 649 windowReqFrontRight_DCFR 1;
BA_ "GatewayedSignal" SG_ 649 windowReqFrontRight_DCFR 1;
BA_ "OriginatingECU" SG_ 649 windowReqFrontRight_DCFR "DCFR";
BA_ "SNARequired" SG_ 649 mirrorUp_DCFR 1;
BA_ "GenSigSendType" SG_ 649 mirrorUp_DCFR 1;
BA_ "GenSigSendType" SG_ 649 extPassRearRelease_DCFR 1;
BA_ "GenSigSendType" SG_ 649 intPassRearRelease_DCFR 1;
BA_ "GenSigSendType" SG_ 649 frontRightPresentReq_DCFR 1;
BA_ "GenSigSendType" SG_ 649 rearRightPresentReq_DCFR 1;
BA_ "OriginatingECU" SG_ 651 windowPositionFR_DCFR "DCFR";
BA_ "GatewayedSignal" SG_ 651 windowPositionFR_DCFR 1;
BA_ "OriginatingECU" SG_ 651 autoDoorLockStatus_DCFR "DCFR";
BA_ "GatewayedSignal" SG_ 651 autoDoorLockStatus_DCFR 1;
BA_ "OriginatingECU" SG_ 651 autoMirrorTiltStatus_DCFR "DCFR";
BA_ "GatewayedSignal" SG_ 651 autoMirrorTiltStatus_DCFR 1;
BA_ "GatewayedSignal" SG_ 651 mirrorStatusPosUpDownRh_DCFR 1;
BA_ "OriginatingECU" SG_ 651 mirrorStatusPosUpDownRh_DCFR "DCFR";
BA_ "GatewayedSignal" SG_ 651 mirrorStatusPosInOutRh_DCFR 1;
BA_ "OriginatingECU" SG_ 651 mirrorStatusPosInOutRh_DCFR "DCFR";
BA_ "GatewayedSignal" SG_ 656 seatBackBolsterPositionFR_PSM 1;
BA_ "OriginatingECU" SG_ 656 seatBackBolsterPositionFR_PSM "PSM";
BA_ "GatewayedSignal" SG_ 656 seatCushionBolsterPositionFR_PSM 1;
BA_ "OriginatingECU" SG_ 656 seatCushionBolsterPositionFR_PSM "PSM";
BA_ "GatewayedSignal" SG_ 656 seatCushionTiltPositionFR_PSM 1;
BA_ "OriginatingECU" SG_ 656 seatCushionTiltPositionFR_PSM "PSM";
BA_ "GatewayedSignal" SG_ 656 seatTrackPositionFR_PSM 1;
BA_ "OriginatingECU" SG_ 656 seatTrackPositionFR_PSM "PSM";
BA_ "GatewayedSignal" SG_ 656 seatBackPositionFR_PSM 1;
BA_ "OriginatingECU" SG_ 656 seatBackPositionFR_PSM "PSM";
BA_ "GatewayedSignal" SG_ 656 seatLiftPositionFR_PSM 1;
BA_ "OriginatingECU" SG_ 656 seatLiftPositionFR_PSM "PSM";
BA_ "OriginatingECU" SG_ 660 seatHeatVentStatusFR_PSM "PSM";
BA_ "GatewayedSignal" SG_ 660 seatHeatVentStatusFR_PSM 1;
BA_ "GatewayedSignal" SG_ 660 seatCushionMassageStatusFR_PSM 1;
BA_ "OriginatingECU" SG_ 660 seatCushionMassageStatusFR_PSM "PSM";
BA_ "GatewayedSignal" SG_ 660 seatBackMassageStatusFR_PSM 1;
BA_ "OriginatingECU" SG_ 660 seatBackMassageStatusFR_PSM "PSM";
BA_ "GatewayedSignal" SG_ 660 seatMsgIntensityStatusFR_PSM 1;
BA_ "OriginatingECU" SG_ 660 seatMsgIntensityStatusFR_PSM "PSM";
BA_ "GatewayedSignal" SG_ 660 seatMassageTypeStatusFR_PSM 1;
BA_ "OriginatingECU" SG_ 660 seatMassageTypeStatusFR_PSM "PSM";
BA_ "GatewayedSignal" SG_ 660 seatFrontRightOccupied_PSM 1;
BA_ "OriginatingECU" SG_ 660 seatFrontRightOccupied_PSM "PSM";
BA_ "GenSigSNA" SG_ 660 seatInitStatus_PSM "3";
BA_ "GenSigSNA" SG_ 660 seatVBatPowerStatus_PSM "3";
BA_ "GenSigSNA" SG_ 660 seatVBatEleStatus_PSM "3";
BA_ "GenSigSNA" SG_ 660 seatFaultStatus_PSM "3";
BA_ "GenSigSNA" SG_ 660 seatAntiPanicStatus_PSM "3";
BA_ "GatewayedSignal" SG_ 688 seatCushionTiltPositionRL_RLSM 1;
BA_ "OriginatingECU" SG_ 688 seatCushionTiltPositionRL_RLSM "RLSM";
BA_ "OriginatingECU" SG_ 688 seatShoulderBlstrPositionRL_RLSM "RLSM";
BA_ "GatewayedSignal" SG_ 688 seatShoulderBlstrPositionRL_RLSM 1;
BA_ "GatewayedSignal" SG_ 688 seatBackPositionRL_RLSM 1;
BA_ "OriginatingECU" SG_ 688 seatBackPositionRL_RLSM "RLSM";
BA_ "GatewayedSignal" SG_ 688 seatLegExtPositionRL_RLSM 1;
BA_ "OriginatingECU" SG_ 688 seatLegExtPositionRL_RLSM "RLSM";
BA_ "GatewayedSignal" SG_ 688 seatLegSwivelPositionRL_RLSM 1;
BA_ "OriginatingECU" SG_ 688 seatLegSwivelPositionRL_RLSM "RLSM";
BA_ "GatewayedSignal" SG_ 692 seatHeatVentStatusRL_RLSM 1;
BA_ "OriginatingECU" SG_ 692 seatHeatVentStatusRL_RLSM "RLSM";
BA_ "GatewayedSignal" SG_ 692 seatCushionMassageStatusRL_RLSM 1;
BA_ "OriginatingECU" SG_ 692 seatCushionMassageStatusRL_RLSM "RLSM";
BA_ "GatewayedSignal" SG_ 692 seatBackMassageStatusRL_RLSM 1;
BA_ "OriginatingECU" SG_ 692 seatBackMassageStatusRL_RLSM "RLSM";
BA_ "GatewayedSignal" SG_ 692 seatMsgIntensityStatusRL_RLSM 1;
BA_ "OriginatingECU" SG_ 692 seatMsgIntensityStatusRL_RLSM "RLSM";
BA_ "GatewayedSignal" SG_ 692 seatMassageTypeStatusRL_RLSM 1;
BA_ "OriginatingECU" SG_ 692 seatMassageTypeStatusRL_RLSM "RLSM";
BA_ "GatewayedSignal" SG_ 692 seatRearLeftOccupied_RLSM 1;
BA_ "OriginatingECU" SG_ 692 seatRearLeftOccupied_RLSM "RLSM";
BA_ "GenSigSNA" SG_ 692 seatInitStatus_RLSM "3";
BA_ "GenSigSNA" SG_ 692 seatVBatPowerStatus_RLSM "3";
BA_ "GenSigSNA" SG_ 692 seatVBatEleStatus_RLSM "3";
BA_ "GenSigSNA" SG_ 692 seatFaultStatus_RLSM "3";
BA_ "GenSigSNA" SG_ 692 seatAntiPanicStatus_RLSM "3";
BA_ "GatewayedSignal" SG_ 720 seatCushionTiltPositionRR_RRSM 1;
BA_ "OriginatingECU" SG_ 720 seatCushionTiltPositionRR_RRSM "RRSM";
BA_ "OriginatingECU" SG_ 720 seatShoulderBlstrPositionRR_RRSM "RRSM";
BA_ "GatewayedSignal" SG_ 720 seatShoulderBlstrPositionRR_RRSM 1;
BA_ "GatewayedSignal" SG_ 720 seatLegExtPositionRR_RRSM 1;
BA_ "OriginatingECU" SG_ 720 seatLegExtPositionRR_RRSM "RRSM";
BA_ "GatewayedSignal" SG_ 720 seatBackPositionRR_RRSM 1;
BA_ "OriginatingECU" SG_ 720 seatBackPositionRR_RRSM "RRSM";
BA_ "GatewayedSignal" SG_ 720 seatLegSwivelPositionRR_RRSM 1;
BA_ "OriginatingECU" SG_ 720 seatLegSwivelPositionRR_RRSM "RRSM";
BA_ "GatewayedSignal" SG_ 724 seatHeatVentStatusRR_RRSM 1;
BA_ "OriginatingECU" SG_ 724 seatHeatVentStatusRR_RRSM "RRSM";
BA_ "GatewayedSignal" SG_ 724 seatCushionMassageStatusRR_RRSM 1;
BA_ "OriginatingECU" SG_ 724 seatCushionMassageStatusRR_RRSM "RRSM";
BA_ "GatewayedSignal" SG_ 724 seatBackMassageStatusRR_RRSM 1;
BA_ "OriginatingECU" SG_ 724 seatBackMassageStatusRR_RRSM "RRSM";
BA_ "GatewayedSignal" SG_ 724 seatMsgIntensityStatusRR_RRSM 1;
BA_ "OriginatingECU" SG_ 724 seatMsgIntensityStatusRR_RRSM "RRSM";
BA_ "GatewayedSignal" SG_ 724 seatMassageTypeStatusRR_RRSM 1;
BA_ "OriginatingECU" SG_ 724 seatMassageTypeStatusRR_RRSM "RRSM";
BA_ "GatewayedSignal" SG_ 724 seatRearRightOccupied_RRSM 1;
BA_ "OriginatingECU" SG_ 724 seatRearRightOccupied_RRSM "RRSM";
BA_ "GenSigSNA" SG_ 724 seatInitStatus_RRSM "3";
BA_ "GenSigSNA" SG_ 724 seatVBatPowerStatus_RRSM "3";
BA_ "GenSigSNA" SG_ 724 seatVBatEleStatus_RRSM "3";
BA_ "GenSigSNA" SG_ 724 seatFaultStatus_RRSM "3";
BA_ "GenSigSNA" SG_ 724 seatAntiPanicStatus_RRSM "3";
BA_ "OriginatingECU" SG_ 779 sequenceId_BGW "BGW";
BA_ "GenSigSendType" SG_ 779 sequenceId_BGW 1;
BA_ "GenSigSendType" SG_ 781 seatCushionBolsterAbsPosDSM_BGW 1;
BA_ "GenSigSendType" SG_ 781 seatBackBolsterAbsPosDSM_BGW 1;
BA_ "GenSigSendType" SG_ 781 seatCushionAbsTiltPosDSM_BGW 1;
BA_ "GenSigSendType" SG_ 781 seatBackAbsPosDSM_BGW 1;
BA_ "GenSigSendType" SG_ 781 seatTrackAbsPosDSM_BGW 1;
BA_ "GenSigSendType" SG_ 781 seatLiftAbsPosDSM_BGW 1;
BA_ "GenSigSendType" SG_ 783 seatShoulderBlstrAbsPosRLSM_BGW 1;
BA_ "GenSigSendType" SG_ 783 seatCushionAbsTiltPosRLSM_BGW 1;
BA_ "GenSigSendType" SG_ 783 seatBackAbsPosRLSM_BGW 1;
BA_ "GenSigSendType" SG_ 783 seatLegExtAbsPosRLSM_BGW 1;
BA_ "GenSigSendType" SG_ 783 seatLegSwivelAbsPosRLSM_BGW 1;
BA_ "ExpirationValue" SG_ 1033 mirrorDefrostCameraOnReq_IHUB "SNA";
BA_ "GatewayedSignal" SG_ 1033 mirrorDefrostCameraOnReq_IHUB 1;
BA_ "OriginatingECU" SG_ 1033 mirrorDefrostCameraOnReq_IHUB "IHUB";
BA_ "ExpirationValue" SG_ 1033 mirrorDimReq_IHUB "SNA";
BA_ "GatewayedSignal" SG_ 1033 mirrorDimReq_IHUB 1;
BA_ "OriginatingECU" SG_ 1033 mirrorDimReq_IHUB "IHUB";
BA_ "ExpirationValue" SG_ 1033 mirrorFoldInOutReq_IHUB "NoCommand";
BA_ "GatewayedSignal" SG_ 1033 mirrorFoldInOutReq_IHUB 1;
BA_ "OriginatingECU" SG_ 1033 mirrorFoldInOutReq_IHUB "IHUB";
BA_ "ExpirationValue" SG_ 1033 defrostMirrorGlassReq_IHUB "SNA";
BA_ "GatewayedSignal" SG_ 1033 defrostMirrorGlassReq_IHUB 1;
BA_ "OriginatingECU" SG_ 1033 defrostMirrorGlassReq_IHUB "IHUB";
BA_ "OriginatingECU" SG_ 1033 exteriorLightReq_IHUB "IHUB";
BA_ "GatewayedSignal" SG_ 1033 exteriorLightReq_IHUB 1;
BA_ "ExpirationValue" SG_ 1033 frunkLockReq_IHUB "NoChange";
BA_ "GatewayedSignal" SG_ 1033 frunkLockReq_IHUB 1;
BA_ "OriginatingECU" SG_ 1033 frunkLockReq_IHUB "IHUB";
BA_ "ExpirationValue" SG_ 1033 liftgateLockReq_IHUB "NoChange";
BA_ "GatewayedSignal" SG_ 1033 liftgateLockReq_IHUB 1;
BA_ "OriginatingECU" SG_ 1033 liftgateLockReq_IHUB "IHUB";
BA_ "ExpirationValue" SG_ 1033 doorRRLockReq_IHUB "NoChange";
BA_ "GatewayedSignal" SG_ 1033 doorRRLockReq_IHUB 1;
BA_ "OriginatingECU" SG_ 1033 doorRRLockReq_IHUB "IHUB";
BA_ "ExpirationValue" SG_ 1033 doorRLLockReq_IHUB "NoChange";
BA_ "GatewayedSignal" SG_ 1033 doorRLLockReq_IHUB 1;
BA_ "OriginatingECU" SG_ 1033 doorRLLockReq_IHUB "IHUB";
BA_ "ExpirationValue" SG_ 1033 doorFRLockReq_IHUB "NoChange";
BA_ "GatewayedSignal" SG_ 1033 doorFRLockReq_IHUB 1;
BA_ "OriginatingECU" SG_ 1033 doorFRLockReq_IHUB "IHUB";
BA_ "ExpirationValue" SG_ 1033 doorFLLockReq_IHUB "NoChange";
BA_ "GatewayedSignal" SG_ 1033 doorFLLockReq_IHUB 1;
BA_ "OriginatingECU" SG_ 1033 doorFLLockReq_IHUB "IHUB";
BA_ "ExpirationValue" SG_ 1033 doorRearRightOperation_IHUB "NoAction";
BA_ "GatewayedSignal" SG_ 1033 doorRearRightOperation_IHUB 1;
BA_ "OriginatingECU" SG_ 1033 doorRearRightOperation_IHUB "IHUB";
BA_ "ExpirationValue" SG_ 1033 doorRearLeftOperation_IHUB "NoAction";
BA_ "GatewayedSignal" SG_ 1033 doorRearLeftOperation_IHUB 1;
BA_ "OriginatingECU" SG_ 1033 doorRearLeftOperation_IHUB "IHUB";
BA_ "ExpirationValue" SG_ 1033 doorFrontRightOperation_IHUB "NoAction";
BA_ "GatewayedSignal" SG_ 1033 doorFrontRightOperation_IHUB 1;
BA_ "OriginatingECU" SG_ 1033 doorFrontRightOperation_IHUB "IHUB";
BA_ "ExpirationValue" SG_ 1033 doorFrontLeftOperation_IHUB "NoAction";
BA_ "GatewayedSignal" SG_ 1033 doorFrontLeftOperation_IHUB 1;
BA_ "OriginatingECU" SG_ 1033 doorFrontLeftOperation_IHUB "IHUB";
BA_ "GatewayedSignal" SG_ 1033 lightLowBeamOnReq_IHUB 1;
BA_ "OriginatingECU" SG_ 1033 lightLowBeamOnReq_IHUB "IHUB";
BA_ "ExpirationValue" SG_ 1033 frontHoodOpen_IHUB "NoAction";
BA_ "SNARequired" SG_ 1033 frontHoodOpen_IHUB 1;
BA_ "GatewayedSignal" SG_ 1033 frontHoodOpen_IHUB 1;
BA_ "OriginatingECU" SG_ 1033 frontHoodOpen_IHUB "IHUB";
BA_ "GatewayedSignal" SG_ 1033 fogSwitchRear_IHUB 1;
BA_ "OriginatingECU" SG_ 1033 fogSwitchRear_IHUB "IHUB";
BA_ "GatewayedSignal" SG_ 1033 fogSwitchFront_IHUB 1;
BA_ "OriginatingECU" SG_ 1033 fogSwitchFront_IHUB "IHUB";
BA_ "GatewayedSignal" SG_ 1033 steeringHeatEnabled_IHUB 1;
BA_ "ExpirationValue" SG_ 1033 steeringHeatEnabled_IHUB "SNA";
BA_ "OriginatingECU" SG_ 1033 steeringHeatEnabled_IHUB "IHUB";
BA_ "GenSigSendType" SG_ 1037 honkThreeTimes_BGW 1;
BA_ "GenSigSendType" SG_ 1037 flashLights_BGW 1;
BA_ "GenSigSendType" SG_ 1037 lightLowBeamOnReq_BGW 1;
BA_ "GenSigSendType" SG_ 1037 lightDomeOnReq_BGW 1;
BA_ "GenSigSendType" SG_ 1037 lightHighBeamOnReq_BGW 1;
BA_ "OriginatingECU" SG_ 1038 mirrorMoveAbsUpDownRight_BGW "BGW";
BA_ "OriginatingECU" SG_ 1038 mirrorMoveAbsUpDownLeft_BGW "BGW";
BA_ "OriginatingECU" SG_ 1038 mirrorMoveAbsInOutRight_BGW "BGW";
BA_ "OriginatingECU" SG_ 1038 mirrorMoveAbsInOutLeft_BGW "BGW";
BA_ "OriginatingECU" SG_ 1039 chargeStatus_BPG "BPG";
BA_ "GatewayedSignal" SG_ 1039 chargeStatus_BPG 1;
BA_ "OriginatingECU" SG_ 1039 fimEndOfDischarge2Eth_BPG "BPG";
BA_ "GatewayedSignal" SG_ 1039 fimEndOfDischarge2Eth_BPG 1;
BA_ "OriginatingECU" SG_ 1039 fimEndOfDischarge1Eth_BPG "BPG";
BA_ "GatewayedSignal" SG_ 1039 fimEndOfDischarge1Eth_BPG 1;
BA_ "OriginatingECU" SG_ 1039 timeChargeToTargetEstimated_BPG "BPG";
BA_ "GatewayedSignal" SG_ 1039 timeChargeToTargetEstimated_BPG 1;
BA_ "GatewayedSignal" SG_ 1039 rightSeatBeltBcklState_SRS 1;
BA_ "OriginatingECU" SG_ 1039 rightSeatBeltBcklState_SRS "SRS";
BA_ "GatewayedSignal" SG_ 1039 leftSeatBeltBcklState_SRS 1;
BA_ "OriginatingECU" SG_ 1039 leftSeatBeltBcklState_SRS "SRS";
BA_ "GatewayedSignal" SG_ 1039 lightStopOnReq_PTC 1;
BA_ "OriginatingECU" SG_ 1039 lightStopOnReq_PTC "PTC";
BA_ "GatewayedSignal" SG_ 1039 userSOE_BPG 1;
BA_ "OriginatingECU" SG_ 1039 userSOE_BPG "BPG";
BA_ "GatewayedSignal" SG_ 1039 lowVoltagePowerMode_DABM 1;
BA_ "OriginatingECU" SG_ 1039 lowVoltagePowerMode_DABM "DABM";
BA_ "GatewayedSignal" SG_ 1039 timeChargeToFullEstimated_BPG 1;
BA_ "OriginatingECU" SG_ 1039 timeChargeToFullEstimated_BPG "BPG";
BA_ "GatewayedSignal" SG_ 1039 chargePortOpenAuthorize_BPG 1;
BA_ "OriginatingECU" SG_ 1039 chargePortOpenAuthorize_BPG "BPG";
BA_ "GatewayedSignal" SG_ 1041 lightDRLOnReq_FBCM 1;
BA_ "OriginatingECU" SG_ 1041 lightDRLOnReq_FBCM "FBCM";
BA_ "GatewayedSignal" SG_ 1041 lightSync_FBCM 1;
BA_ "OriginatingECU" SG_ 1041 lightSync_FBCM "FBCM";
BA_ "GatewayedSignal" SG_ 1041 lightHighBeamOnReq_FBCM 1;
BA_ "OriginatingECU" SG_ 1041 lightHighBeamOnReq_FBCM "FBCM";
BA_ "GatewayedSignal" SG_ 1041 lightTurnRightOnReq_FBCM 1;
BA_ "OriginatingECU" SG_ 1041 lightTurnRightOnReq_FBCM "FBCM";
BA_ "GatewayedSignal" SG_ 1041 lightTurnLeftOnReq_FBCM 1;
BA_ "OriginatingECU" SG_ 1041 lightTurnLeftOnReq_FBCM "FBCM";
BA_ "GatewayedSignal" SG_ 1041 lightLowBeamOnReq_FBCM 1;
BA_ "OriginatingECU" SG_ 1041 lightLowBeamOnReq_FBCM "FBCM";
BA_ "GatewayedSignal" SG_ 1041 lightHazardActive_FBCM 1;
BA_ "OriginatingECU" SG_ 1041 lightHazardActive_FBCM "FBCM";
BA_ "OriginatingECU" SG_ 1041 ecuUpTime_FBCM "FBCM";
BA_ "GatewayedSignal" SG_ 1041 ecuUpTime_FBCM 1;
BA_ "OriginatingECU" SG_ 1043 turnSigLh_SCCM "SCCM";
BA_ "GatewayedSignal" SG_ 1043 turnSigLh_SCCM 1;
BA_ "OriginatingECU" SG_ 1043 turnSigRh_SCCM "SCCM";
BA_ "GatewayedSignal" SG_ 1043 turnSigRh_SCCM 1;
BA_ "OriginatingECU" SG_ 1043 laneChangeLh_SCCM "SCCM";
BA_ "GatewayedSignal" SG_ 1043 laneChangeLh_SCCM 1;
BA_ "OriginatingECU" SG_ 1043 laneChangeRh_SCCM "SCCM";
BA_ "GatewayedSignal" SG_ 1043 laneChangeRh_SCCM 1;
BA_ "OriginatingECU" SG_ 1043 powerCycle12V_FBCM "FBCM";
BA_ "GatewayedSignal" SG_ 1043 powerCycle12V_FBCM 1;
BA_ "GenSigSendType" SG_ 1044 demALCPTLINSignalError_FBCM 1;
BA_ "GenSigSendType" SG_ 1044 demALCPTLINSignalLoss_FBCM 1;
BA_ "GenSigSendType" SG_ 1044 demAccessoryRelayFailure_FBCM 1;
BA_ "GenSigSendType" SG_ 1044 demAccessoryRelayError_FBCM 1;
BA_ "GenSigSendType" SG_ 1044 demAmbientLightSleepError_FBCM 1;
BA_ "GenSigSendType" SG_ 1044 demAmbientLightPowerLoss_FBCM 1;
BA_ "GenSigSendType" SG_ 1044 demBodyCANNetworkLoss_FBCM 1;
BA_ "GenSigSendType" SG_ 1044 demBrakeFluidIndicatorError_FBCM 1;
BA_ "GenSigSendType" SG_ 1044 demBrakeLightInputFault_FBCM 1;
BA_ "GenSigSendType" SG_ 1044 demCIDHallSensorSignalLoss_FBCM 1;
BA_ "GenSigSendType" SG_ 1044 demCIDHallSensorFast_FBCM 1;
BA_ "GenSigSendType" SG_ 1044 demCIDHallSensorSlowSignal_FBCM 1;
BA_ "GenSigSendType" SG_ 1044 demCIDMotorOvercurrent_FBCM 1;
BA_ "GenSigSendType" SG_ 1044 demCIDMotorUndercurrent_FBCM 1;
BA_ "GenSigSendType" SG_ 1044 demCIDMotorError_FBCM 1;
BA_ "GenSigSendType" SG_ 1044 demCIDMotorSignalLoss_FBCM 1;
BA_ "GenSigSendType" SG_ 1044 demCIDDownMovementFailure_FBCM 1;
BA_ "GenSigSendType" SG_ 1044 demCIDUpMovementFailure_FBCM 1;
BA_ "GenSigSendType" SG_ 1044 demCIDDownMovementError_FBCM 1;
BA_ "GenSigSendType" SG_ 1044 demCIDUpMovementError_FBCM 1;
BA_ "GenSigSendType" SG_ 1044 demCPDCloseError_FBCM 1;
BA_ "GenSigSendType" SG_ 1044 demCDPCloseFailure_FBCM 1;
BA_ "GenSigSendType" SG_ 1044 demCPDOpenFailure_FBCM 1;
BA_ "GenSigSendType" SG_ 1044 demCPDOpenError_FBCM 1;
BA_ "GenSigSendType" SG_ 1044 demDomeRLINSignalError_FBCM 1;
BA_ "GenSigSendType" SG_ 1044 demDomeRLINSignalLoss_FBCM 1;
BA_ "GenSigSendType" SG_ 1044 demLIN1NetworkDown_FBCM 1;
BA_ "GenSigSendType" SG_ 1044 demFLIPLLINSignalError_FBCM 1;
BA_ "GenSigSendType" SG_ 1044 demFLIPLLINSignalLoss_FBCM 1;
BA_ "GenSigSendType" SG_ 1044 demFLIPRLLINSignalError_FBCM 1;
BA_ "GenSigSendType" SG_ 1044 demFLIPRLINSignalLoss_FBCM 1;
BA_ "GenSigSendType" SG_ 1044 demChassisWUPRelayFailure_FBCM 1;
BA_ "GenSigSendType" SG_ 1042 demDomeFLINError_FBCM 1;
BA_ "GenSigSendType" SG_ 1042 demFFogLampFault_FBCM 1;
BA_ "GenSigSendType" SG_ 1042 demFSideMarkersFailure_FBCM 1;
BA_ "GenSigSendType" SG_ 1042 demFWiperDeicerRelayFailure_FBCM 1;
BA_ "GenSigSendType" SG_ 1042 demFWiperDeicerRelayError_FBCM 1;
BA_ "GenSigSendType" SG_ 1042 demHLLDRLError_FBCM 1;
BA_ "GenSigSendType" SG_ 1042 demHLLDRLMIA_FBCM 1;
BA_ "GenSigSendType" SG_ 1042 demHLLHazardError_FBCM 1;
BA_ "GenSigSendType" SG_ 1042 demHLLHazardMIA_FBCM 1;
BA_ "GenSigSendType" SG_ 1042 demHLLHighBeamError_FBCM 1;
BA_ "GenSigSendType" SG_ 1042 demHLLHighBeamMIA_FBCM 1;
BA_ "GenSigSendType" SG_ 1042 demHLLParkError_FBCM 1;
BA_ "GenSigSendType" SG_ 1042 demHLLParkMIA_FBCM 1;
BA_ "GenSigSendType" SG_ 1042 demHLLTurnSignalError_FBCM 1;
BA_ "GenSigSendType" SG_ 1042 demHLLTurnSignalMIA_FBCM 1;
BA_ "GenSigSendType" SG_ 1042 demHLLLowBeamError_FBCM 1;
BA_ "GenSigSendType" SG_ 1042 demHLLowBeamMIA_FBCM 1;
BA_ "GenSigSendType" SG_ 1042 demHLRDRLError_FBCM 1;
BA_ "GenSigSendType" SG_ 1042 demHLRDRLMIA_FBCM 1;
BA_ "GenSigSendType" SG_ 1042 demHLRHazardError_FBCM 1;
BA_ "GenSigSendType" SG_ 1042 demHLRHazardMIA_FBCM 1;
BA_ "GenSigSendType" SG_ 1042 demHLRHighBeamError_FBCM 1;
BA_ "GenSigSendType" SG_ 1042 demHLRHighBeamMIA_FBCM 1;
BA_ "GenSigSendType" SG_ 1042 demHLRParkError_FBCM 1;
BA_ "GenSigSendType" SG_ 1042 demHLRParkMIA_FBCM 1;
BA_ "GenSigSendType" SG_ 1042 demHLRTurnSignalError_FBCM 1;
BA_ "GenSigSendType" SG_ 1042 demHLRTurnSignalMIA_FBCM 1;
BA_ "GenSigSendType" SG_ 1042 demHLRLowBeamError_FBCM 1;
BA_ "GenSigSendType" SG_ 1042 demHLRLowBeamMIA_FBCM 1;
BA_ "GenSigSendType" SG_ 1042 demHazardSwitchLightFault_FBCM 1;
BA_ "GenSigSendType" SG_ 1042 demHazardSwitchInputFault_FBCM 1;
BA_ "GenSigSendType" SG_ 1042 demHLWasherPumpError_FBCM 1;
BA_ "GenSigSendType" SG_ 535 demHLWasherPumpFailure_FBCM 1;
BA_ "GenSigSendType" SG_ 535 demHomelinkPowerLoss_FBCM 1;
BA_ "GenSigSendType" SG_ 535 demHomelinkPowerError_FBCM 1;
BA_ "GenSigSendType" SG_ 535 demHoodLatchError_FBCM 1;
BA_ "GenSigSendType" SG_ 535 demHoodLatchReleaseError_FBCM 1;
BA_ "GenSigSendType" SG_ 535 demHornInputFailure_FBCM 1;
BA_ "GenSigSendType" SG_ 535 demHornLowError_FBCM 1;
BA_ "GenSigSendType" SG_ 535 demHornFailure_FBCM 1;
BA_ "GenSigSendType" SG_ 535 demLWMMLINSignalLoss_FBCM 1;
BA_ "GenSigSendType" SG_ 535 demRLSLINError_FBCM 1;
BA_ "GenSigSendType" SG_ 535 demSCCMLINSignalLoss_FBCM 1;
BA_ "GenSigSendType" SG_ 535 demBrakeFluidIndFailure_FBCM 1;
BA_ "GenSigSendType" SG_ 535 demMLIPLLINSignalError_FBCM 1;
BA_ "GenSigSendType" SG_ 535 demMLIPLLINSignalLoss_FBCM 1;
BA_ "GenSigSendType" SG_ 535 demMLIPRLINSignalError_FBCM 1;
BA_ "GenSigSendType" SG_ 535 demMLIPRLINSignalLoss_FBCM 1;
BA_ "GenSigSendType" SG_ 535 demDomeFPowerLoss_FBCM 1;
BA_ "GenSigSendType" SG_ 535 demRLSPowerLoss_FBCM 1;
BA_ "GenSigSendType" SG_ 535 demRCLLParkError_FBCM 1;
BA_ "GenSigSendType" SG_ 535 demRCLLParkMIA_FBCM 1;
BA_ "GenSigSendType" SG_ 535 demRCLLHazardError_FBCM 1;
BA_ "GenSigSendType" SG_ 535 demRCLLHazardMIA_FBCM 1;
BA_ "GenSigSendType" SG_ 535 demRCLLStopError_FBCM 1;
BA_ "GenSigSendType" SG_ 535 demRCLLStopMIA_FBCM 1;
BA_ "GenSigSendType" SG_ 535 demRCLLTailError_FBCM 1;
BA_ "GenSigSendType" SG_ 535 demRCLLTailMIA_FBCM 1;
BA_ "GenSigSendType" SG_ 535 demRCLLTurnSignalError_FBCM 1;
BA_ "GenSigSendType" SG_ 535 demRCLLTurnSignalMIA_FBCM 1;
BA_ "GenSigSendType" SG_ 535 demRCLRParkError_FBCM 1;
BA_ "GenSigSendType" SG_ 535 demRCLRParkMIA_FBCM 1;
BA_ "GenSigSendType" SG_ 535 demRCLRHazardError_FBCM 1;
BA_ "GenSigSendType" SG_ 535 demRCLRHazardMIA_FBCM 1;
BA_ "GenSigSendType" SG_ 533 demRLSLINLoss_FBCM 1;
BA_ "GenSigSendType" SG_ 533 demHLWasherPumpOVC_FBCM 1;
BA_ "GenSigSendType" SG_ 533 demRCLRStopError_FBCM 1;
BA_ "GenSigSendType" SG_ 533 demRCLRStopMIA_FBCM 1;
BA_ "GenSigSendType" SG_ 533 demRCLRTailError_FBCM 1;
BA_ "GenSigSendType" SG_ 533 demRCLRTailMIA_FBCM 1;
BA_ "GenSigSendType" SG_ 533 demRCLRTurnSignalError_FBCM 1;
BA_ "GenSigSendType" SG_ 533 demRCLRTurnSignalMIA_FBCM 1;
BA_ "GenSigSendType" SG_ 533 demRSCMLLINSignalError_FBCM 1;
BA_ "GenSigSendType" SG_ 533 demRSCMLINSignalLoss_FBCM 1;
BA_ "GenSigSendType" SG_ 533 demRSDDownMovementFailure_FBCM 1;
BA_ "GenSigSendType" SG_ 533 demRSDUpLatchFailure_FBCM 1;
BA_ "GenSigSendType" SG_ 533 demRSDLatchReleaseFailure_FBCM 1;
BA_ "GenSigSendType" SG_ 533 demRSDHallSensorSignalLoss_FBCM 1;
BA_ "GenSigSendType" SG_ 533 demRSDHallSensorSigTooFast_FBCM 1;
BA_ "GenSigSendType" SG_ 533 demRSDMotorOvercurrent_FBCM 1;
BA_ "GenSigSendType" SG_ 533 demRSDMotorUndercurrent_FBCM 1;
BA_ "GenSigSendType" SG_ 533 demRSDMotorCurrentError_FBCM 1;
BA_ "GenSigSendType" SG_ 533 demRSDMotorSignalLoss_FBCM 1;
BA_ "GenSigSendType" SG_ 533 demRSDDownMovementError_FBCM 1;
BA_ "GenSigSendType" SG_ 533 demRSDUpMovementError_FBCM 1;
BA_ "GenSigSendType" SG_ 533 demRLSPowerError_FBCM 1;
BA_ "GenSigSendType" SG_ 533 demRSDFullBrakeFailure_FBCM 1;
BA_ "GenSigSendType" SG_ 533 demRSDFullBrakeError_FBCM 1;
BA_ "GenSigSendType" SG_ 533 demRSDHalfBrakeError_FBCM 1;
BA_ "GenSigSendType" SG_ 533 demRSDUpMovementFailure_FBCM 1;
BA_ "GenSigSendType" SG_ 533 demFSideMarkerError_FBCM 1;
BA_ "GenSigSendType" SG_ 533 demWasherFluidIndSigError_FBCM 1;
BA_ "GenSigSendType" SG_ 533 demWasherPumpError_FBCM 1;
BA_ "GenSigSendType" SG_ 533 demWasherPumpFailure_FBCM 1;
BA_ "GenSigSendType" SG_ 533 demWasherFluidIndSignalLoss_FBCM 1;
BA_ "GenSigSendType" SG_ 533 demChassisWUPRelayError_FBCM 1;
BA_ "GenSigSendType" SG_ 532 fimDisableCIDMovement_FBCM 1;
BA_ "GenSigSendType" SG_ 532 fimDisableRSDPowerFoldFunc_FBCM 1;
BA_ "GenSigSendType" SG_ 532 fimTailLampService_FBCM 1;
BA_ "GenSigSendType" SG_ 532 fimBrakeLightInputFailure_FBCM 1;
BA_ "GenSigSendType" SG_ 532 fimHeadLampNotification_FBCM 1;
BA_ "OriginatingECU" SG_ 532 fimWiperHlightAutoDisabled_FBCM "FBCM";
BA_ "GatewayedSignal" SG_ 532 fimWiperHlightAutoDisabled_FBCM 1;
BA_ "GenSigSendType" SG_ 532 fimWiperHlightAutoDisabled_FBCM 1;
BA_ "GenSigSendType" SG_ 532 fimDisableHeadlampWasher_FBCM 1;
BA_ "GenSigSendType" SG_ 532 fimChargePortDoorNotif_FBCM 1;
BA_ "OriginatingECU" SG_ 532 fimWindshieldWasherNotif_FBCM "FBCM";
BA_ "GatewayedSignal" SG_ 532 fimWindshieldWasherNotif_FBCM 1;
BA_ "GenSigSendType" SG_ 532 fimWindshieldWasherNotif_FBCM 1;
BA_ "OriginatingECU" SG_ 532 fimHeadlampWasherNotif_FBCM "FBCM";
BA_ "GatewayedSignal" SG_ 532 fimHeadlampWasherNotif_FBCM 1;
BA_ "GenSigSendType" SG_ 532 fimHeadlampWasherNotif_FBCM 1;
BA_ "OriginatingECU" SG_ 532 fimBrakeFluidSensorNotif_FBCM "FBCM";
BA_ "GatewayedSignal" SG_ 532 fimBrakeFluidSensorNotif_FBCM 1;
BA_ "GenSigSendType" SG_ 532 fimBrakeFluidSensorNotif_FBCM 1;
BA_ "GenSigSendType" SG_ 532 fimFogLightNotificaton_FBCM 1;
BA_ "OriginatingECU" SG_ 1045 swchStateWshrMst_SCCM "SCCM";
BA_ "GatewayedSignal" SG_ 1045 swchStateWshrMst_SCCM 1;
BA_ "OriginatingECU" SG_ 1045 alarmModeHornStatus_FBCM "FBCM";
BA_ "GatewayedSignal" SG_ 1045 alarmModeHornStatus_FBCM 1;
BA_ "OriginatingECU" SG_ 1045 alarmModeHazardStatus_FBCM "FBCM";
BA_ "GatewayedSignal" SG_ 1045 alarmModeHazardStatus_FBCM 1;
BA_ "OriginatingECU" SG_ 1045 delcerFrontStatus_FBCM "FBCM";
BA_ "GatewayedSignal" SG_ 1045 delcerFrontStatus_FBCM 1;
BA_ "OriginatingECU" SG_ 1045 chargePortDoorStatus_FBCM "FBCM";
BA_ "GatewayedSignal" SG_ 1045 chargePortDoorStatus_FBCM 1;
BA_ "OriginatingECU" SG_ 1045 lightHazardStatus_FBCM "FBCM";
BA_ "GatewayedSignal" SG_ 1045 lightHazardStatus_FBCM 1;
BA_ "GatewayedSignal" SG_ 1045 lightFogFrontStatus_FBCM 1;
BA_ "OriginatingECU" SG_ 1045 lightFogFrontStatus_FBCM "FBCM";
BA_ "GatewayedSignal" SG_ 1045 lightDomeStatus_FBCM 1;
BA_ "OriginatingECU" SG_ 1045 lightDomeStatus_FBCM "FBCM";
BA_ "GatewayedSignal" SG_ 1045 brakeFluidLevel_FBCM 1;
BA_ "OriginatingECU" SG_ 1045 brakeFluidLevel_FBCM "FBCM";
BA_ "GatewayedSignal" SG_ 1045 lightFogFrontRightStatus_FBCM 1;
BA_ "OriginatingECU" SG_ 1045 lightFogFrontRightStatus_FBCM "FBCM";
BA_ "GatewayedSignal" SG_ 1045 lightFogFrontLeftStatus_FBCM 1;
BA_ "OriginatingECU" SG_ 1045 lightFogFrontLeftStatus_FBCM "FBCM";
BA_ "GatewayedSignal" SG_ 1045 wiperStatus_LWMM 1;
BA_ "OriginatingECU" SG_ 1045 wiperStatus_LWMM "LWMM";
BA_ "GatewayedSignal" SG_ 1045 washerFluidLevel_FBCM 1;
BA_ "OriginatingECU" SG_ 1045 washerFluidLevel_FBCM "FBCM";
BA_ "GatewayedSignal" SG_ 1045 hornStatus_FBCM 1;
BA_ "OriginatingECU" SG_ 1045 hornStatus_FBCM "FBCM";
BA_ "GatewayedSignal" SG_ 1045 stateVehicle_FBCM 1;
BA_ "OriginatingECU" SG_ 1045 stateVehicle_FBCM "FBCM";
BA_ "GatewayedSignal" SG_ 1045 frontTrunkStatus_FBCM 1;
BA_ "OriginatingECU" SG_ 1045 frontTrunkStatus_FBCM "FBCM";
BA_ "GatewayedSignal" SG_ 1045 lightFSMStatus_FBCM 1;
BA_ "OriginatingECU" SG_ 1045 lightFSMStatus_FBCM "FBCM";
BA_ "OriginatingECU" SG_ 1045 steeringHeatStatus_FBCM "FBCM";
BA_ "GatewayedSignal" SG_ 1045 steeringHeatStatus_FBCM 1;
BA_ "GatewayedSignal" SG_ 1046 humidityGlassFront_RLS 1;
BA_ "OriginatingECU" SG_ 1046 humidityGlassFront_RLS "RLS";
BA_ "GatewayedSignal" SG_ 1046 tempHumidityAir_RLS 1;
BA_ "OriginatingECU" SG_ 1046 tempHumidityAir_RLS "RLS";
BA_ "GatewayedSignal" SG_ 1046 tempGlassFront_RLS 1;
BA_ "OriginatingECU" SG_ 1046 tempGlassFront_RLS "RLS";
BA_ "GatewayedSignal" SG_ 1046 tempDewPointAir_RLS 1;
BA_ "OriginatingECU" SG_ 1046 tempDewPointAir_RLS "RLS";
BA_ "GatewayedSignal" SG_ 1046 powerSolarRight_RLS 1;
BA_ "OriginatingECU" SG_ 1046 powerSolarRight_RLS "RLS";
BA_ "GatewayedSignal" SG_ 1046 powerSolarLeft_RLS 1;
BA_ "OriginatingECU" SG_ 1046 powerSolarLeft_RLS "RLS";
VAL_ 1160 demIRSensor2MIA_DCFR 3 "SNA" 2 "Untested" 1 "Set" 0 "Cleared" ;
VAL_ 1160 demIRSensor1MIA_DCFR 3 "SNA" 2 "Untested" 1 "Set" 0 "Cleared" ;
VAL_ 1160 demWinSwErr_DCFR 3 "SNA" 2 "Untested" 1 "Set" 0 "Cleared" ;
VAL_ 1160 demWinSwMIA_DCFR 3 "SNA" 2 "Untested" 1 "Set" 0 "Cleared" ;
VAL_ 1160 demLINNetworkFail_DCFR 3 "SNA" 2 "Untested" 1 "Set" 0 "Cleared" ;
VAL_ 1160 demBodyCANAmbTempMsgErr_DCFR 3 "SNA" 2 "Untested" 1 "Set" 0 "Cleared" ;
VAL_ 1160 demBodyCANAmbTempMsgMiss_DCFR 3 "SNA" 2 "Untested" 1 "Set" 0 "Cleared" ;
VAL_ 1160 demBodyCANCrashMsgErr_DCFR 3 "SNA" 2 "Untested" 1 "Set" 0 "Cleared" ;
VAL_ 1160 demBodyCANCrashMsgMiss_DCFR 3 "SNA" 2 "Untested" 1 "Set" 0 "Cleared" ;
VAL_ 1160 demBodyCANChildLkMsgErr_DCFR 3 "SNA" 2 "Untested" 1 "Set" 0 "Cleared" ;
VAL_ 1160 demBodyCANChildLkMsgMiss_DCFR 3 "SNA" 2 "Untested" 1 "Set" 0 "Cleared" ;
VAL_ 1160 demBodyCANLockMessageError_DCFR 3 "SNA" 2 "Untested" 1 "Set" 0 "Cleared" ;
VAL_ 1160 demBodyCANLkUnlkMsgMiss_DCFR 3 "SNA" 2 "Untested" 1 "Set" 0 "Cleared" ;
VAL_ 1160 demBodyCANOpClMsgErr_DCFR 3 "SNA" 2 "Untested" 1 "Set" 0 "Cleared" ;
VAL_ 1160 demBodyCANOpClMsgMiss_DCFR 3 "SNA" 2 "Untested" 1 "Set" 0 "Cleared" ;
VAL_ 1160 demBodyCANIMUMessageError_DCFR 3 "SNA" 2 "Untested" 1 "Set" 0 "Cleared" ;
VAL_ 1160 demBodyCANIMUMsgMiss_DCFR 3 "SNA" 2 "Untested" 1 "Set" 0 "Cleared" ;
VAL_ 1160 demBodyCANVehSpdMsgErr_DCFR 3 "SNA" 2 "Untested" 1 "Set" 0 "Cleared" ;
VAL_ 1160 demBodyCANVehSpdMsgMiss_DCFR 3 "SNA" 2 "Untested" 1 "Set" 0 "Cleared" ;
VAL_ 1160 demBodyCANNetworkFailure_DCFR 3 "SNA" 2 "Untested" 1 "Set" 0 "Cleared" ;
VAL_ 1160 demMirrorGlassPosSnsShCir_DCFR 3 "SNA" 2 "Untested" 1 "Set" 0 "Cleared" ;
VAL_ 1160 demMirrorGlassPosSnsOpenCir_DCFR 3 "SNA" 2 "Untested" 1 "Set" 0 "Cleared" ;
VAL_ 1160 demMirrorGlassPosSnsSnEr_DCFR 3 "SNA" 2 "Untested" 1 "Set" 0 "Cleared" ;
VAL_ 1160 demMirrorGlassPosSnsSnLoss_DCFR 3 "SNA" 2 "Untested" 1 "Set" 0 "Cleared" ;
VAL_ 1160 demMirrorGlassPosNotReached_DCFR 3 "SNA" 2 "Untested" 1 "Set" 0 "Cleared" ;
VAL_ 1160 demMirrorGlassMvtUcmd_DCFR 3 "SNA" 2 "Untested" 1 "Set" 0 "Cleared" ;
VAL_ 1160 demMirrorGlassMvFail_DCFR 3 "SNA" 2 "Untested" 1 "Set" 0 "Cleared" ;
VAL_ 1160 demIntOpenSwSnEr_DCFR 3 "SNA" 2 "Untested" 1 "Set" 0 "Cleared" ;
VAL_ 1160 demIntOpenSwSnLoss_DCFR 3 "SNA" 2 "Untested" 1 "Set" 0 "Cleared" ;
VAL_ 1160 demIntRelSwSnEr_DCFR 3 "SNA" 2 "Untested" 1 "Set" 0 "Cleared" ;
VAL_ 1160 demInteriorReleaseSwSnLoss_DCFR 3 "SNA" 2 "Untested" 1 "Set" 0 "Cleared" ;
VAL_ 1160 demDoorUnlockSwSnError_DCFR 3 "SNA" 2 "Untested" 1 "Set" 0 "Cleared" ;
VAL_ 655 demDoorLockSwitchSignalLoss_DCFR 3 "SNA" 2 "Untested" 1 "Set" 0 "Cleared" ;
VAL_ 655 demDoorExtCapSwSnEr_DCFR 3 "SNA" 2 "Untested" 1 "Set" 0 "Cleared" ;
VAL_ 655 demDoorExtCapSwSnLoss_DCFR 3 "SNA" 2 "Untested" 1 "Set" 0 "Cleared" ;
VAL_ 655 demDoorExtCapSwPower_DCFR 3 "SNA" 2 "Untested" 1 "Set" 0 "Cleared" ;
VAL_ 655 demDoorExtCapSwNoPower_DCFR 3 "SNA" 2 "Untested" 1 "Set" 0 "Cleared" ;
VAL_ 655 demDoorExtMechSwSnEr_DCFR 3 "SNA" 2 "Untested" 1 "Set" 0 "Cleared" ;
VAL_ 655 demDoorExtMechSwSnLoss_DCFR 3 "SNA" 2 "Untested" 1 "Set" 0 "Cleared" ;
VAL_ 655 demDoorExtMechSwPower_DCFR 3 "SNA" 2 "Untested" 1 "Set" 0 "Cleared" ;
VAL_ 655 demDoorExtMechSwPowerLoss_DCFR 3 "SNA" 2 "Untested" 1 "Set" 0 "Cleared" ;
VAL_ 655 demWindowHallSignalError_DCFR 3 "SNA" 2 "Untested" 1 "Set" 0 "Cleared" ;
VAL_ 655 demWindowHallSnsPowerLoss_DCFR 3 "SNA" 2 "Untested" 1 "Set" 0 "Cleared" ;
VAL_ 655 demWindowHallSignalLoss_DCFR 3 "SNA" 2 "Untested" 1 "Set" 0 "Cleared" ;
VAL_ 655 demWindowVelocityTimeout_DCFR 3 "SNA" 2 "Untested" 1 "Set" 0 "Cleared" ;
VAL_ 655 demCinchCloseSignalError_DCFR 3 "SNA" 2 "Untested" 1 "Set" 0 "Cleared" ;
VAL_ 655 demReverseCinchTimeout_DCFR 3 "SNA" 2 "Untested" 1 "Set" 0 "Cleared" ;
VAL_ 655 demCinchOpenSignalError_DCFR 3 "SNA" 2 "Untested" 1 "Set" 0 "Cleared" ;
VAL_ 655 demDoorCinchTimeout_DCFR 3 "SNA" 2 "Untested" 1 "Set" 0 "Cleared" ;
VAL_ 655 demDoorLatchOpenAlwaysOn_DCFR 3 "SNA" 2 "Untested" 1 "Set" 0 "Cleared" ;
VAL_ 655 demDoorLatchOpenPowerLoss_DCFR 3 "SNA" 2 "Untested" 1 "Set" 0 "Cleared" ;
VAL_ 655 demDoorLatchOpenSignalError_DCFR 3 "SNA" 2 "Untested" 1 "Set" 0 "Cleared" ;
VAL_ 655 demDoorLatchOpenSignalLoss_DCFR 3 "SNA" 2 "Untested" 1 "Set" 0 "Cleared" ;
VAL_ 655 demDoorLatchPawlSignalError_DCFR 3 "SNA" 2 "Untested" 1 "Set" 0 "Cleared" ;
VAL_ 655 demDoorLatchPawlSignalLoss_DCFR 3 "SNA" 2 "Untested" 1 "Set" 0 "Cleared" ;
VAL_ 655 demDoorLatchSensorSnError_DCFR 3 "SNA" 2 "Untested" 1 "Set" 0 "Cleared" ;
VAL_ 655 demDoorLatchAjarSigLoss_DCFR 3 "SNA" 2 "Untested" 1 "Set" 0 "Cleared" ;
VAL_ 655 demDoorBrakeHallSnLoss_DCFR 3 "SNA" 2 "Untested" 1 "Set" 0 "Cleared" ;
VAL_ 655 demDoorHallSensorSnErr_DCFR 3 "SNA" 2 "Untested" 1 "Set" 0 "Cleared" ;
VAL_ 655 doorHallSensorSlow_DCFR 3 "SNA" 2 "Untested" 1 "Set" 0 "Cleared" ;
VAL_ 655 demDoorHallSensorFast_DCFR 3 "SNA" 2 "Untested" 1 "Set" 0 "Cleared" ;
VAL_ 655 demDoorHallSensorSignalLoss_DCFR 3 "SNA" 2 "Untested" 1 "Set" 0 "Cleared" ;
VAL_ 655 demMirrorMovetUncmd_DCFR 3 "SNA" 2 "Untested" 1 "Set" 0 "Cleared" ;
VAL_ 655 demMirrorMovementFailure_DCFR 3 "SNA" 2 "Untested" 1 "Set" 0 "Cleared" ;
VAL_ 654 demDEMNotification_DCFR 3 "SNA" 2 "Untested" 1 "Set" 0 "Cleared" ;
VAL_ 654 demDEMAssert_DCFR 3 "SNA" 2 "Untested" 1 "Set" 0 "Cleared" ;
VAL_ 654 demWindowDownFailure_DCFR 3 "SNA" 2 "Untested" 1 "Set" 0 "Cleared" ;
VAL_ 654 demWindowDownUncommanded_DCFR 3 "SNA" 2 "Untested" 1 "Set" 0 "Cleared" ;
VAL_ 654 demWindowUpUncommanded_DCFR 3 "SNA" 2 "Untested" 1 "Set" 0 "Cleared" ;
VAL_ 654 demWindowUpFailure_DCFR 3 "SNA" 2 "Untested" 1 "Set" 0 "Cleared" ;
VAL_ 654 demDoorCinchUncommanded_DCFR 3 "SNA" 2 "Untested" 1 "Set" 0 "Cleared" ;
VAL_ 654 demDoorCinchReleaseFailure_DCFR 3 "SNA" 2 "Untested" 1 "Set" 0 "Cleared" ;
VAL_ 654 demDoorMovementFault_DCFR 3 "SNA" 2 "Untested" 1 "Set" 0 "Cleared" ;
VAL_ 654 demDoorCloseUncommanded_DCFR 3 "SNA" 2 "Untested" 1 "Set" 0 "Cleared" ;
VAL_ 654 demDoorCloseFailure_DCFR 3 "SNA" 2 "Untested" 1 "Set" 0 "Cleared" ;
VAL_ 654 demLatchTimeout_DCFR 3 "SNA" 2 "Untested" 1 "Set" 0 "Cleared" ;
VAL_ 654 demDoorDirectionFault_DCFR 3 "SNA" 2 "Untested" 1 "Set" 0 "Cleared" ;
VAL_ 654 demDoorOpenUncommanded_DCFR 3 "SNA" 2 "Untested" 1 "Set" 0 "Cleared" ;
VAL_ 654 demDoorOpenFailure_DCFR 3 "SNA" 2 "Untested" 1 "Set" 0 "Cleared" ;
VAL_ 654 demMirrorMotorSignalLoss_DCFR 3 "SNA" 2 "Untested" 1 "Set" 0 "Cleared" ;
VAL_ 654 demMirrorMotorOvercurrent_DCFR 3 "SNA" 2 "Untested" 1 "Set" 0 "Cleared" ;
VAL_ 654 demWindowMotorSignalLoss_DCFR 3 "SNA" 2 "Untested" 1 "Set" 0 "Cleared" ;
VAL_ 654 demWindowCurrentFailure_DCFR 3 "SNA" 2 "Untested" 1 "Set" 0 "Cleared" ;
VAL_ 654 demWindowMotorUndercurrent_DCFR 3 "SNA" 2 "Untested" 1 "Set" 0 "Cleared" ;
VAL_ 654 demWindowMotorOvercurrent_DCFR 3 "SNA" 2 "Untested" 1 "Set" 0 "Cleared" ;
VAL_ 654 demCinchMotorPowerLoss_DCFR 3 "SNA" 2 "Untested" 1 "Set" 0 "Cleared" ;
VAL_ 654 demCinchMotorOvercurrent_DCFR 3 "SNA" 2 "Untested" 1 "Set" 0 "Cleared" ;
VAL_ 654 demLatchUncommandedOpen_DCFR 3 "SNA" 2 "Untested" 1 "Set" 0 "Cleared" ;
VAL_ 654 demDoorLatchStateError_DCFR 3 "SNA" 2 "Untested" 1 "Set" 0 "Cleared" ;
VAL_ 654 demDoorLatchPowerLoss_DCFR 3 "SNA" 2 "Untested" 1 "Set" 0 "Cleared" ;
VAL_ 654 demLatchMotorOvercurrent_DCFR 3 "SNA" 2 "Untested" 1 "Set" 0 "Cleared" ;
VAL_ 654 demDoorBrakeMotorSignalLoss_DCFR 3 "SNA" 2 "Untested" 1 "Set" 0 "Cleared" ;
VAL_ 654 demDoorBrakeOvercurrent_DCFR 3 "SNA" 2 "Untested" 1 "Set" 0 "Cleared" ;
VAL_ 654 demDoorCurrentSignalLoss_DCFR 3 "SNA" 2 "Untested" 1 "Set" 0 "Cleared" ;
VAL_ 654 demDoorMotorCurrentFailure_DCFR 3 "SNA" 2 "Untested" 1 "Set" 0 "Cleared" ;
VAL_ 654 demDoorMotorOvercurrent_DCFR 3 "SNA" 2 "Untested" 1 "Set" 0 "Cleared" ;
VAL_ 896 changeBaudRate_TOOL 7 "SNA" 2 "Baud500k" 1 "Baud250k" 0 "Baud125k" ;
VAL_ 367 statePRND_PTC 255 "SNA" 3 "Drive" 2 "Neutral" 1 "Reverse" 0 "Park" ;
VAL_ 534 fimPreventDrive_FBCM 3 "SNA" 2 "InhibitedOnlyRemoteCause" 1 "InhibitedLocalCause" 0 "NotInhibited" ;
VAL_ 534 eventsUnread_FBCM 3 "SNA" 2 "NotUsed" 1 "NewEvents" 0 "NoNewEvents" ;
VAL_ 534 eventNotification_FBCM 3 "SNA" 2 "Untested" 1 "Set" 0 "Cleared" ;
VAL_ 534 eventAssert_FBCM 3 "SNA" 2 "Untested" 1 "Set" 0 "Cleared" ;
VAL_ 529 wiperSpeedRls_FBCM 3 "SNA" 2 "HighWiperSpeed" 1 "LowWiperSpeed" 0 "Stop" ;
VAL_ 529 headLightsOnRls_FBCM 1 "On" 0 "Off" ;
VAL_ 529 rsSchwallRls_FBCM 1 "Active" 0 "Inactive" ;
VAL_ 529 ambientBrightnessRls_FBCM 2047 "Error" ;
VAL_ 529 rlsStatus_FBCM 7 "SNA" 3 "RlsActive" 2 "OverVoltage" 1 "LowVoltage" 0 "RlsRebooting" ;
VAL_ 529 rsErr_FBCM 1 "Error" 0 "Normal" ;
VAL_ 529 lsErr_FBCM 1 "Error" 0 "Normal" ;
VAL_ 529 rlsCommunication_FBCM 1 "Error" 0 "Normal" ;
VAL_ 529 helligkeitIr_FBCM 1 "Error" 0 "Calculating" ;
VAL_ 529 helligkeitFw_FBCM 1 "Error" 0 "Calculating" ;
VAL_ 529 rsErrHumSenseRls_FBCM 1 "Error" 0 "Normal" ;
VAL_ 529 humSnsIntFltRls_FBCM 1 "Error" 0 "Normal" ;
VAL_ 530 glassTempRls_FBCM 3 "SNA" 2 "Err" 1 "Vel" 0 "Nr" ;
VAL_ 530 humidityAirTempRls_FBCM 3 "SNA" 2 "Err" 1 "Vel" 0 "Nr" ;
VAL_ 530 dewpointTempRls_FBCM 3 "SNA" 2 "Err" 1 "Vel" 0 "Nr" ;
VAL_ 530 relHumidityRls_FBCM 3 "SNA" 2 "Err" 1 "Vel" 0 "Nr" ;
VAL_ 15 fimLiftgateLatchNotification_BGW 3 "SNA" 2 "InhibitedOnlyRemoteCause" 1 "InhibitedLocalCause" 0 "NotInhibited" ;
VAL_ 15 fimRearFogLampNotification_BGW 3 "SNA" 2 "InhibitedOnlyRemoteCause" 1 "InhibitedLocalCause" 0 "NotInhibited" ;
VAL_ 15 fimLimitVehicleSpeed_BGW 3 "SNA" 2 "InhibitedOnlyRemoteCause" 1 "InhibitedLocalCause" 0 "NotInhibited" ;
VAL_ 15 fimDisableChargingMat_BGW 3 "SNA" 2 "InhibitedOnlyRemoteCause" 1 "InhibitedLocalCause" 0 "NotInhibited" ;
VAL_ 15 fimDisablePowerLiftgate_BGW 3 "SNA" 2 "InhibitedOnlyRemoteCause" 1 "InhibitedLocalCause" 0 "NotInhibited" ;
VAL_ 15 fim001InhibitDrive_BGW 3 "SNA" 2 "InhibitedOnlyRemoteCause" 1 "InhibitedLocalCause" 0 "NotInhibited" ;
VAL_ 15 eventsUnread_BGW 3 "SNA" 2 "NotUsed" 1 "NewEvents" 0 "NoNewEvents" ;
VAL_ 15 eventNotification_BGW 3 "SNA" 2 "Untested" 1 "Set" 0 "Cleared" ;
VAL_ 15 eventAssert_BGW 3 "SNA" 2 "Untested" 1 "Set" 0 "Cleared" ;
VAL_ 15 dem001IhubMIAOnEthernet_BGW 3 "SNA" 2 "Untested" 1 "Set" 0 "Cleared" ;
VAL_ 269 windowAbsReqRearRight_IHUB 255 "SNA" ;
VAL_ 269 windowAbsReqRearLeft_IHUB 255 "SNA" ;
VAL_ 269 windowAbsReqFrontRight_IHUB 255 "SNA" ;
VAL_ 269 windowAbsReqFrontLeft_IHUB 255 "SNA" ;
VAL_ 269 chargePortDoorOpenReq_IHUB 3 "SNA" 2 "NoCommand" 1 "Open" 0 "Close" ;
VAL_ 269 windowReqFrontLeft_IHUB 7 "SNA" 4 "PropUp" 3 "PropDown" 2 "AutoUp" 1 "AutoDown" 0 "NoCommand" ;
VAL_ 269 windowReqFrontRight_IHUB 7 "SNA" 4 "PropUp" 3 "PropDown" 2 "AutoUp" 1 "AutoDown" 0 "NoCommand" ;
VAL_ 269 windowReqRearLeft_IHUB 7 "SNA" 4 "PropUp" 3 "PropDown" 2 "AutoUp" 1 "AutoDown" 0 "NoCommand" ;
VAL_ 269 windowReqRearRight_IHUB 7 "SNA" 4 "PropUp" 3 "PropDown" 2 "AutoUp" 1 "AutoDown" 0 "NoCommand" ;
VAL_ 269 mirrorDimmingEnableDisable_IHUB 3 "SNA" 1 "Enable" 0 "Disable" ;
VAL_ 269 lightHazardOnReq_IHUB 3 "SNA" 1 "On" 0 "Off" ;
VAL_ 269 hornOnReq_IHUB 3 "SNA" 1 "On" 0 "Off" ;
VAL_ 714 fimPreventDrive_DCRR 3 "SNA" 2 "InhibitedOnlyRemoteCause" 1 "InhibitedLocalCause" 0 "NotInhibited" ;
VAL_ 714 fimNoCurrent_DCRR 3 "SNA" 2 "InhibitedOnlyRemoteCause" 1 "InhibitedLocalCause" 0 "NotInhibited" ;
VAL_ 714 eventsUnread_DCRR 3 "SNA" 2 "NotUsed" 1 "NewEvents" 0 "NoNewEvents" ;
VAL_ 714 eventAssert_DCRR 3 "SNA" 2 "Untested" 1 "Set" 0 "Cleared" ;
VAL_ 714 eventNotification_DCRR 3 "SNA" 2 "Untested" 1 "Set" 0 "Cleared" ;
VAL_ 714 fimOverCurrent_DCRR 3 "SNA" 2 "InhibitedOnlyRemoteCause" 1 "InhibitedLocalCause" 0 "NotInhibited" ;
VAL_ 682 fimPreventDrive_DCRL 3 "SNA" 2 "InhibitedOnlyRemoteCause" 1 "InhibitedLocalCause" 0 "NotInhibited" ;
VAL_ 682 fimNoCurrent_DCRL 3 "SNA" 2 "InhibitedOnlyRemoteCause" 1 "InhibitedLocalCause" 0 "NotInhibited" ;
VAL_ 682 eventsUnread_DCRL 3 "SNA" 2 "NotUsed" 1 "NewEvents" 0 "NoNewEvents" ;
VAL_ 682 eventAssert_DCRL 3 "SNA" 2 "Untested" 1 "Set" 0 "Cleared" ;
VAL_ 682 eventNotification_DCRL 3 "SNA" 2 "Untested" 1 "Set" 0 "Cleared" ;
VAL_ 682 fimOverCurrent_DCRL 3 "SNA" 2 "InhibitedOnlyRemoteCause" 1 "InhibitedLocalCause" 0 "NotInhibited" ;
VAL_ 650 fimPreventDrive_DCFR 3 "SNA" 2 "InhibitedOnlyRemoteCause" 1 "InhibitedLocalCause" 0 "NotInhibited" ;
VAL_ 650 fimNoCurrent_DCFR 3 "SNA" 2 "InhibitedOnlyRemoteCause" 1 "InhibitedLocalCause" 0 "NotInhibited" ;
VAL_ 650 eventsUnread_DCFR 3 "SNA" 2 "NotUsed" 1 "NewEvents" 0 "NoNewEvents" ;
VAL_ 650 eventAssert_DCFR 3 "SNA" 2 "Untested" 1 "Set" 0 "Cleared" ;
VAL_ 650 eventNotification_DCFR 3 "SNA" 2 "Untested" 1 "Set" 0 "Cleared" ;
VAL_ 650 fimOverCurrent_DCFR 3 "SNA" 2 "InhibitedOnlyRemoteCause" 1 "InhibitedLocalCause" 0 "NotInhibited" ;
VAL_ 610 fimPreventDrive_DCFL 3 "SNA" 2 "InhibitedOnlyRemoteCause" 1 "InhibitedLocalCause" 0 "NotInhibited" ;
VAL_ 610 fimNoCurrent_DCFL 3 "SNA" 2 "InhibitedOnlyRemoteCause" 1 "InhibitedLocalCause" 0 "NotInhibited" ;
VAL_ 610 eventsUnread_DCFL 3 "SNA" 2 "NotUsed" 1 "NewEvents" 0 "NoNewEvents" ;
VAL_ 610 eventAssert_DCFL 3 "SNA" 2 "Untested" 1 "Set" 0 "Cleared" ;
VAL_ 610 eventNotification_DCFL 3 "SNA" 2 "Untested" 1 "Set" 0 "Cleared" ;
VAL_ 610 fimOverCurrent_DCFL 3 "SNA" 2 "InhibitedOnlyRemoteCause" 1 "InhibitedLocalCause" 0 "NotInhibited" ;
VAL_ 267 vehicleSpeedDir_PTC 3 "SNA" 1 "Positive" 0 "Negative" ;
VAL_ 267 vehicleSpeedQ_ESP 3 "InSpec" 0 "UndefinableAccuracySna" ;
VAL_ 271 wiperServiceMode_IHUB 3 "SNA" 1 "True" 0 "False" ;
VAL_ 271 nightModeSelect_IHUB 3 "SNA" 1 "True" 0 "False" ;
VAL_ 271 rearDisplayUpDownReq_IHUB 7 "SNA" 3 "NoAction" 2 "Stop" 1 "UnfoldDown" 0 "FoldUp" ;
VAL_ 271 panelSelectForBrightness_IHUB 7 "SNA" 5 "All" 4 "Dbpc" 3 "Rrdp" 2 "Rldp" 1 "Pdp" 0 "Ddp" ;
VAL_ 271 alarmModeHazard_IHUB 3 "SNA" 1 "TurnLightOn" 0 "TurnLightOff" ;
VAL_ 271 alarmModeHorn_IHUB 3 "SNA" 1 "On" 0 "Off" ;
VAL_ 520 seatBackCmdFR_BGW 3 "SNA" 2 "MoveBackward" 1 "MoveForward" 0 "Stop" ;
VAL_ 520 seatBackCmdFL_BGW 3 "SNA" 2 "MoveBackward" 1 "MoveForward" 0 "Stop" ;
VAL_ 520 seatCushionBolsterCmdFR_BGW 7 "SNA" 4 "HoldUpward" 3 "TapUpward" 2 "HoldDownward" 1 "TapDownward" 0 "NoCommand" ;
VAL_ 520 seatCushionTiltCmdFR_BGW 3 "SNA" 2 "MoveDown" 1 "MoveUp" 0 "Stop" ;
VAL_ 520 seatBackBolsterCmdFR_BGW 7 "SNA" 4 "HoldRearward" 3 "TapRearward" 2 "HoldForward" 1 "TapForward" 0 "NoCommand" ;
VAL_ 520 seatBackLumbarCmdFL_BGW 7 "SNA" 4 "MoveDown" 3 "MoveUp" 2 "MoveRearward" 1 "MoveForward" 0 "NoCommand" ;
VAL_ 520 seatCushionTiltCmdFL_BGW 3 "SNA" 2 "MoveDown" 1 "MoveUp" 0 "Stop" ;
VAL_ 520 seatTrackCmdFR_BGW 3 "SNA" 2 "MoveBackward" 1 "MoveForward" 0 "Stop" ;
VAL_ 520 seatLiftCmdFR_BGW 3 "SNA" 2 "MoveDown" 1 "MoveUp" 0 "Stop" ;
VAL_ 520 seatBackLumbarCmdFR_BGW 7 "SNA" 4 "MoveDown" 3 "MoveUp" 2 "MoveRearward" 1 "MoveForward" 0 "NoCommand" ;
VAL_ 520 seatTrackCmdFL_BGW 3 "SNA" 2 "MoveBackward" 1 "MoveForward" 0 "Stop" ;
VAL_ 520 seatLiftCmdFL_BGW 3 "SNA" 2 "MoveDown" 1 "MoveUp" 0 "Stop" ;
VAL_ 520 seatCushionBolsterCmdFL_BGW 7 "SNA" 4 "HoldUpward" 3 "TapUpward" 2 "HoldDownward" 1 "TapDownward" 0 "NoCommand" ;
VAL_ 520 seatBackBolsterCmdFL_BGW 7 "SNA" 4 "HoldRearward" 3 "TapRearward" 2 "HoldForward" 1 "TapForward" 0 "NoCommand" ;
VAL_ 526 lightLaneChangeRightOnReq_SDCM 3 "SNA" 2 "TurnLightOn" 1 "TurnLightOff" 0 "NoCommand" ;
VAL_ 526 lightLaneChangeLeftOnReq_SDCM 3 "SNA" 2 "TurnLightOn" 1 "TurnLightOff" 0 "NoCommand" ;
VAL_ 526 mirrorDimmingLvlReq_SDCM 7 "SNA" 5 "Level5" 4 "Level4" 3 "Level3" 2 "Level2" 1 "Level1" 0 "Off" ;
VAL_ 526 lightTurnLeftOnReq_SDCM 3 "SNA" 1 "TurnLightOn" 0 "TurnLightOff" ;
VAL_ 526 lightTurnRightOnReq_SDCM 3 "SNA" 1 "TurnLightOn" 0 "TurnLightOff" ;
VAL_ 608 doorLockReq_DCFL 3 "SNA" 2 "LockRequest" 1 "UnlockRequest" 0 "NoRequest" ;
VAL_ 608 lockUnlockReq_FLLUS 3 "SNA" 2 "LockRequest" 1 "UnlockRequest" 0 "NoRequest" ;
VAL_ 608 doorSafeMode_DCFL 3 "SNA" 1 "SafeMode" 0 "NormalMode" ;
VAL_ 608 doorLatchPawlOpen_DCFL 3 "SNA" 2 "Error" 1 "On" 0 "Off" ;
VAL_ 608 doorLatchFault_DCFL 3 "SNA" 1 "True" 0 "False" ;
VAL_ 608 childLockButtonState_DCFL 3 "SNA" 2 "NoChange" 1 "Unlock" 0 "Lock" ;
VAL_ 608 doorIsUnlatched_DCFL 3 "SNA" 1 "True" 0 "False" ;
VAL_ 608 doorExtSwitch_DCFL 3 "SNA" 1 "True" 0 "False" ;
VAL_ 608 doorMirrorState_DCFL 7 "SNA" 4 "Retracting" 3 "Retracted" 2 "Presenting" 1 "Presented" 0 "Unknown" ;
VAL_ 608 doorState_DCFL 15 "SNA" 9 "DoorCinchingFailure" 8 "DoorUnlatchingError" 7 "DoorClosingError" 6 "DoorOpeningError" 5 "DoorClosingObstruction" 4 "DoorOpeningObstruction" 3 "DoorClosing" 2 "DoorOpening" 1 "DoorOpen" 0 "DoorClosed" ;
VAL_ 608 mirrorHeaterState_DCFL 3 "SNA" 2 "Fault" 1 "On" 0 "Off" ;
VAL_ 608 sideRepeaterState_DCFL 3 "SNA" 2 "LightFault" 1 "LightOn" 0 "LightOff" ;
VAL_ 608 windowStatusFl_DCFL 7 "SNA" 5 "TempShutoff" 4 "Error" 3 "WindowRollingDown" 2 "WindowRollingUp" 1 "WindowOpen" 0 "WindowClosed" ;
VAL_ 608 mirrorFoldFeedbackLeft_DCFL 3 "SNA" 2 "FoldIn" 1 "FoldOut" 0 "NoCommand" ;
VAL_ 608 mirrorDefrostGlassStatusLh_DCFL 3 "SNA" 2 "Error" 1 "On" 0 "Off" ;
VAL_ 608 mirrorStatusMovUpDownLeft_DCFL 3 "SNA" 2 "MovingDown" 1 "MovingUp" 0 "NotMoving" ;
VAL_ 608 mirrorStatusMovInOutLeft_DCFL 3 "SNA" 2 "MovingOut" 1 "MovingIn" 0 "NotMoving" ;
VAL_ 608 mirrorDefrostCamStatusLeft_DCFL 3 "SNA" 2 "Error" 1 "On" 0 "Off" ;
VAL_ 608 mirrorFoldAutoStatusLeft_DCFL 3 "SNA" 2 "Error" 1 "On" 0 "Off" ;
VAL_ 608 mirrorDimEnabDisableStatus_DCFL 3 "SNA" 2 "Error" 1 "On" 0 "Off" ;
VAL_ 608 errorAMPFL_DCFL 1 "True" 0 "False" ;
VAL_ 608 errorALDFL_DCFL 1 "True" 0 "False" ;
VAL_ 608 wakeUpCause_DCFL 7 "SNA" 4 "Fbcm" 3 "ExtDoorOpenSw" 2 "IntOpenCloseSw" 1 "IntDoorReleaseSw" 0 "Unknown" ;
VAL_ 609 windowReqAll_DCFL 7 "SNA" 6 "AutoUp" 5 "AutoDown" 2 "PropUp" 1 "PropDown" 0 "NoCommand" ;
VAL_ 609 windowReqRearLeft_DCFL 7 "SNA" 6 "AutoUp" 5 "AutoDown" 2 "PropUp" 1 "PropDown" 0 "NoCommand" ;
VAL_ 609 windowReqRearRight_DCFL 7 "SNA" 6 "AutoUp" 5 "AutoDown" 2 "PropUp" 1 "PropDown" 0 "NoCommand" ;
VAL_ 609 windowReqFrontLeft_DCFL 7 "SNA" 6 "AutoUp" 5 "AutoDown" 2 "PropUp" 1 "PropDown" 0 "NoCommand" ;
VAL_ 609 windowReqFrontRight_DCFL 7 "SNA" 6 "AutoUp" 5 "AutoDown" 2 "PropUp" 1 "PropDown" 0 "NoCommand" ;
VAL_ 609 doorMirrorFoldCmd_DCFL 3 "SNA" 2 "FoldIn" 1 "FoldOut" 0 "NoCommand" ;
VAL_ 609 doorExtDriverRearRelease_DCFL 3 "SNA" 2 "Fault" 1 "Pressed" 0 "Unpressed" ;
VAL_ 609 doorIntDriverRearRelease_DCFL 3 "SNA" 2 "Fault" 1 "Pressed" 0 "Unpressed" ;
VAL_ 609 doorDriverFrontPresentReq_DCFL 3 "SNA" 2 "Fault" 1 "Pressed" 0 "Unpressed" ;
VAL_ 611 autoDoorLockStatus_DCFL 3 "SNA" 1 "True" 0 "False" ;
VAL_ 611 autoMirrorTiltStatus_DCFL 3 "SNA" 1 "True" 0 "False" ;
VAL_ 628 seatMsgIntensityStatusFL_DSM 7 "SNA" 5 "5" 4 "4" 3 "3" 2 "2" 1 "1" 0 "0" ;
VAL_ 628 seatHeatVentStatusFL_DSM 7 "SNA" 6 "VentHigh" 5 "VentMedium" 4 "VentLow" 3 "HeatHigh" 2 "HeatMedium" 1 "HeatLow" 0 "Off" ;
VAL_ 628 seatCushionMassageStatusFL_DSM 3 "SNA" 1 "On" 0 "Off" ;
VAL_ 628 seatBackMassageStatusFL_DSM 3 "SNA" 1 "On" 0 "Off" ;
VAL_ 628 seatMassageTypeStatusFL_DSM 7 "SNA" 3 "Type3" 2 "Type2" 1 "Type1" 0 "Off" ;
VAL_ 628 seatFrontLeftOccupied_DSM 3 "SNA" 1 "True" 0 "False" ;
VAL_ 628 seatInitStatus_DSM 3 "SNA" 1 "InitStatusFault" 0 "InitStatusNoFault" ;
VAL_ 628 seatVBatPowerStatus_DSM 3 "SNA" 1 "VbatMotorFault" 0 "VbatMotorNoFault" ;
VAL_ 628 seatVBatEleStatus_DSM 3 "SNA" 1 "VbatComfortFault" 0 "VbatComfortNoFault" ;
VAL_ 628 seatFaultStatus_DSM 3 "SNA" 2 "FaultStatusFaultFailure" 1 "FaultStatusFaultWarning" 0 "FaultStatusNoFault" ;
VAL_ 628 seatAntiPanicStatus_DSM 3 "SNA" 2 "AntiPanicStatusUnused" 1 "AntiPanicStatusActive" 0 "AntiPanicStatusInactive" ;
VAL_ 648 doorLockReq_DCFR 3 "SNA" 2 "LockRequest" 1 "UnlockRequest" 0 "NoRequest" ;
VAL_ 648 lockUnlockReq_FRLUS 3 "SNA" 2 "LockRequest" 1 "UnlockRequest" 0 "NoRequest" ;
VAL_ 648 doorSafeMode_DCFR 3 "SNA" 1 "SafeMode" 0 "NormalMode" ;
VAL_ 648 doorLatchPawlOpen_DCFR 3 "SNA" 2 "Error" 1 "On" 0 "Off" ;
VAL_ 648 doorLatchFault_DCFR 3 "SNA" 1 "True" 0 "False" ;
VAL_ 648 childLockButtonState_DCFR 3 "SNA" 2 "NoChange" 1 "Unlock" 0 "Lock" ;
VAL_ 648 doorIsUnlatched_DCFR 3 "SNA" 1 "True" 0 "False" ;
VAL_ 648 doorExtSwitch_DCFR 3 "SNA" 1 "True" 0 "False" ;
VAL_ 648 doorMirrorState_DCFR 7 "SNA" 4 "Retracting" 3 "Retracted" 2 "Presenting" 1 "Presented" 0 "Unknown" ;
VAL_ 648 doorState_DCFR 15 "SNA" 9 "DoorCinchingFailure" 8 "DoorUnlatchingError" 7 "DoorClosingError" 6 "DoorOpeningError" 5 "DoorClosingObstruction" 4 "DoorOpeningObstruction" 3 "DoorClosing" 2 "DoorOpening" 1 "DoorOpen" 0 "DoorClosed" ;
VAL_ 648 mirrorHeaterState_DCFR 3 "SNA" 2 "Fault" 1 "On" 0 "Off" ;
VAL_ 648 sideRepeaterState_DCFR 3 "SNA" 2 "LightFault" 1 "LightOn" 0 "LightOff" ;
VAL_ 648 windowStatusFr_DCFR 5 "TempShutoff" 7 "SNA" 4 "Error" 3 "WindowRollingDown" 2 "WindowRollingUp" 1 "WindowOpen" 0 "WindowClosed" ;
VAL_ 648 mirrorFoldFeedbackRight_DCFR 3 "SNA" 2 "FoldIn" 1 "FoldOut" 0 "NoCommand" ;
VAL_ 648 mirrorDefrostGlassStatusRh_DCFR 3 "SNA" 2 "Error" 1 "On" 0 "Off" ;
VAL_ 648 mirrorStatusMovUpDownRight_DCFR 3 "SNA" 2 "MovingDown" 1 "MovingUp" 0 "NotMoving" ;
VAL_ 648 mirrorStatusMovInOutRight_DCFR 3 "SNA" 2 "MovingOut" 1 "MovingIn" 0 "NotMoving" ;
VAL_ 648 mirrorDefrostCamStatusRight_DCFR 3 "SNA" 2 "Error" 1 "On" 0 "Off" ;
VAL_ 648 mirrorFoldAutoStatusRight_DCFR 3 "SNA" 2 "Error" 1 "On" 0 "Off" ;
VAL_ 648 mirrorDimEnabDisableStatus_DCFR 3 "SNA" 2 "Error" 1 "On" 0 "Off" ;
VAL_ 648 errorAMPFR_DCFR 1 "True" 0 "False" ;
VAL_ 648 errorALDFR_DCFR 1 "True" 0 "False" ;
VAL_ 648 wakeUpCause_DCFR 7 "SNA" 4 "Fbcm" 3 "ExtDoorOpenSw" 2 "IntOpenCloseSw" 1 "IntDoorReleaseSw" 0 "Unknown" ;
VAL_ 649 windowReqAll_DCFR 7 "SNA" 6 "AutoUp" 5 "AutoDown" 2 "PropUp" 1 "PropDown" 0 "NoCommand" ;
VAL_ 649 windowReqRearLeft_DCFR 7 "SNA" 6 "AutoUp" 5 "AutoDown" 2 "PropUp" 1 "PropDown" 0 "NoCommand" ;
VAL_ 649 windowReqRearRight_DCFR 7 "SNA" 6 "AutoUp" 5 "AutoDown" 2 "PropUp" 1 "PropDown" 0 "NoCommand" ;
VAL_ 649 windowReqFrontLeft_DCFR 7 "SNA" 6 "AutoUp" 5 "AutoDown" 2 "PropUp" 1 "PropDown" 0 "NoCommand" ;
VAL_ 649 windowReqFrontRight_DCFR 7 "SNA" 6 "AutoUp" 5 "AutoDown" 2 "PropUp" 1 "PropDown" 0 "NoCommand" ;
VAL_ 649 extPassRearRelease_DCFR 3 "SNA" 2 "Fault" 1 "Pressed" 0 "Unpressed" ;
VAL_ 649 intPassRearRelease_DCFR 3 "SNA" 2 "Fault" 1 "Pressed" 0 "Unpressed" ;
VAL_ 649 frontRightPresentReq_DCFR 3 "SNA" 2 "Fault" 1 "Pressed" 0 "Unpressed" ;
VAL_ 649 rearRightPresentReq_DCFR 3 "SNA" 2 "Fault" 1 "Pressed" 0 "Unpressed" ;
VAL_ 651 autoDoorLockStatus_DCFR 3 "SNA" 1 "True" 0 "False" ;
VAL_ 651 autoMirrorTiltStatus_DCFR 3 "SNA" 1 "True" 0 "False" ;
VAL_ 660 seatHeatVentStatusFR_PSM 7 "SNA" 6 "VentHigh" 5 "VentMedium" 4 "VentLow" 3 "HeatHigh" 2 "HeatMedium" 1 "HeatLow" 0 "Off" ;
VAL_ 660 seatCushionMassageStatusFR_PSM 3 "SNA" 1 "On" 0 "Off" ;
VAL_ 660 seatBackMassageStatusFR_PSM 3 "SNA" 1 "On" 0 "Off" ;
VAL_ 660 seatMsgIntensityStatusFR_PSM 7 "SNA" 5 "5" 4 "4" 3 "3" 2 "2" 1 "1" 0 "0" ;
VAL_ 660 seatMassageTypeStatusFR_PSM 7 "SNA" 3 "Type3" 2 "Type2" 1 "Type1" 0 "Off" ;
VAL_ 660 seatFrontRightOccupied_PSM 3 "SNA" 1 "True" 0 "False" ;
VAL_ 660 seatInitStatus_PSM 3 "SNA" 1 "InitStatusFault" 0 "InitStatusNoFault" ;
VAL_ 660 seatVBatPowerStatus_PSM 3 "SNA" 1 "VbatMotorFault" 0 "VbatMotorNoFault" ;
VAL_ 660 seatVBatEleStatus_PSM 3 "SNA" 1 "VbatComfortFault" 0 "VbatComfortNoFault" ;
VAL_ 660 seatFaultStatus_PSM 3 "SNA" 2 "FaultStatusFaultFailure" 1 "FaultStatusFaultWarning" 0 "FaultStatusNoFault" ;
VAL_ 660 seatAntiPanicStatus_PSM 3 "SNA" 2 "AntiPanicStatusUnused" 1 "AntiPanicStatusActive" 0 "AntiPanicStatusInactive" ;
VAL_ 692 seatHeatVentStatusRL_RLSM 7 "SNA" 6 "VentHigh" 5 "VentMedium" 4 "VentLow" 3 "HeatHigh" 2 "HeatMedium" 1 "HeatLow" 0 "Off" ;
VAL_ 692 seatCushionMassageStatusRL_RLSM 3 "SNA" 1 "On" 0 "Off" ;
VAL_ 692 seatBackMassageStatusRL_RLSM 3 "SNA" 1 "On" 0 "Off" ;
VAL_ 692 seatMsgIntensityStatusRL_RLSM 7 "SNA" 5 "5" 4 "4" 3 "3" 2 "2" 1 "1" 0 "0" ;
VAL_ 692 seatMassageTypeStatusRL_RLSM 7 "SNA" 3 "Type3" 2 "Type2" 1 "Type1" 0 "Off" ;
VAL_ 692 seatRearLeftOccupied_RLSM 3 "SNA" 1 "True" 0 "False" ;
VAL_ 692 seatInitStatus_RLSM 3 "SNA" 1 "InitStatusFault" 0 "InitStatusNoFault" ;
VAL_ 692 seatVBatPowerStatus_RLSM 3 "SNA" 1 "VbatMotorFault" 0 "VbatMotorNoFault" ;
VAL_ 692 seatVBatEleStatus_RLSM 3 "SNA" 1 "VbatComfortFault" 0 "VbatComfortNoFault" ;
VAL_ 692 seatFaultStatus_RLSM 3 "SNA" 2 "FaultStatusFaultFailure" 1 "FaultStatusFaultWarning" 0 "FaultStatusNoFault" ;
VAL_ 692 seatAntiPanicStatus_RLSM 3 "SNA" 2 "AntiPanicStatusUnused" 1 "AntiPanicStatusActive" 0 "AntiPanicStatusInactive" ;
VAL_ 724 seatHeatVentStatusRR_RRSM 7 "SNA" 6 "VentHigh" 5 "VentMedium" 4 "VentLow" 3 "HeatHigh" 2 "HeatMedium" 1 "HeatLow" 0 "Off" ;
VAL_ 724 seatCushionMassageStatusRR_RRSM 3 "SNA" 1 "On" 0 "Off" ;
VAL_ 724 seatBackMassageStatusRR_RRSM 3 "SNA" 1 "On" 0 "Off" ;
VAL_ 724 seatMsgIntensityStatusRR_RRSM 7 "SNA" 5 "5" 4 "4" 3 "3" 2 "2" 1 "1" 0 "0" ;
VAL_ 724 seatMassageTypeStatusRR_RRSM 7 "SNA" 3 "Type3" 2 "Type2" 1 "Type1" 0 "Off" ;
VAL_ 724 seatRearRightOccupied_RRSM 3 "SNA" 1 "True" 0 "False" ;
VAL_ 724 seatInitStatus_RRSM 3 "SNA" 1 "InitStatusFault" 0 "InitStatusNoFault" ;
VAL_ 724 seatVBatPowerStatus_RRSM 3 "SNA" 1 "VbatMotorFault" 0 "VbatMotorNoFault" ;
VAL_ 724 seatVBatEleStatus_RRSM 3 "SNA" 1 "VbatComfortFault" 0 "VbatComfortNoFault" ;
VAL_ 724 seatFaultStatus_RRSM 3 "SNA" 2 "FaultStatusFaultFailure" 1 "FaultStatusFaultWarning" 0 "FaultStatusNoFault" ;
VAL_ 724 seatAntiPanicStatus_RRSM 3 "SNA" 2 "AntiPanicStatusUnused" 1 "AntiPanicStatusActive" 0 "AntiPanicStatusInactive" ;
VAL_ 779 sequenceId_BGW 61 "RedCalibration" 60 "GreenCalibration" 59 "BlueCalibration" 58 "PinkCalibration" 255 "SNA" 23 "ReservedC" 22 "ReservedB" 21 "ReservedA" 20 "ChargeComplete" 19 "ScheduledToCharge" 18 "ErrorState" 17 "ChargingInProgress" 16 "PreparingToCharge" 15 "AirportPickupMode" 14 "RndToP" 13 "PtoRnd" 12 "DoorCloseRearRight" 11 "DoorCloseRearLeft" 10 "DoorCloseFrontRight" 9 "DoorCloseFrontLeft" 8 "DoorOpenRearRight" 7 "DoorOpenRearLeft" 6 "DoorOpenFrontRight" 5 "DoorOpenFrontLeft" 4 "Lock" 3 "Unlock" 2 "Sleep" 1 "Awake" 0 "Off" ;
VAL_ 1032 chargeMode_BGW 3 "SNA" 1 "True" 0 "False" ;
VAL_ 1032 accessoryMode_BGW 3 "SNA" 2 "Reserved" 1 "LowAndHighVoltage" 0 "False" ;
VAL_ 1032 remoteMode_BGW 3 "SNA" 2 "Reserved" 1 "LowAndHighVoltage" 0 "False" ;
VAL_ 1032 driveMode_BGW 3 "SNA" 2 "Moving" 1 "Run" 0 "False" ;
VAL_ 1032 wiperCmd_BGW 15 "SNA" 9 "IntermittentMode1" 8 "IntermittentMode2" 7 "IntermittentMode3" 6 "IntermittentMode4" 5 "IntermittentMode5" 4 "ServicePosition" 3 "HighWipes" 2 "LowWipes" 1 "Park" 0 "NoWipe" ;
VAL_ 1032 chassisWakeup_BGW 3 "SNA" 1 "True" 0 "False" ;
VAL_ 1032 driveRequestState_BGW 3 "SNA" 1 "True" 0 "False" ;
VAL_ 1032 accessoryRequestState_BGW 3 "SNA" 1 "True" 0 "False" ;
VAL_ 1032 selfDriveRequestState_BGW 3 "SNA" 1 "True" 0 "False" ;
VAL_ 1032 hornOnReq_BGW 3 "SNA" 1 "True" 0 "False" ;
VAL_ 1032 wiperNozzleDefrostReq_BGW 3 "SNA" 1 "True" 0 "False" ;
VAL_ 1033 mirrorDefrostCameraOnReq_IHUB 3 "SNA" 1 "On" 0 "Off" ;
VAL_ 1033 mirrorDimReq_IHUB 3 "SNA" 2 "Auto" 1 "On" 0 "Off" ;
VAL_ 1033 mirrorFoldInOutReq_IHUB 3 "SNA" 2 "FoldIn" 1 "FoldOut" 0 "NoCommand" ;
VAL_ 1033 defrostMirrorGlassReq_IHUB 3 "SNA" 1 "True" 0 "False" ;
VAL_ 1033 exteriorLightReq_IHUB 7 "SNA" 4 "Auto" 3 "HighBeam" 2 "LowBeam" 1 "Parking" 0 "Off" ;
VAL_ 1033 frunkLockReq_IHUB 3 "SNA" 2 "NoChange" 1 "Unlock" 0 "Lock" ;
VAL_ 1033 liftgateLockReq_IHUB 3 "SNA" 2 "NoChange" 1 "Unlock" 0 "Lock" ;
VAL_ 1033 doorRRLockReq_IHUB 3 "SNA" 2 "NoChange" 1 "Unlock" 0 "Lock" ;
VAL_ 1033 doorRLLockReq_IHUB 3 "SNA" 2 "NoChange" 1 "Unlock" 0 "Lock" ;
VAL_ 1033 doorFRLockReq_IHUB 3 "SNA" 2 "NoChange" 1 "Unlock" 0 "Lock" ;
VAL_ 1033 doorFLLockReq_IHUB 3 "SNA" 2 "NoChange" 1 "Unlock" 0 "Lock" ;
VAL_ 1033 doorRearRightOperation_IHUB 15 "SNA" 7 "PopDoor" 4 "DoorClose" 3 "DoorOpen" 1 "DoorStop" 0 "NoAction" ;
VAL_ 1033 doorRearLeftOperation_IHUB 15 "SNA" 7 "PopDoor" 4 "DoorClose" 3 "DoorOpen" 1 "DoorStop" 0 "NoAction" ;
VAL_ 1033 doorFrontRightOperation_IHUB 15 "SNA" 7 "PopDoor" 4 "DoorClose" 3 "DoorOpen" 1 "DoorStop" 0 "NoAction" ;
VAL_ 1033 doorFrontLeftOperation_IHUB 15 "SNA" 7 "PopDoor" 4 "DoorClose" 3 "DoorOpen" 1 "DoorStop" 0 "NoAction" ;
VAL_ 1033 lightLowBeamOnReq_IHUB 3 "SNA" 1 "TurnLightOn" 0 "TurnLightOff" ;
VAL_ 1033 frontHoodOpen_IHUB 7 "SNA" 3 "Stop" 2 "Open" 1 "Close" 0 "NoAction" ;
VAL_ 1033 fogSwitchRear_IHUB 3 "SNA" 1 "TurnLightOn" 0 "TurnLightOff" ;
VAL_ 1033 fogSwitchFront_IHUB 3 "SNA" 1 "TurnLightOn" 0 "TurnLightOff" ;
VAL_ 1033 steeringHeatEnabled_IHUB 3 "SNA" 1 "True" 0 "False" ;
VAL_ 1035 autoHighBeamStatus_BGW 3 "SNA" 1 "True" 0 "False" ;
VAL_ 1035 liftgateStatus_BGW 15 "SNA" 7 "LiftgateClosingObstruction" 6 "LiftgateOpeningObstruction" 5 "HardwareFault" 4 "LiftgateClosing" 3 "LiftgateOpening" 2 "LiftgateClose" 1 "LiftgateAjar" 0 "LiftgateOpen" ;
VAL_ 1035 doorErrorRR_BGW 3 "SNA" 1 "True" 0 "False" ;
VAL_ 1035 doorErrorRL_BGW 3 "SNA" 1 "True" 0 "False" ;
VAL_ 1035 doorErrorFR_BGW 3 "SNA" 1 "True" 0 "False" ;
VAL_ 1035 doorErrorFL_BGW 3 "SNA" 1 "True" 0 "False" ;
VAL_ 1035 latchTarget_BGW 3 "SNA" 1 "Latch" 0 "NoLatch" ;
VAL_ 1035 doorState_BGW 3 "SNA" 2 "DoorError" 1 "DoorOpen" 0 "DoorClosed" ;
VAL_ 1035 childLockStatus_BGW 3 "SNA" 2 "NoChange" 1 "Unlock" 0 "Lock" ;
VAL_ 1035 wakeUpCause_BGW 31 "SNA" 8 "LiftgateInteriorButton" 7 "IoExpander" 6 "Lin" 5 "WupLine" 4 "Rtc" 3 "ThermalCan" 2 "TelematicsCan" 1 "BodyCan" 0 "UnknownCause" ;
VAL_ 1035 lightFogRearStatus_BGW 3 "SNA" 2 "LightFault" 1 "LightOn" 0 "LightOff" ;
VAL_ 1035 state_BGW 7 "SNA" 5 "EndDriveState" 4 "ExitingDriveState" 3 "DriveState" 2 "DriveAuthorizedState" 1 "DriveLikelyState" 0 "IdleState" ;
VAL_ 1035 doorRLLockStatus_BGW 3 "SNA" 2 "NoChange" 1 "Unlock" 0 "Lock" ;
VAL_ 1035 liftgateLockStatus_BGW 3 "SNA" 2 "NoChange" 1 "Unlock" 0 "Lock" ;
VAL_ 1035 doorRRLockStatus_BGW 3 "SNA" 2 "NoChange" 1 "Unlock" 0 "Lock" ;
VAL_ 1035 doorFRLockStatus_BGW 3 "SNA" 2 "NoChange" 1 "Unlock" 0 "Lock" ;
VAL_ 1035 doorFLLockStatus_BGW 3 "SNA" 2 "NoChange" 1 "Unlock" 0 "Lock" ;
VAL_ 1035 doorSwitchCpillarLeft_BGW 7 "SNA" 4 "DoorStop" 3 "DoorPop" 2 "DoorClose" 1 "DoorOpen" 0 "NoCommand" ;
VAL_ 1035 doorSwitchCpillarRight_BGW 7 "SNA" 4 "DoorStop" 3 "DoorPop" 2 "DoorClose" 1 "DoorOpen" 0 "NoCommand" ;
VAL_ 1035 bodyBusStateNM_BGW 1 "Sleep" 0 "DoNotSleep" ;
VAL_ 1035 tboxBusStateNM_BGW 1 "Sleep" 0 "DoNotSleep" ;
VAL_ 1035 ethernetStateNM_BGW 1 "Sleep" 0 "DoNotSleep" ;
VAL_ 1035 appSleepState_BGW 1 "Sleep" 0 "DoNotSleep" ;
VAL_ 1037 honkThreeTimes_BGW 3 "SNA" 1 "HonkThreeTimes" 0 "NoCommand" ;
VAL_ 1037 flashLights_BGW 3 "SNA" 1 "FlashLights" 0 "NoCommand" ;
VAL_ 1037 lightLowBeamOnReq_BGW 3 "SNA" 1 "TurnLightOn" 0 "TurnLightOff" ;
VAL_ 1037 lightDomeOnReq_BGW 3 "SNA" 1 "TurnLightOn" 0 "TurnLightOff" ;
VAL_ 1037 lightHighBeamOnReq_BGW 3 "SNA" 1 "TurnLightOn" 0 "TurnLightOff" ;
VAL_ 1038 mirrorMoveAbsUpDownRight_BGW 1023 "SNA" ;
VAL_ 1038 mirrorMoveAbsUpDownLeft_BGW 1023 "SNA" ;
VAL_ 1038 mirrorMoveAbsInOutRight_BGW 1023 "SNA" ;
VAL_ 1038 mirrorMoveAbsInOutLeft_BGW 1023 "SNA" ;
VAL_ 1038 steerCommand_BGW 7 "SNA" 4 "Out" 3 "In" 2 "Down" 1 "Up" 0 "NoCommand" ;
VAL_ 1038 mirrorUpDownRight_BGW 3 "SNA" 2 "TiltDown" 1 "TiltUp" 0 "NoCommand" ;
VAL_ 1038 mirrorUpDownLeft_BGW 3 "SNA" 2 "TiltDown" 1 "TiltUp" 0 "NoCommand" ;
VAL_ 1038 mirrorInOutRight_BGW 3 "SNA" 2 "TiltOut" 1 "TiltIn" 0 "NoCommand" ;
VAL_ 1038 mirrorInOutLeft_BGW 3 "SNA" 2 "TiltOut" 1 "TiltIn" 0 "NoCommand" ;
VAL_ 1039 chargeStatus_BPG 15 "SNA" 10 "ChargeRetry" 9 "EvseInterruptedAndPluggedIn" 8 "UserInterruptedAndPluggedIn" 7 "ChargeToTargetAndPluggedIn" 6 "ChargeToTargetAndNotPluggedIn" 5 "ChargeCompleteAndNotPluggedIn" 4 "ChargeCompleteAndPluggedIn" 3 "Faulted" 2 "Charging" 1 "PluggedInAndNotCharging" 0 "NotPluggedIn" ;
VAL_ 1039 fimEndOfDischarge2Eth_BPG 3 "SNA" 2 "InhibitedOnlyRemoteCause" 1 "InhibitedLocalCause" 0 "NotInhibited" ;
VAL_ 1039 fimEndOfDischarge1Eth_BPG 3 "SNA" 2 "InhibitedOnlyRemoteCause" 1 "InhibitedLocalCause" 0 "NotInhibited" ;
VAL_ 1039 rightSeatBeltBcklState_SRS 1 "Buckled" 0 "Unbuckled" ;
VAL_ 1039 leftSeatBeltBcklState_SRS 1 "Buckled" 0 "Unbuckled" ;
VAL_ 1039 lightStopOnReq_PTC 3 "SNA" 1 "True" 0 "False" ;
VAL_ 1039 lowVoltagePowerMode_DABM 7 "SNA" 3 "Disconnected" 2 "ExtremelyLimited" 1 "Limited" 0 "LvAvailable" ;
VAL_ 1039 chargePortOpenAuthorize_BPG 3 "SNA" 1 "True" 0 "False" ;
VAL_ 1041 lightDRLOnReq_FBCM 3 "SNA" 2 "LightFault" 1 "LightOn" 0 "LightOff" ;
VAL_ 1041 lightSync_FBCM 3 "SNA" 2 "LampOff" 1 "LampOn" 0 "NoEffect" ;
VAL_ 1041 lightHighBeamOnReq_FBCM 3 "SNA" 2 "LightFault" 1 "LightOn" 0 "LightOff" ;
VAL_ 1041 lightTurnRightOnReq_FBCM 3 "SNA" 2 "LightFault" 1 "LightOn" 0 "LightOff" ;
VAL_ 1041 lightTurnLeftOnReq_FBCM 3 "SNA" 2 "LightFault" 1 "LightOn" 0 "LightOff" ;
VAL_ 1041 lightLowBeamOnReq_FBCM 3 "SNA" 2 "LightFault" 1 "LightOn" 0 "LightOff" ;
VAL_ 1041 lightHazardActive_FBCM 3 "SNA" 2 "LightFault" 1 "LightOn" 0 "LightOff" ;
VAL_ 1041 lightStopOnReq_FBCM 3 "SNA" 2 "LightFault" 1 "LightOn" 0 "LightOff" ;
VAL_ 1043 turnSigLh_SCCM 1 "On" 0 "Off" ;
VAL_ 1043 turnSigRh_SCCM 1 "On" 0 "Off" ;
VAL_ 1043 laneChangeLh_SCCM 1 "On" 0 "Off" ;
VAL_ 1043 laneChangeRh_SCCM 1 "On" 0 "Off" ;
VAL_ 1043 powerCycle12V_FBCM 3 "SNA" 1 "True" 0 "False" ;
VAL_ 1044 demALCPTLINSignalError_FBCM 3 "SNA" 2 "Untested" 1 "Set" 0 "Cleared" ;
VAL_ 1044 demALCPTLINSignalLoss_FBCM 3 "SNA" 2 "Untested" 1 "Set" 0 "Cleared" ;
VAL_ 1044 demAccessoryRelayFailure_FBCM 3 "SNA" 2 "Untested" 1 "Set" 0 "Cleared" ;
VAL_ 1044 demAccessoryRelayError_FBCM 3 "SNA" 2 "Untested" 1 "Set" 0 "Cleared" ;
VAL_ 1044 demAmbientLightSleepError_FBCM 3 "SNA" 2 "Untested" 1 "Set" 0 "Cleared" ;
VAL_ 1044 demAmbientLightPowerLoss_FBCM 3 "SNA" 2 "Untested" 1 "Set" 0 "Cleared" ;
VAL_ 1044 demBodyCANNetworkLoss_FBCM 3 "SNA" 2 "Untested" 1 "Set" 0 "Cleared" ;
VAL_ 1044 demBrakeFluidIndicatorError_FBCM 3 "SNA" 2 "Untested" 1 "Set" 0 "Cleared" ;
VAL_ 1044 demBrakeLightInputFault_FBCM 3 "SNA" 2 "Untested" 1 "Set" 0 "Cleared" ;
VAL_ 1044 demCIDHallSensorSignalLoss_FBCM 3 "SNA" 2 "Untested" 1 "Set" 0 "Cleared" ;
VAL_ 1044 demCIDHallSensorFast_FBCM 3 "SNA" 2 "Untested" 1 "Set" 0 "Cleared" ;
VAL_ 1044 demCIDHallSensorSlowSignal_FBCM 3 "SNA" 2 "Untested" 1 "Set" 0 "Cleared" ;
VAL_ 1044 demCIDMotorOvercurrent_FBCM 3 "SNA" 2 "Untested" 1 "Set" 0 "Cleared" ;
VAL_ 1044 demCIDMotorUndercurrent_FBCM 3 "SNA" 2 "Untested" 1 "Set" 0 "Cleared" ;
VAL_ 1044 demCIDMotorError_FBCM 3 "SNA" 2 "Untested" 1 "Set" 0 "Cleared" ;
VAL_ 1044 demCIDMotorSignalLoss_FBCM 3 "SNA" 2 "Untested" 1 "Set" 0 "Cleared" ;
VAL_ 1044 demCIDDownMovementFailure_FBCM 3 "SNA" 2 "Untested" 1 "Set" 0 "Cleared" ;
VAL_ 1044 demCIDUpMovementFailure_FBCM 3 "SNA" 2 "Untested" 1 "Set" 0 "Cleared" ;
VAL_ 1044 demCIDDownMovementError_FBCM 3 "SNA" 2 "Untested" 1 "Set" 0 "Cleared" ;
VAL_ 1044 demCIDUpMovementError_FBCM 3 "SNA" 2 "Untested" 1 "Set" 0 "Cleared" ;
VAL_ 1044 demCPDCloseError_FBCM 3 "SNA" 2 "Untested" 1 "Set" 0 "Cleared" ;
VAL_ 1044 demCDPCloseFailure_FBCM 3 "SNA" 2 "Untested" 1 "Set" 0 "Cleared" ;
VAL_ 1044 demCPDOpenFailure_FBCM 3 "SNA" 2 "Untested" 1 "Set" 0 "Cleared" ;
VAL_ 1044 demCPDOpenError_FBCM 3 "SNA" 2 "Untested" 1 "Set" 0 "Cleared" ;
VAL_ 1044 demDomeRLINSignalError_FBCM 3 "SNA" 2 "Untested" 1 "Set" 0 "Cleared" ;
VAL_ 1044 demDomeRLINSignalLoss_FBCM 3 "SNA" 2 "Untested" 1 "Set" 0 "Cleared" ;
VAL_ 1044 demLIN1NetworkDown_FBCM 3 "SNA" 2 "Untested" 1 "Set" 0 "Cleared" ;
VAL_ 1044 demFLIPLLINSignalError_FBCM 3 "SNA" 2 "Untested" 1 "Set" 0 "Cleared" ;
VAL_ 1044 demFLIPLLINSignalLoss_FBCM 3 "SNA" 2 "Untested" 1 "Set" 0 "Cleared" ;
VAL_ 1044 demFLIPRLLINSignalError_FBCM 3 "SNA" 2 "Untested" 1 "Set" 0 "Cleared" ;
VAL_ 1044 demFLIPRLINSignalLoss_FBCM 3 "SNA" 2 "Untested" 1 "Set" 0 "Cleared" ;
VAL_ 1044 demChassisWUPRelayFailure_FBCM 3 "SNA" 2 "Untested" 1 "Set" 0 "Cleared" ;
VAL_ 1042 demDomeFLINError_FBCM 3 "SNA" 2 "Untested" 1 "Set" 0 "Cleared" ;
VAL_ 1042 demFFogLampFault_FBCM 3 "SNA" 2 "Untested" 1 "Set" 0 "Cleared" ;
VAL_ 1042 demFSideMarkersFailure_FBCM 3 "SNA" 2 "Untested" 1 "Set" 0 "Cleared" ;
VAL_ 1042 demFWiperDeicerRelayFailure_FBCM 3 "SNA" 2 "Untested" 1 "Set" 0 "Cleared" ;
VAL_ 1042 demFWiperDeicerRelayError_FBCM 3 "SNA" 2 "Untested" 1 "Set" 0 "Cleared" ;
VAL_ 1042 demHLLDRLError_FBCM 3 "SNA" 2 "Untested" 1 "Set" 0 "Cleared" ;
VAL_ 1042 demHLLDRLMIA_FBCM 3 "SNA" 2 "Untested" 1 "Set" 0 "Cleared" ;
VAL_ 1042 demHLLHazardError_FBCM 3 "SNA" 2 "Untested" 1 "Set" 0 "Cleared" ;
VAL_ 1042 demHLLHazardMIA_FBCM 3 "SNA" 2 "Untested" 1 "Set" 0 "Cleared" ;
VAL_ 1042 demHLLHighBeamError_FBCM 3 "SNA" 2 "Untested" 1 "Set" 0 "Cleared" ;
VAL_ 1042 demHLLHighBeamMIA_FBCM 3 "SNA" 2 "Untested" 1 "Set" 0 "Cleared" ;
VAL_ 1042 demHLLParkError_FBCM 3 "SNA" 2 "Untested" 1 "Set" 0 "Cleared" ;
VAL_ 1042 demHLLParkMIA_FBCM 3 "SNA" 2 "Untested" 1 "Set" 0 "Cleared" ;
VAL_ 1042 demHLLTurnSignalError_FBCM 3 "SNA" 2 "Untested" 1 "Set" 0 "Cleared" ;
VAL_ 1042 demHLLTurnSignalMIA_FBCM 3 "SNA" 2 "Untested" 1 "Set" 0 "Cleared" ;
VAL_ 1042 demHLLLowBeamError_FBCM 3 "SNA" 2 "Untested" 1 "Set" 0 "Cleared" ;
VAL_ 1042 demHLLowBeamMIA_FBCM 3 "SNA" 2 "Untested" 1 "Set" 0 "Cleared" ;
VAL_ 1042 demHLRDRLError_FBCM 3 "SNA" 2 "Untested" 1 "Set" 0 "Cleared" ;
VAL_ 1042 demHLRDRLMIA_FBCM 3 "SNA" 2 "Untested" 1 "Set" 0 "Cleared" ;
VAL_ 1042 demHLRHazardError_FBCM 3 "SNA" 2 "Untested" 1 "Set" 0 "Cleared" ;
VAL_ 1042 demHLRHazardMIA_FBCM 3 "SNA" 2 "Untested" 1 "Set" 0 "Cleared" ;
VAL_ 1042 demHLRHighBeamError_FBCM 3 "SNA" 2 "Untested" 1 "Set" 0 "Cleared" ;
VAL_ 1042 demHLRHighBeamMIA_FBCM 3 "SNA" 2 "Untested" 1 "Set" 0 "Cleared" ;
VAL_ 1042 demHLRParkError_FBCM 3 "SNA" 2 "Untested" 1 "Set" 0 "Cleared" ;
VAL_ 1042 demHLRParkMIA_FBCM 3 "SNA" 2 "Untested" 1 "Set" 0 "Cleared" ;
VAL_ 1042 demHLRTurnSignalError_FBCM 3 "SNA" 2 "Untested" 1 "Set" 0 "Cleared" ;
VAL_ 1042 demHLRTurnSignalMIA_FBCM 3 "SNA" 2 "Untested" 1 "Set" 0 "Cleared" ;
VAL_ 1042 demHLRLowBeamError_FBCM 3 "SNA" 2 "Untested" 1 "Set" 0 "Cleared" ;
VAL_ 1042 demHLRLowBeamMIA_FBCM 3 "SNA" 2 "Untested" 1 "Set" 0 "Cleared" ;
VAL_ 1042 demHazardSwitchLightFault_FBCM 3 "SNA" 2 "Untested" 1 "Set" 0 "Cleared" ;
VAL_ 1042 demHazardSwitchInputFault_FBCM 3 "SNA" 2 "Untested" 1 "Set" 0 "Cleared" ;
VAL_ 1042 demHLWasherPumpError_FBCM 3 "SNA" 2 "Untested" 1 "Set" 0 "Cleared" ;
VAL_ 535 demHLWasherPumpFailure_FBCM 3 "SNA" 2 "Untested" 1 "Set" 0 "Cleared" ;
VAL_ 535 demHomelinkPowerLoss_FBCM 3 "SNA" 2 "Untested" 1 "Set" 0 "Cleared" ;
VAL_ 535 demHomelinkPowerError_FBCM 3 "SNA" 2 "Untested" 1 "Set" 0 "Cleared" ;
VAL_ 535 demHoodLatchError_FBCM 3 "SNA" 2 "Untested" 1 "Set" 0 "Cleared" ;
VAL_ 535 demHoodLatchReleaseError_FBCM 3 "SNA" 2 "Untested" 1 "Set" 0 "Cleared" ;
VAL_ 535 demHornInputFailure_FBCM 3 "SNA" 2 "Untested" 1 "Set" 0 "Cleared" ;
VAL_ 535 demHornLowError_FBCM 3 "SNA" 2 "Untested" 1 "Set" 0 "Cleared" ;
VAL_ 535 demHornFailure_FBCM 3 "SNA" 2 "Untested" 1 "Set" 0 "Cleared" ;
VAL_ 535 demLWMMLINSignalLoss_FBCM 3 "SNA" 2 "Untested" 1 "Set" 0 "Cleared" ;
VAL_ 535 demRLSLINError_FBCM 3 "SNA" 2 "Untested" 1 "Set" 0 "Cleared" ;
VAL_ 535 demSCCMLINSignalLoss_FBCM 3 "SNA" 2 "Untested" 1 "Set" 0 "Cleared" ;
VAL_ 535 demBrakeFluidIndFailure_FBCM 3 "SNA" 2 "Untested" 1 "Set" 0 "Cleared" ;
VAL_ 535 demMLIPLLINSignalError_FBCM 3 "SNA" 2 "Untested" 1 "Set" 0 "Cleared" ;
VAL_ 535 demMLIPLLINSignalLoss_FBCM 3 "SNA" 2 "Untested" 1 "Set" 0 "Cleared" ;
VAL_ 535 demMLIPRLINSignalError_FBCM 3 "SNA" 2 "Untested" 1 "Set" 0 "Cleared" ;
VAL_ 535 demMLIPRLINSignalLoss_FBCM 3 "SNA" 2 "Untested" 1 "Set" 0 "Cleared" ;
VAL_ 535 demDomeFPowerLoss_FBCM 3 "SNA" 2 "Untested" 1 "Set" 0 "Cleared" ;
VAL_ 535 demRLSPowerLoss_FBCM 3 "SNA" 2 "Untested" 1 "Set" 0 "Cleared" ;
VAL_ 535 demRCLLParkError_FBCM 3 "SNA" 2 "Untested" 1 "Set" 0 "Cleared" ;
VAL_ 535 demRCLLParkMIA_FBCM 3 "SNA" 2 "Untested" 1 "Set" 0 "Cleared" ;
VAL_ 535 demRCLLHazardError_FBCM 3 "SNA" 2 "Untested" 1 "Set" 0 "Cleared" ;
VAL_ 535 demRCLLHazardMIA_FBCM 3 "SNA" 2 "Untested" 1 "Set" 0 "Cleared" ;
VAL_ 535 demRCLLStopError_FBCM 3 "SNA" 2 "Untested" 1 "Set" 0 "Cleared" ;
VAL_ 535 demRCLLStopMIA_FBCM 3 "SNA" 2 "Untested" 1 "Set" 0 "Cleared" ;
VAL_ 535 demRCLLTailError_FBCM 3 "SNA" 2 "Untested" 1 "Set" 0 "Cleared" ;
VAL_ 535 demRCLLTailMIA_FBCM 3 "SNA" 2 "Untested" 1 "Set" 0 "Cleared" ;
VAL_ 535 demRCLLTurnSignalError_FBCM 3 "SNA" 2 "Untested" 1 "Set" 0 "Cleared" ;
VAL_ 535 demRCLLTurnSignalMIA_FBCM 3 "SNA" 2 "Untested" 1 "Set" 0 "Cleared" ;
VAL_ 535 demRCLRParkError_FBCM 3 "SNA" 2 "Untested" 1 "Set" 0 "Cleared" ;
VAL_ 535 demRCLRParkMIA_FBCM 3 "SNA" 2 "Untested" 1 "Set" 0 "Cleared" ;
VAL_ 535 demRCLRHazardError_FBCM 3 "SNA" 2 "Untested" 1 "Set" 0 "Cleared" ;
VAL_ 535 demRCLRHazardMIA_FBCM 3 "SNA" 2 "Untested" 1 "Set" 0 "Cleared" ;
VAL_ 533 demRLSLINLoss_FBCM 3 "SNA" 2 "Untested" 1 "Set" 0 "Cleared" ;
VAL_ 533 demHLWasherPumpOVC_FBCM 3 "SNA" 2 "Untested" 1 "Set" 0 "Cleared" ;
VAL_ 533 demRCLRStopError_FBCM 3 "SNA" 2 "Untested" 1 "Set" 0 "Cleared" ;
VAL_ 533 demRCLRStopMIA_FBCM 3 "SNA" 2 "Untested" 1 "Set" 0 "Cleared" ;
VAL_ 533 demRCLRTailError_FBCM 3 "SNA" 2 "Untested" 1 "Set" 0 "Cleared" ;
VAL_ 533 demRCLRTailMIA_FBCM 3 "SNA" 2 "Untested" 1 "Set" 0 "Cleared" ;
VAL_ 533 demRCLRTurnSignalError_FBCM 3 "SNA" 2 "Untested" 1 "Set" 0 "Cleared" ;
VAL_ 533 demRCLRTurnSignalMIA_FBCM 3 "SNA" 2 "Untested" 1 "Set" 0 "Cleared" ;
VAL_ 533 demRSCMLLINSignalError_FBCM 3 "SNA" 2 "Untested" 1 "Set" 0 "Cleared" ;
VAL_ 533 demRSCMLINSignalLoss_FBCM 3 "SNA" 2 "Untested" 1 "Set" 0 "Cleared" ;
VAL_ 533 demRSDDownMovementFailure_FBCM 3 "SNA" 2 "Untested" 1 "Set" 0 "Cleared" ;
VAL_ 533 demRSDUpLatchFailure_FBCM 3 "SNA" 2 "Untested" 1 "Set" 0 "Cleared" ;
VAL_ 533 demRSDLatchReleaseFailure_FBCM 3 "SNA" 2 "Untested" 1 "Set" 0 "Cleared" ;
VAL_ 533 demRSDHallSensorSignalLoss_FBCM 3 "SNA" 2 "Untested" 1 "Set" 0 "Cleared" ;
VAL_ 533 demRSDHallSensorSigTooFast_FBCM 3 "SNA" 2 "Untested" 1 "Set" 0 "Cleared" ;
VAL_ 533 demRSDMotorOvercurrent_FBCM 3 "SNA" 2 "Untested" 1 "Set" 0 "Cleared" ;
VAL_ 533 demRSDMotorUndercurrent_FBCM 3 "SNA" 2 "Untested" 1 "Set" 0 "Cleared" ;
VAL_ 533 demRSDMotorCurrentError_FBCM 3 "SNA" 2 "Untested" 1 "Set" 0 "Cleared" ;
VAL_ 533 demRSDMotorSignalLoss_FBCM 3 "SNA" 2 "Untested" 1 "Set" 0 "Cleared" ;
VAL_ 533 demRSDDownMovementError_FBCM 3 "SNA" 2 "Untested" 1 "Set" 0 "Cleared" ;
VAL_ 533 demRSDUpMovementError_FBCM 3 "SNA" 2 "Untested" 1 "Set" 0 "Cleared" ;
VAL_ 533 demRLSPowerError_FBCM 3 "SNA" 2 "Untested" 1 "Set" 0 "Cleared" ;
VAL_ 533 demRSDFullBrakeFailure_FBCM 3 "SNA" 2 "Untested" 1 "Set" 0 "Cleared" ;
VAL_ 533 demRSDFullBrakeError_FBCM 3 "SNA" 2 "Untested" 1 "Set" 0 "Cleared" ;
VAL_ 533 demRSDHalfBrakeError_FBCM 3 "SNA" 2 "Untested" 1 "Set" 0 "Cleared" ;
VAL_ 533 demRSDUpMovementFailure_FBCM 3 "SNA" 2 "Untested" 1 "Set" 0 "Cleared" ;
VAL_ 533 demFSideMarkerError_FBCM 3 "SNA" 2 "Untested" 1 "Set" 0 "Cleared" ;
VAL_ 533 demWasherFluidIndSigError_FBCM 3 "SNA" 2 "Untested" 1 "Set" 0 "Cleared" ;
VAL_ 533 demWasherPumpError_FBCM 3 "SNA" 2 "Untested" 1 "Set" 0 "Cleared" ;
VAL_ 533 demWasherPumpFailure_FBCM 3 "SNA" 2 "Untested" 1 "Set" 0 "Cleared" ;
VAL_ 533 demWasherFluidIndSignalLoss_FBCM 3 "SNA" 2 "Untested" 1 "Set" 0 "Cleared" ;
VAL_ 533 demChassisWUPRelayError_FBCM 3 "SNA" 2 "Untested" 1 "Set" 0 "Cleared" ;
VAL_ 532 fimDisableCIDMovement_FBCM 3 "SNA" 2 "InhibitedOnlyRemoteCause" 1 "InhibitedLocalCause" 0 "NotInhibited" ;
VAL_ 532 fimDisableRSDPowerFoldFunc_FBCM 3 "SNA" 2 "InhibitedOnlyRemoteCause" 1 "InhibitedLocalCause" 0 "NotInhibited" ;
VAL_ 532 fimTailLampService_FBCM 3 "SNA" 2 "InhibitedOnlyRemoteCause" 1 "InhibitedLocalCause" 0 "NotInhibited" ;
VAL_ 532 fimBrakeLightInputFailure_FBCM 3 "SNA" 2 "InhibitedOnlyRemoteCause" 1 "InhibitedLocalCause" 0 "NotInhibited" ;
VAL_ 532 fimHeadLampNotification_FBCM 3 "SNA" 2 "InhibitedOnlyRemoteCause" 1 "InhibitedLocalCause" 0 "NotInhibited" ;
VAL_ 532 fimWiperHlightAutoDisabled_FBCM 3 "SNA" 2 "InhibitedOnlyRemoteCause" 1 "InhibitedLocalCause" 0 "NotInhibited" ;
VAL_ 532 fimDisableHeadlampWasher_FBCM 3 "SNA" 2 "InhibitedOnlyRemoteCause" 1 "InhibitedLocalCause" 0 "NotInhibited" ;
VAL_ 532 fimChargePortDoorNotif_FBCM 3 "SNA" 2 "InhibitedOnlyRemoteCause" 1 "InhibitedLocalCause" 0 "NotInhibited" ;
VAL_ 532 fimWindshieldWasherNotif_FBCM 3 "SNA" 2 "InhibitedOnlyRemoteCause" 1 "InhibitedLocalCause" 0 "NotInhibited" ;
VAL_ 532 fimHeadlampWasherNotif_FBCM 3 "SNA" 2 "InhibitedOnlyRemoteCause" 1 "InhibitedLocalCause" 0 "NotInhibited" ;
VAL_ 532 fimBrakeFluidSensorNotif_FBCM 3 "SNA" 2 "InhibitedOnlyRemoteCause" 1 "InhibitedLocalCause" 0 "NotInhibited" ;
VAL_ 532 fimFogLightNotificaton_FBCM 3 "SNA" 2 "InhibitedOnlyRemoteCause" 1 "InhibitedLocalCause" 0 "NotInhibited" ;
VAL_ 1045 swchStateHighBeam_FBCM 3 "SNA" 1 "True" 0 "False" ;
VAL_ 1045 swchStateWshrMst_SCCM 3 "SNA" 1 "On" 0 "Off" ;
VAL_ 1045 alarmModeHornStatus_FBCM 3 "SNA" 1 "On" 0 "Off" ;
VAL_ 1045 alarmModeHazardStatus_FBCM 3 "SNA" 1 "On" 0 "Off" ;
VAL_ 1045 delcerFrontStatus_FBCM 3 "SNA" 2 "Fault" 1 "On" 0 "Off" ;
VAL_ 1045 chargePortDoorStatus_FBCM 7 "SNA" 5 "DoorFault" 4 "DoorObstructed" 3 "DoorClosing" 2 "DoorOpen" 1 "DoorOpening" 0 "DoorClosed" ;
VAL_ 1045 lightHazardStatus_FBCM 3 "SNA" 1 "On" 0 "Off" ;
VAL_ 1045 lightFogFrontStatus_FBCM 3 "SNA" 2 "LightFault" 1 "LightOn" 0 "LightOff" ;
VAL_ 1045 lightDomeStatus_FBCM 3 "SNA" 2 "LightFault" 1 "LightOn" 0 "LightOff" ;
VAL_ 1045 brakeFluidLevel_FBCM 3 "SNA" 1 "Low" 0 "Off" ;
VAL_ 1045 lightFogFrontRightStatus_FBCM 3 "SNA" 2 "LightFault" 1 "LightOn" 0 "LightOff" ;
VAL_ 1045 lightFogFrontLeftStatus_FBCM 3 "SNA" 2 "LightFault" 1 "LightOn" 0 "LightOff" ;
VAL_ 1045 wiperStatus_LWMM 15 "SNA" 10 "WiperFailure" 9 "IntermittentMode1" 8 "IntermittentMode2" 7 "IntermittentMode3" 6 "IntermittentMode4" 5 "IntermittentMode5" 4 "ServicePosition" 3 "HighWipes" 2 "LowWipes" 1 "Parked" 0 "NoWipe" ;
VAL_ 1045 washerFluidLevel_FBCM 3 "SNA" 1 "Low" 0 "Off" ;
VAL_ 1045 hornStatus_FBCM 3 "SNA" 2 "Fault" 1 "HornOn" 0 "HornOff" ;
VAL_ 1045 stateVehicle_FBCM 7 "SNA" 4 "SelfDriveState" 3 "DriveState" 2 "AccessoryState" 1 "StandbyState" 0 "SleepState" ;
VAL_ 1045 frontTrunkStatus_FBCM 3 "SNA" 2 "Ambiguous" 1 "Open" 0 "Closed" ;
VAL_ 1045 lockRejected_FBCM 3 "SNA" 1 "LockRejected" 0 "LockNotRejected" ;
VAL_ 1045 lightFSMStatus_FBCM 3 "SNA" 2 "LightFault" 1 "LightOn" 0 "LightOff" ;
VAL_ 1045 wakeUpCause_FBCM 5 "HornSwitch" 7 "SNA" 4 "Dcfr" 3 "Dcfl" 2 "Bgw" 1 "HazardLights" 0 "Unknown" ;
VAL_ 1045 steeringHeatStatus_FBCM 3 "SNA" 1 "True" 0 "False" ;
VAL_ 1046 humidityGlassFront_RLS 255 "SNA" ;
VAL_ 1046 tempHumidityAir_RLS 255 "SNA" ;
VAL_ 1046 tempGlassFront_RLS 255 "SNA" ;
VAL_ 1046 tempDewPointAir_RLS 255 "SNA" ;
VAL_ 1046 powerSolarRight_RLS 255 "SNA" ;
VAL_ 1046 powerSolarLeft_RLS 255 "SNA" ;
